VERSION ""

NS_ :

BS_:

BU_: L_3HKBD L_FHPTC L_2HKBD L_ATCU L_PCM L_EVNT L_HKBD L_RHPTC

BO_ 1032 L_EVNT_08: 8 L_EVNT
 SG_ L_EVNT_ATCUComFlt : 0|2@1+ (1,0) [0|0] ""  L_ATCU
 SG_ L_EVNT_DrvCntrHorComFlt : 10|2@1+ (1,0) [0|0] ""  L_ATCU
 SG_ L_EVNT_AstSdVertComFlt : 12|2@1+ (1,0) [0|0] ""  L_ATCU
 SG_ L_EVNT_AstSdHorComFlt : 14|2@1+ (1,0) [0|0] ""  L_ATCU
 SG_ L_EVNT_AstCntrVertComFlt : 16|2@1+ (1,0) [0|0] ""  L_ATCU
 SG_ L_EVNT_AstCntrHorComFlt : 18|2@1+ (1,0) [0|0] ""  L_ATCU
 SG_ L_EVNT_EVNTFlt : 2|2@1+ (1,0) [0|0] ""  L_ATCU
 SG_ L_EVNT_RrDrvCnslVertComFlt : 20|2@1+ (1,0) [0|0] ""  L_ATCU
 SG_ L_EVNT_RrDrvCnslHorComFlt : 22|2@1+ (1,0) [0|0] ""  L_ATCU
 SG_ L_EVNT_RrAstCnslVertComFlt : 24|2@1+ (1,0) [0|0] ""  L_ATCU
 SG_ L_EVNT_RrAstCnslHorComFlt : 26|2@1+ (1,0) [0|0] ""  L_ATCU
 SG_ L_EVNT_DrvSdVertIntFlt : 28|2@1+ (1,0) [0|0] ""  L_ATCU
 SG_ L_EVNT_DrvSdHorIntFlt : 30|2@1+ (1,0) [0|0] ""  L_ATCU
 SG_ L_EVNT_DrvCntrVertIntFlt : 32|2@1+ (1,0) [0|0] ""  L_ATCU
 SG_ L_EVNT_DrvCntrHorIntFlt : 34|2@1+ (1,0) [0|0] ""  L_ATCU
 SG_ L_EVNT_AstSdVertIntFlt : 36|2@1+ (1,0) [0|0] ""  L_ATCU
 SG_ L_EVNT_AstSdHorIntFlt : 38|2@1+ (1,0) [0|0] ""  L_ATCU
 SG_ L_EVNT_DrvSdVertComFlt : 4|2@1+ (1,0) [0|0] ""  L_ATCU
 SG_ L_EVNT_AstCntrVertIntFlt : 40|2@1+ (1,0) [0|0] ""  L_ATCU
 SG_ L_EVNT_AstCntrHorIntFlt : 42|2@1+ (1,0) [0|0] ""  L_ATCU
 SG_ L_EVNT_RrDrvCnslVertIntFlt : 44|2@1+ (1,0) [0|0] ""  L_ATCU
 SG_ L_EVNT_RrDrvCnslHorIntFlt : 46|2@1+ (1,0) [0|0] ""  L_ATCU
 SG_ L_EVNT_RrAstCnslVertIntFlt : 48|2@1+ (1,0) [0|0] ""  L_ATCU
 SG_ L_EVNT_RrAstCnslHorIntFlt : 50|2@1+ (1,0) [0|0] ""  L_ATCU
 SG_ L_EVNT_DrvSdVertExtFlt : 52|2@1+ (1,0) [0|0] ""  L_ATCU
 SG_ L_EVNT_DrvSdHorExtFlt : 54|2@1+ (1,0) [0|0] ""  L_ATCU
 SG_ L_EVNT_DrvCntrVertExtFlt : 56|2@1+ (1,0) [0|0] ""  L_ATCU
 SG_ L_EVNT_DrvCntrHorExtFlt : 58|2@1+ (1,0) [0|0] ""  L_ATCU
 SG_ L_EVNT_DrvSdHorComFlt : 6|2@1+ (1,0) [0|0] ""  L_ATCU
 SG_ L_EVNT_AstSdVertExtFlt : 60|2@1+ (1,0) [0|0] ""  L_ATCU
 SG_ L_EVNT_AstSdHorExtFlt : 62|2@1+ (1,0) [0|0] ""  L_ATCU
 SG_ L_EVNT_DrvCntrVertComFlt : 8|2@1+ (1,0) [0|0] ""  L_ATCU

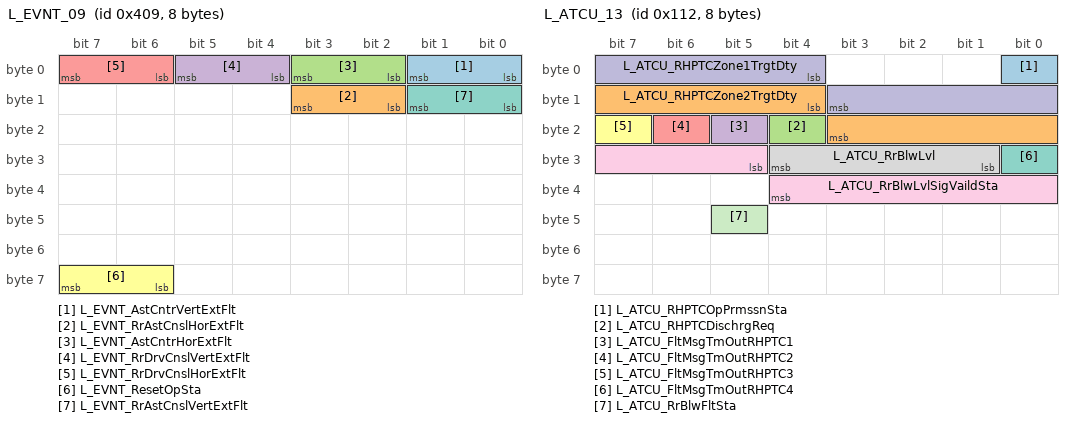
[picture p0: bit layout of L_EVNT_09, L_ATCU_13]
BO_ 1033 L_EVNT_09: 8 L_EVNT
 SG_ L_EVNT_AstCntrVertExtFlt : 0|2@1+ (1,0) [0|0] ""  L_ATCU
 SG_ L_EVNT_RrAstCnslHorExtFlt : 10|2@1+ (1,0) [0|0] ""  L_ATCU
 SG_ L_EVNT_AstCntrHorExtFlt : 2|2@1+ (1,0) [0|0] ""  L_ATCU
 SG_ L_EVNT_RrDrvCnslVertExtFlt : 4|2@1+ (1,0) [0|0] ""  L_ATCU
 SG_ L_EVNT_RrDrvCnslHorExtFlt : 6|2@1+ (1,0) [0|0] ""  L_ATCU
 SG_ L_EVNT_ResetOpSta : 62|2@1+ (1,0) [0|0] ""  L_ATCU
 SG_ L_EVNT_RrAstCnslVertExtFlt : 8|2@1+ (1,0) [0|0] ""  L_ATCU

BO_ 274 L_ATCU_13: 8 L_ATCU
 SG_ L_ATCU_RHPTCOpPrmssnSta : 0|1@1+ (1,0) [0|0] ""  L_FHPTC,L_RHPTC
 SG_ L_ATCU_RHPTCZone2TrgtDty : 12|8@1+ (0.5,0) [0|0] "%"  L_FHPTC,L_RHPTC
 SG_ L_ATCU_RHPTCDischrgReq : 20|1@1+ (1,0) [0|0] ""  L_FHPTC,L_RHPTC
 SG_ L_ATCU_FltMsgTmOutRHPTC1 : 21|1@1+ (1,0) [0|0] ""  L_FHPTC,L_RHPTC
 SG_ L_ATCU_FltMsgTmOutRHPTC2 : 22|1@1+ (1,0) [0|0] ""  L_FHPTC,L_RHPTC
 SG_ L_ATCU_FltMsgTmOutRHPTC3 : 23|1@1+ (1,0) [0|0] ""  L_FHPTC,L_RHPTC
 SG_ L_ATCU_FltMsgTmOutRHPTC4 : 24|1@1+ (1,0) [0|0] ""  L_FHPTC,L_RHPTC
 SG_ L_ATCU_RrBlwLvl : 25|4@1+ (1,0) [0|0] ""  L_EVNT,L_FHPTC,L_RHPTC
 SG_ L_ATCU_RrBlwLvlSigVaildSta : 29|8@1+ (1,0) [0|0] ""  L_FHPTC,L_RHPTC
 SG_ L_ATCU_RHPTCZone1TrgtDty : 4|8@1+ (0.5,0) [0|0] "%"  L_FHPTC,L_RHPTC
 SG_ L_ATCU_RrBlwFltSta : 45|1@1+ (1,0) [0|0] ""  L_FHPTC,L_RHPTC

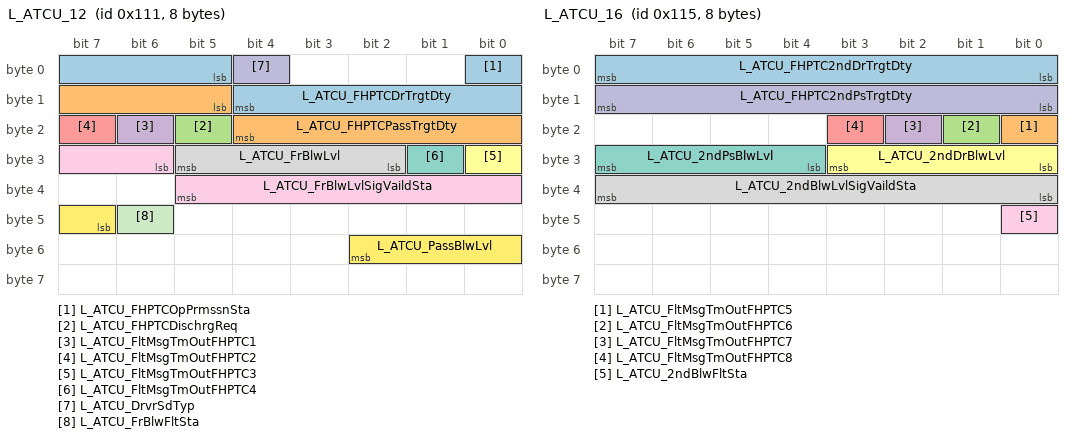
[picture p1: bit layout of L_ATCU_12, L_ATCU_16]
BO_ 273 L_ATCU_12: 8 L_ATCU
 SG_ L_ATCU_FHPTCOpPrmssnSta : 0|1@1+ (1,0) [0|0] ""  L_FHPTC,L_RHPTC
 SG_ L_ATCU_FHPTCPassTrgtDty : 13|8@1+ (0.5,0) [0|0] "%"  L_FHPTC,L_RHPTC
 SG_ L_ATCU_FHPTCDischrgReq : 21|1@1+ (1,0) [0|0] ""  L_FHPTC,L_RHPTC
 SG_ L_ATCU_FltMsgTmOutFHPTC1 : 22|1@1+ (1,0) [0|0] ""  L_FHPTC,L_RHPTC
 SG_ L_ATCU_FltMsgTmOutFHPTC2 : 23|1@1+ (1,0) [0|0] ""  L_FHPTC,L_RHPTC
 SG_ L_ATCU_FltMsgTmOutFHPTC3 : 24|1@1+ (1,0) [0|0] ""  L_FHPTC,L_RHPTC
 SG_ L_ATCU_FltMsgTmOutFHPTC4 : 25|1@1+ (1,0) [0|0] ""  L_FHPTC,L_RHPTC
 SG_ L_ATCU_FrBlwLvl : 26|4@1+ (1,0) [0|0] ""  L_EVNT,L_FHPTC,L_RHPTC
 SG_ L_ATCU_FrBlwLvlSigVaildSta : 30|8@1+ (1,0) [0|0] ""  L_FHPTC,L_RHPTC
 SG_ L_ATCU_DrvrSdTyp : 4|1@1+ (1,0) [0|0] ""  L_EVNT,L_FHPTC,L_HKBD,L_RHPTC
 SG_ L_ATCU_FrBlwFltSta : 46|1@1+ (1,0) [0|0] ""  L_FHPTC,L_RHPTC
 SG_ L_ATCU_PassBlwLvl : 47|4@1+ (1,0) [0|0] ""  L_EVNT,L_FHPTC,L_RHPTC
 SG_ L_ATCU_FHPTCDrTrgtDty : 5|8@1+ (0.5,0) [0|0] "%"  L_FHPTC,L_RHPTC

BO_ 277 L_ATCU_16: 8 L_ATCU
 SG_ L_ATCU_FHPTC2ndDrTrgtDty : 0|8@1+ (0.5,0) [0|0] "%"  L_FHPTC,L_RHPTC
 SG_ L_ATCU_FltMsgTmOutFHPTC5 : 16|1@1+ (1,0) [0|0] ""  L_FHPTC,L_RHPTC
 SG_ L_ATCU_FltMsgTmOutFHPTC6 : 17|1@1+ (1,0) [0|0] ""  L_FHPTC,L_RHPTC
 SG_ L_ATCU_FltMsgTmOutFHPTC7 : 18|1@1+ (1,0) [0|0] ""  L_FHPTC,L_RHPTC
 SG_ L_ATCU_FltMsgTmOutFHPTC8 : 19|1@1+ (1,0) [0|0] ""  L_FHPTC,L_RHPTC
 SG_ L_ATCU_2ndDrBlwLvl : 24|4@1+ (1,0) [0|0] ""  L_EVNT,L_FHPTC,L_RHPTC
 SG_ L_ATCU_2ndPsBlwLvl : 28|4@1+ (1,0) [0|0] ""  L_EVNT,L_FHPTC,L_RHPTC
 SG_ L_ATCU_2ndBlwLvlSigVaildSta : 32|8@1+ (1,0) [0|0] ""  L_FHPTC,L_RHPTC
 SG_ L_ATCU_2ndBlwFltSta : 40|1@1+ (1,0) [0|0] ""  L_FHPTC,L_RHPTC
 SG_ L_ATCU_FHPTC2ndPsTrgtDty : 8|8@1+ (0.5,0) [0|0] "%"  L_FHPTC,L_RHPTC

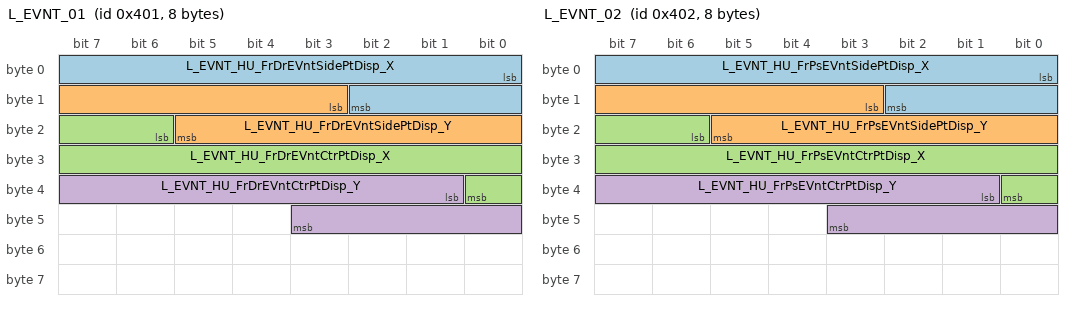
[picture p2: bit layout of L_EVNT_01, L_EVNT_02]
BO_ 1025 L_EVNT_01: 8 L_EVNT
 SG_ L_EVNT_HU_FrDrEVntSidePtDisp_X : 0|11@1+ (1,0) [0|0] ""  L_ATCU
 SG_ L_EVNT_HU_FrDrEVntSidePtDisp_Y : 11|11@1+ (1,0) [0|0] ""  L_ATCU
 SG_ L_EVNT_HU_FrDrEVntCtrPtDisp_X : 22|11@1+ (1,0) [0|0] ""  L_ATCU
 SG_ L_EVNT_HU_FrDrEVntCtrPtDisp_Y : 33|11@1+ (1,0) [0|0] ""  L_ATCU

BO_ 1026 L_EVNT_02: 8 L_EVNT
 SG_ L_EVNT_HU_FrPsEVntSidePtDisp_X : 0|11@1+ (1,0) [0|0] ""  L_ATCU
 SG_ L_EVNT_HU_FrPsEVntSidePtDisp_Y : 11|11@1+ (1,0) [0|0] ""  L_ATCU
 SG_ L_EVNT_HU_FrPsEVntCtrPtDisp_X : 22|11@1+ (1,0) [0|0] ""  L_ATCU
 SG_ L_EVNT_HU_FrPsEVntCtrPtDisp_Y : 33|11@1+ (1,0) [0|0] ""  L_ATCU

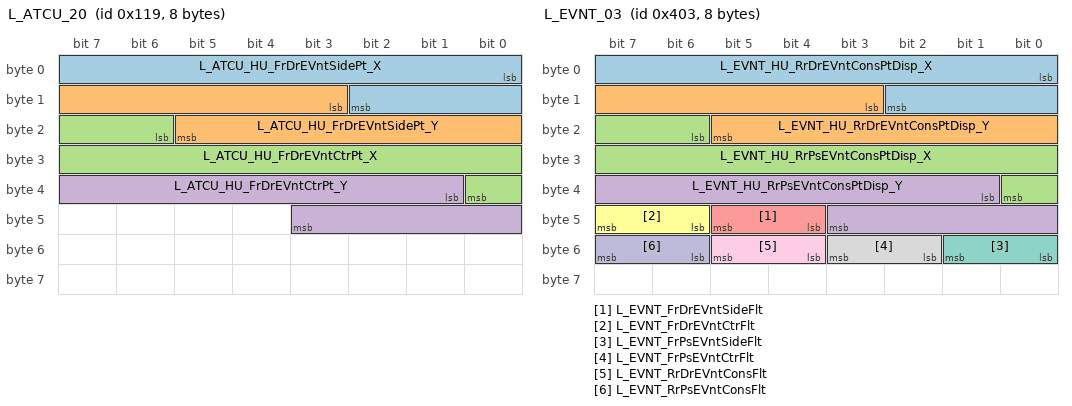
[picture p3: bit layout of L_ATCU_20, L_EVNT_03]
BO_ 281 L_ATCU_20: 8 L_ATCU
 SG_ L_ATCU_HU_FrDrEVntSidePt_X : 0|11@1+ (1,0) [0|0] ""  L_EVNT
 SG_ L_ATCU_HU_FrDrEVntSidePt_Y : 11|11@1+ (1,0) [0|0] ""  L_EVNT
 SG_ L_ATCU_HU_FrDrEVntCtrPt_X : 22|11@1+ (1,0) [0|0] ""  L_EVNT
 SG_ L_ATCU_HU_FrDrEVntCtrPt_Y : 33|11@1+ (1,0) [0|0] ""  L_EVNT

BO_ 1027 L_EVNT_03: 8 L_EVNT
 SG_ L_EVNT_HU_RrDrEVntConsPtDisp_X : 0|11@1+ (1,0) [0|0] ""  L_ATCU
 SG_ L_EVNT_HU_RrDrEVntConsPtDisp_Y : 11|11@1+ (1,0) [0|0] ""  L_ATCU
 SG_ L_EVNT_HU_RrPsEVntConsPtDisp_X : 22|11@1+ (1,0) [0|0] ""  L_ATCU
 SG_ L_EVNT_HU_RrPsEVntConsPtDisp_Y : 33|11@1+ (1,0) [0|0] ""  L_ATCU
 SG_ L_EVNT_FrDrEVntSideFlt : 44|2@1+ (1,0) [0|0] ""  L_ATCU
 SG_ L_EVNT_FrDrEVntCtrFlt : 46|2@1+ (1,0) [0|0] ""  L_ATCU
 SG_ L_EVNT_FrPsEVntSideFlt : 48|2@1+ (1,0) [0|0] ""  L_ATCU
 SG_ L_EVNT_FrPsEVntCtrFlt : 50|2@1+ (1,0) [0|0] ""  L_ATCU
 SG_ L_EVNT_RrDrEVntConsFlt : 52|2@1+ (1,0) [0|0] ""  L_ATCU
 SG_ L_EVNT_RrPsEVntConsFlt : 54|2@1+ (1,0) [0|0] ""  L_ATCU

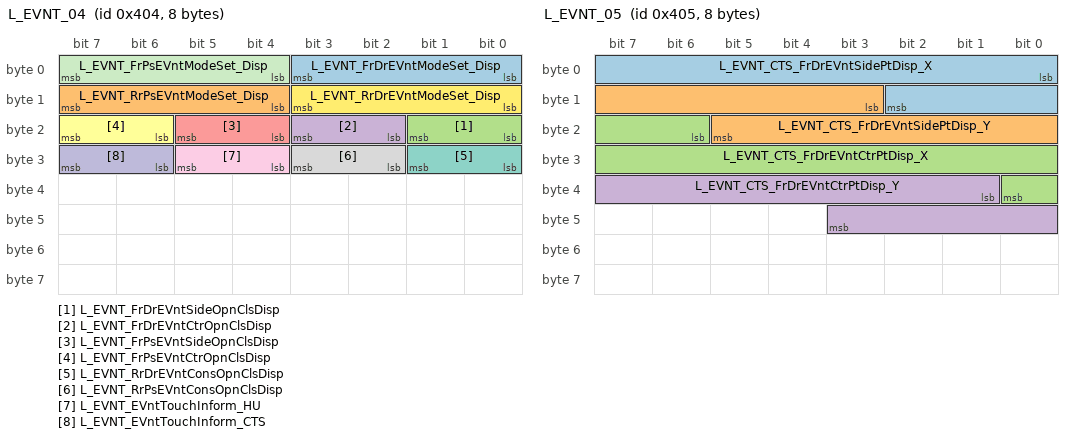
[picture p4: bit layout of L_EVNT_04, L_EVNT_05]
BO_ 1028 L_EVNT_04: 8 L_EVNT
 SG_ L_EVNT_FrDrEVntModeSet_Disp : 0|4@1+ (1,0) [0|0] ""  L_ATCU
 SG_ L_EVNT_RrPsEVntModeSet_Disp : 12|4@1+ (1,0) [0|0] ""  L_ATCU
 SG_ L_EVNT_FrDrEVntSideOpnClsDisp : 16|2@1+ (1,0) [0|0] ""  L_ATCU
 SG_ L_EVNT_FrDrEVntCtrOpnClsDisp : 18|2@1+ (1,0) [0|0] ""  L_ATCU
 SG_ L_EVNT_FrPsEVntSideOpnClsDisp : 20|2@1+ (1,0) [0|0] ""  L_ATCU
 SG_ L_EVNT_FrPsEVntCtrOpnClsDisp : 22|2@1+ (1,0) [0|0] ""  L_ATCU
 SG_ L_EVNT_RrDrEVntConsOpnClsDisp : 24|2@1+ (1,0) [0|0] ""  L_ATCU
 SG_ L_EVNT_RrPsEVntConsOpnClsDisp : 26|2@1+ (1,0) [0|0] ""  L_ATCU
 SG_ L_EVNT_EVntTouchInform_HU : 28|2@1+ (1,0) [0|0] ""  L_ATCU
 SG_ L_EVNT_EVntTouchInform_CTS : 30|2@1+ (1,0) [0|0] ""  L_ATCU
 SG_ L_EVNT_FrPsEVntModeSet_Disp : 4|4@1+ (1,0) [0|0] ""  L_ATCU
 SG_ L_EVNT_RrDrEVntModeSet_Disp : 8|4@1+ (1,0) [0|0] ""  L_ATCU

BO_ 1029 L_EVNT_05: 8 L_EVNT
 SG_ L_EVNT_CTS_FrDrEVntSidePtDisp_X : 0|11@1+ (1,0) [0|0] ""  L_ATCU
 SG_ L_EVNT_CTS_FrDrEVntSidePtDisp_Y : 11|11@1+ (1,0) [0|0] ""  L_ATCU
 SG_ L_EVNT_CTS_FrDrEVntCtrPtDisp_X : 22|11@1+ (1,0) [0|0] ""  L_ATCU
 SG_ L_EVNT_CTS_FrDrEVntCtrPtDisp_Y : 33|11@1+ (1,0) [0|0] ""  L_ATCU

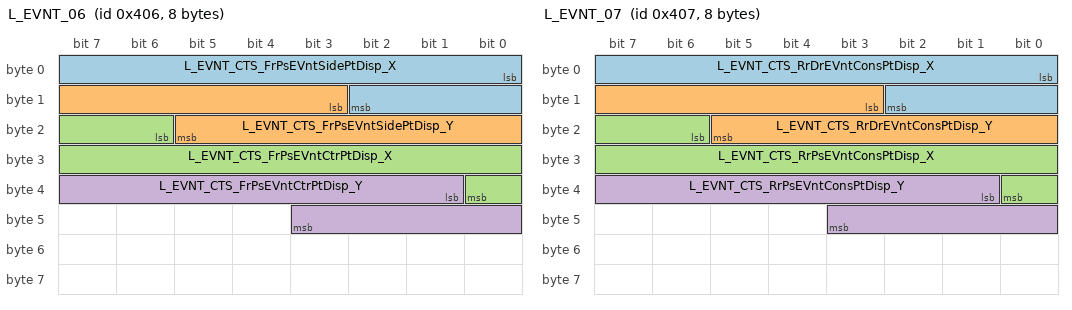
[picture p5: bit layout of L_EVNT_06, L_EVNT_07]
BO_ 1030 L_EVNT_06: 8 L_EVNT
 SG_ L_EVNT_CTS_FrPsEVntSidePtDisp_X : 0|11@1+ (1,0) [0|0] ""  L_ATCU
 SG_ L_EVNT_CTS_FrPsEVntSidePtDisp_Y : 11|11@1+ (1,0) [0|0] ""  L_ATCU
 SG_ L_EVNT_CTS_FrPsEVntCtrPtDisp_X : 22|11@1+ (1,0) [0|0] ""  L_ATCU
 SG_ L_EVNT_CTS_FrPsEVntCtrPtDisp_Y : 33|11@1+ (1,0) [0|0] ""  L_ATCU

BO_ 1031 L_EVNT_07: 8 L_EVNT
 SG_ L_EVNT_CTS_RrDrEVntConsPtDisp_X : 0|11@1+ (1,0) [0|0] ""  L_ATCU
 SG_ L_EVNT_CTS_RrDrEVntConsPtDisp_Y : 11|11@1+ (1,0) [0|0] ""  L_ATCU
 SG_ L_EVNT_CTS_RrPsEVntConsPtDisp_X : 22|11@1+ (1,0) [0|0] ""  L_ATCU
 SG_ L_EVNT_CTS_RrPsEVntConsPtDisp_Y : 33|11@1+ (1,0) [0|0] ""  L_ATCU

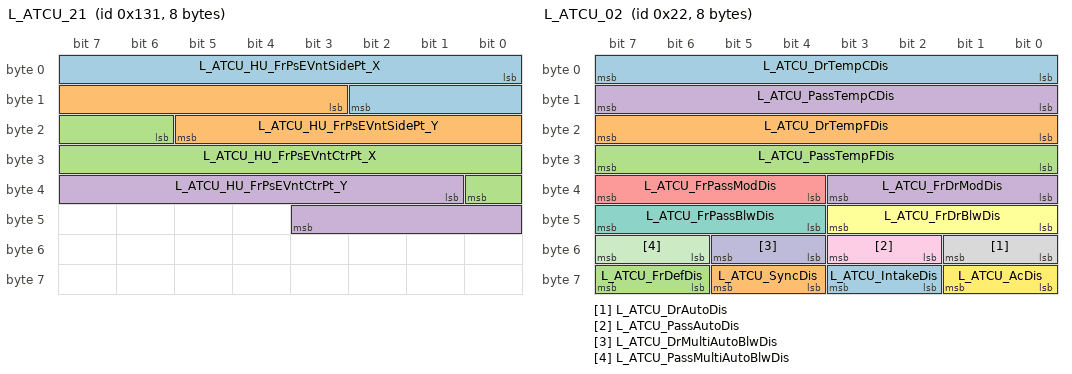
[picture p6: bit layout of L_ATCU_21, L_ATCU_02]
BO_ 305 L_ATCU_21: 8 L_ATCU
 SG_ L_ATCU_HU_FrPsEVntSidePt_X : 0|11@1+ (1,0) [0|0] ""  L_EVNT
 SG_ L_ATCU_HU_FrPsEVntSidePt_Y : 11|11@1+ (1,0) [0|0] ""  L_EVNT
 SG_ L_ATCU_HU_FrPsEVntCtrPt_X : 22|11@1+ (1,0) [0|0] ""  L_EVNT
 SG_ L_ATCU_HU_FrPsEVntCtrPt_Y : 33|11@1+ (1,0) [0|0] ""  L_EVNT

BO_ 34 L_ATCU_02: 8 L_ATCU
 SG_ L_ATCU_DrTempCDis : 0|8@1+ (0.5,14) [0|0] "¡É"  L_HKBD
 SG_ L_ATCU_DrTempFDis : 16|8@1+ (1,56) [0|0] "¢µ"  L_HKBD
 SG_ L_ATCU_PassTempFDis : 24|8@1+ (1,56) [0|0] "¢µ"  L_HKBD
 SG_ L_ATCU_FrDrModDis : 32|4@1+ (1,0) [0|0] ""  L_EVNT,L_HKBD
 SG_ L_ATCU_FrPassModDis : 36|4@1+ (1,0) [0|0] ""  L_EVNT,L_HKBD
 SG_ L_ATCU_FrDrBlwDis : 40|4@1+ (1,0) [0|0] ""  L_HKBD
 SG_ L_ATCU_FrPassBlwDis : 44|4@1+ (1,0) [0|0] ""  L_HKBD
 SG_ L_ATCU_DrAutoDis : 48|2@1+ (1,0) [0|0] ""  L_HKBD
 SG_ L_ATCU_PassAutoDis : 50|2@1+ (1,0) [0|0] ""  L_HKBD
 SG_ L_ATCU_DrMultiAutoBlwDis : 52|2@1+ (1,0) [0|0] ""  L_HKBD
 SG_ L_ATCU_PassMultiAutoBlwDis : 54|2@1+ (1,0) [0|0] ""  L_HKBD
 SG_ L_ATCU_AcDis : 56|2@1+ (1,0) [0|0] ""  L_HKBD
 SG_ L_ATCU_IntakeDis : 58|2@1+ (1,0) [0|0] ""  L_HKBD
 SG_ L_ATCU_SyncDis : 60|2@1+ (1,0) [0|0] ""  L_HKBD
 SG_ L_ATCU_FrDefDis : 62|2@1+ (1,0) [0|0] ""  L_HKBD
 SG_ L_ATCU_PassTempCDis : 8|8@1+ (0.5,14) [0|0] "¡É"  L_HKBD

BO_ 35 L_ATCU_03: 8 L_ATCU
 SG_ L_ATCU_DrOnlyDis : 0|2@1+ (1,0) [0|0] ""  L_HKBD
 SG_ L_ATCU_SmrtVntDis : 11|2@1+ (1,0) [0|0] ""  L_HKBD
 SG_ L_ATCU_FrWndShldHtInd : 13|2@1+ (1,0) [0|0] ""  L_HKBD
 SG_ L_ATCU_IncarMtrOnReq : 15|1@1+ (1,0) [0|0] ""  L_HKBD
 SG_ L_ATCU_LanguageInfo : 16|8@1+ (1,0) [0|0] ""  L_HKBD
 SG_ L_ATCU_RrDefInd : 2|1@1+ (1,0) [0|0] ""  L_HKBD
 SG_ L_ATCU_AfterBlowDisplay : 24|2@1+ (1,0) [0|0] ""  L_HKBD
 SG_ L_ATCU_SchdldVentDisplay : 26|2@1+ (1,0) [0|0] ""  L_HKBD
 SG_ L_ATCU_FLStHeatSwHInd : 28|1@1+ (1,0) [0|0] ""  L_HKBD
 SG_ L_ATCU_FLStHeatSwMInd : 29|1@1+ (1,0) [0|0] ""  L_HKBD
 SG_ L_ATCU_ADSBlinkDis : 3|2@1+ (1,0) [0|0] ""  L_HKBD
 SG_ L_ATCU_FLStHeatSwLInd : 30|1@1+ (1,0) [0|0] ""  L_HKBD
 SG_ L_ATCU_FLStVntSwHInd : 31|1@1+ (1,0) [0|0] ""  L_HKBD
 SG_ L_ATCU_FLStVntSwMInd : 32|1@1+ (1,0) [0|0] ""  L_HKBD
 SG_ L_ATCU_FLStVntSwLInd : 33|1@1+ (1,0) [0|0] ""  L_HKBD
 SG_ L_ATCU_FRStHeatSwHInd : 34|1@1+ (1,0) [0|0] ""  L_HKBD
 SG_ L_ATCU_FRStHeatSwMInd : 35|1@1+ (1,0) [0|0] ""  L_HKBD
 SG_ L_ATCU_FRStHeatSwLInd : 36|1@1+ (1,0) [0|0] ""  L_HKBD
 SG_ L_ATCU_FRStVntSwHInd : 37|1@1+ (1,0) [0|0] ""  L_HKBD
 SG_ L_ATCU_FRStVntSwMInd : 38|1@1+ (1,0) [0|0] ""  L_HKBD
 SG_ L_ATCU_FRStVntSwLInd : 39|1@1+ (1,0) [0|0] ""  L_HKBD
 SG_ L_ATCU_StrWhlHeatInd : 40|2@1+ (1,0) [0|0] ""  L_HKBD
 SG_ L_ATCU_RhstaLvlSta : 42|5@1+ (1,0) [0|0] ""  L_2HKBD,L_EVNT,L_HKBD
 SG_ L_ATCU_IntTailOnOff : 47|1@1+ (1,0) [0|0] ""  L_2HKBD,L_HKBD
 SG_ L_ATCU_AutoLightSta : 48|1@1+ (1,0) [0|0] ""  L_HKBD
 SG_ L_ATCU_FrBckLightSta : 49|1@1+ (1,0) [0|0] ""  L_HKBD
 SG_ L_ATCU_DisplayTheme : 50|2@1+ (1,0) [0|0] ""  L_HKBD
 SG_ L_ATCU_GUIBlankDis : 52|1@1+ (1,0) [0|0] ""  L_HKBD
 SG_ L_ATCU_HptIntnstySet : 53|4@1+ (1,0) [0|0] ""  L_HKBD
 SG_ L_ATCU_TlltLmpDis : 57|3@1+ (1,0) [0|0] ""  L_HKBD
 SG_ L_ATCU_AvTailOnOff : 60|1@1+ (1,0) [0|0] ""  L_HKBD
 SG_ L_ATCU_SchdldClimateDisplay : 61|2@1+ (1,0) [0|0] ""  L_HKBD
 SG_ L_ATCU_AirClnDis : 7|2@1+ (1,0) [0|0] ""  L_HKBD
 SG_ L_ATCU_CO2WrngDis : 9|2@1+ (1,0) [0|0] ""  L_HKBD

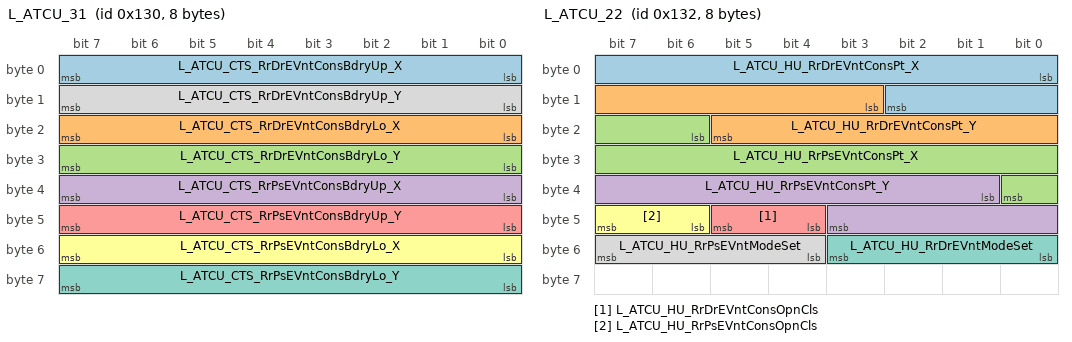
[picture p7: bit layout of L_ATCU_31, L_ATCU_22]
BO_ 304 L_ATCU_31: 8 L_ATCU
 SG_ L_ATCU_CTS_RrDrEVntConsBdryUp_X : 0|8@1+ (10,0) [0|0] ""  L_EVNT
 SG_ L_ATCU_CTS_RrDrEVntConsBdryLo_X : 16|8@1+ (10,0) [0|0] ""  L_EVNT
 SG_ L_ATCU_CTS_RrDrEVntConsBdryLo_Y : 24|8@1+ (10,0) [0|0] ""  L_EVNT
 SG_ L_ATCU_CTS_RrPsEVntConsBdryUp_X : 32|8@1+ (10,0) [0|0] ""  L_EVNT
 SG_ L_ATCU_CTS_RrPsEVntConsBdryUp_Y : 40|8@1+ (10,0) [0|0] ""  L_EVNT
 SG_ L_ATCU_CTS_RrPsEVntConsBdryLo_X : 48|8@1+ (10,0) [0|0] ""  L_EVNT
 SG_ L_ATCU_CTS_RrPsEVntConsBdryLo_Y : 56|8@1+ (10,0) [0|0] ""  L_EVNT
 SG_ L_ATCU_CTS_RrDrEVntConsBdryUp_Y : 8|8@1+ (10,0) [0|0] ""  L_EVNT

BO_ 306 L_ATCU_22: 8 L_ATCU
 SG_ L_ATCU_HU_RrDrEVntConsPt_X : 0|11@1+ (1,0) [0|0] ""  L_EVNT
 SG_ L_ATCU_HU_RrDrEVntConsPt_Y : 11|11@1+ (1,0) [0|0] ""  L_EVNT
 SG_ L_ATCU_HU_RrPsEVntConsPt_X : 22|11@1+ (1,0) [0|0] ""  L_EVNT
 SG_ L_ATCU_HU_RrPsEVntConsPt_Y : 33|11@1+ (1,0) [0|0] ""  L_EVNT
 SG_ L_ATCU_HU_RrDrEVntConsOpnCls : 44|2@1+ (1,0) [0|0] ""  L_EVNT
 SG_ L_ATCU_HU_RrPsEVntConsOpnCls : 46|2@1+ (1,0) [0|0] ""  L_EVNT
 SG_ L_ATCU_HU_RrDrEVntModeSet : 48|4@1+ (1,0) [0|0] ""  L_EVNT
 SG_ L_ATCU_HU_RrPsEVntModeSet : 52|4@1+ (1,0) [0|0] ""  L_EVNT

CM_ BO_ 34 "[PE] Periodic and On Event";
CM_ SG_ 34 L_ATCU_DrTempCDis "ATCU_DrvierTemperatureDisplay(¡É)";
CM_ SG_ 34 L_ATCU_DrTempFDis "ATCU_DriverTemperatureDisplay(¢µ)";
CM_ SG_ 34 L_ATCU_PassTempFDis "ATCU_PassengerTemperatureDisplay(¢µ)";
CM_ SG_ 34 L_ATCU_FrDrModDis "ATCU_FrontDriverModeDisplay";
CM_ SG_ 34 L_ATCU_FrPassModDis "ATCU_FrontPassengerModeDisplay";
CM_ SG_ 34 L_ATCU_FrDrBlwDis "ATCU_FrontDriverBlowerDisplay";
CM_ SG_ 34 L_ATCU_FrPassBlwDis "ATCU_FrontPassengerBlowerDisplay";
CM_ SG_ 34 L_ATCU_DrAutoDis "ATCU_DriverAutoDisplay";
CM_ SG_ 34 L_ATCU_PassAutoDis "ATCU_PassengerAutoDisplay";
CM_ SG_ 34 L_ATCU_DrMultiAutoBlwDis "ATCU_DriverMultiAutoBlowerDisplay";
CM_ SG_ 34 L_ATCU_PassMultiAutoBlwDis "ATCU_PassengerMultiAutoBlowerDisplay";
CM_ SG_ 34 L_ATCU_AcDis "ATCU_AcDisplay";
CM_ SG_ 34 L_ATCU_IntakeDis "ATCU_IntakeDisplay";
CM_ SG_ 34 L_ATCU_SyncDis "ATCU_SyncDisplay";
CM_ SG_ 34 L_ATCU_FrDefDis "ATCU_FrontDefrostDisplay";
CM_ SG_ 34 L_ATCU_PassTempCDis "ATCU_PassengerTemperatureDisplay(¡É)";
CM_ BO_ 35 "[PE] Periodic and On Event";
CM_ SG_ 35 L_ATCU_DrOnlyDis "ATCU_DriverOnlyDisplay";
CM_ SG_ 35 L_ATCU_SmrtVntDis "ATCU_SmartVentilationDisplay";
CM_ SG_ 35 L_ATCU_FrWndShldHtInd "ATCU_FrontWindShieldHeaterIndicator";
CM_ SG_ 35 L_ATCU_IncarMtrOnReq "ATCU_IncarMotorOnRequest";
CM_ SG_ 35 L_ATCU_LanguageInfo "ATCU_LanguageInformation";
CM_ SG_ 35 L_ATCU_RrDefInd "ATCU_RearDEFIndicator";
CM_ SG_ 35 L_ATCU_AfterBlowDisplay "ATCU_AfterBlow Display";
CM_ SG_ 35 L_ATCU_SchdldVentDisplay "ATCU_SchduledVentDispaly";
CM_ SG_ 35 L_ATCU_FLStHeatSwHInd "ATCU_FrontLeftSeatHeatSwitchHighIndicator";
CM_ SG_ 35 L_ATCU_FLStHeatSwMInd "ATCU_FrontLeftSeatHeatSwitchMiddleIndicator";
CM_ SG_ 35 L_ATCU_ADSBlinkDis "ATCU_ADSBlinkDisplay";
CM_ SG_ 35 L_ATCU_FLStHeatSwLInd "ATCU_FrontLeftSeatHeatSwitchLowIndicator";
CM_ SG_ 35 L_ATCU_FLStVntSwHInd "ATCU_FrontLeftSeatVentilationSwitchHighIndicator";
CM_ SG_ 35 L_ATCU_FLStVntSwMInd "ATCU_FrontLeftSeatVentilationSwitchMiddleIndicator";
CM_ SG_ 35 L_ATCU_FLStVntSwLInd "ATCU_FrontLeftSeatVentilationSwitchLowIndicator";
CM_ SG_ 35 L_ATCU_FRStHeatSwHInd "ATCU_FrontRightSeatHeatSwitchHighIndicator";
CM_ SG_ 35 L_ATCU_FRStHeatSwMInd "ATCU_FrontRightSeatHeatSwitchMiddleIndicator";
CM_ SG_ 35 L_ATCU_FRStHeatSwLInd "ATCU_FrontRightSeatHeatSwitchLowIndicator";
CM_ SG_ 35 L_ATCU_FRStVntSwHInd "ATCU_FrontRightSeatVentilationSwitchHighIndicator";
CM_ SG_ 35 L_ATCU_FRStVntSwMInd "ATCU_FrontRightSeatVentilationSwitchMiddleIndicator";
CM_ SG_ 35 L_ATCU_FRStVntSwLInd "ATCU_FrontRightSeatVentilationSwitchLowIndicator";
CM_ SG_ 35 L_ATCU_StrWhlHeatInd "ATCU_SteeringWheelHeatIndicator";
CM_ SG_ 35 L_ATCU_RhstaLvlSta "ATCU_RheostatLevelStatus";
CM_ SG_ 35 L_ATCU_IntTailOnOff "ATCU_InternalTailOnOff";
CM_ SG_ 35 L_ATCU_AutoLightSta "ATCU_AutoLightStatus";
CM_ SG_ 35 L_ATCU_FrBckLightSta "ATCU_FrontBackLightStatus";
CM_ SG_ 35 L_ATCU_DisplayTheme "ATCU_DisplayTheme";
CM_ SG_ 35 L_ATCU_GUIBlankDis "ATCU_GUIBlankDisplay";
CM_ SG_ 35 L_ATCU_HptIntnstySet "ATCU_HapticIntensityLevelSet";
CM_ SG_ 35 L_ATCU_TlltLmpDis "ATCU_TelltaleLampDisplay";
CM_ SG_ 35 L_ATCU_AvTailOnOff "ATCU_AVTailOnOff";
CM_ SG_ 35 L_ATCU_SchdldClimateDisplay "ATCU_ScheduledClimateDisplay";
CM_ SG_ 35 L_ATCU_AirClnDis "ATCU_AirCleaningDisplay";
CM_ SG_ 35 L_ATCU_CO2WrngDis "ATCU_CO2WarningDisplay";
CM_ BO_ 273 "[P] Periodic";
CM_ SG_ 273 L_ATCU_FHPTCOpPrmssnSta "ATCU_FHPTCOperationPermissionStatus";
CM_ SG_ 273 L_ATCU_FHPTCPassTrgtDty "ATCU_FHPTCPassengerTargetDuty";
CM_ SG_ 273 L_ATCU_FHPTCDischrgReq "ATCU_FHPTCDischrgeRequest";
CM_ SG_ 273 L_ATCU_FltMsgTmOutFHPTC1 "ATCU_FltMsgTmOutFHPTC1";
CM_ SG_ 273 L_ATCU_FltMsgTmOutFHPTC2 "ATCU_FltMsgTmOutFHPTC2";
CM_ SG_ 273 L_ATCU_FltMsgTmOutFHPTC3 "ATCU_FltMsgTmOutFHPTC3";
CM_ SG_ 273 L_ATCU_FltMsgTmOutFHPTC4 "ATCU_FltMsgTmOutFHPTC4";
CM_ SG_ 273 L_ATCU_FrBlwLvl "ATCU_FrBlowerLevel";
CM_ SG_ 273 L_ATCU_FrBlwLvlSigVaildSta "ATCU_FrBlowrLevelSignalVaildStatus";
CM_ SG_ 273 L_ATCU_DrvrSdTyp "ATCU_DriverSideType";
CM_ SG_ 273 L_ATCU_FrBlwFltSta "ATCU_FrontBlowerFaultStatus";
CM_ SG_ 273 L_ATCU_PassBlwLvl "ATCU_PasssengerBlowerLevel";
CM_ SG_ 273 L_ATCU_FHPTCDrTrgtDty "ATCU_FHPTCDriverTargetDuty";
CM_ BO_ 274 "[P] Periodic";
CM_ SG_ 274 L_ATCU_RHPTCOpPrmssnSta "ATCU_RHPTCOperationPermissionStatus";
CM_ SG_ 274 L_ATCU_RHPTCZone2TrgtDty "ATCU_RHPTCZone2TargetDuty";
CM_ SG_ 274 L_ATCU_RHPTCDischrgReq "ATCU_RHPTCDischrgeRequest";
CM_ SG_ 274 L_ATCU_FltMsgTmOutRHPTC1 "ATCU_FltMsgTmOutRHPTC1";
CM_ SG_ 274 L_ATCU_FltMsgTmOutRHPTC2 "ATCU_FltMsgTmOutRHPTC2";
CM_ SG_ 274 L_ATCU_FltMsgTmOutRHPTC3 "ATCU_FltMsgTmOutRHPTC3";
CM_ SG_ 274 L_ATCU_FltMsgTmOutRHPTC4 "ATCU_FltMsgTmOutRHPTC4";
CM_ SG_ 274 L_ATCU_RrBlwLvl "ATCU_RrBlowerLevel";
CM_ SG_ 274 L_ATCU_RrBlwLvlSigVaildSta "ATCU_RrBlowrLevelSignalVaildStatus";
CM_ SG_ 274 L_ATCU_RHPTCZone1TrgtDty "ATCU_RHPTCZone1TargetDuty";
CM_ SG_ 274 L_ATCU_RrBlwFltSta "ATCU_BlowerFaultStatus";
CM_ BO_ 277 "[P] Periodic";
CM_ SG_ 277 L_ATCU_FHPTC2ndDrTrgtDty "ATCU_FHPTC 2nd Driver Target Duty";
CM_ SG_ 277 L_ATCU_FltMsgTmOutFHPTC5 "ATCU_FltMsgTmOutFHPTC5";
CM_ SG_ 277 L_ATCU_FltMsgTmOutFHPTC6 "ATCU_FltMsgTmOutFHPTC6";
CM_ SG_ 277 L_ATCU_FltMsgTmOutFHPTC7 "ATCU_FltMsgTmOutFHPTC7";
CM_ SG_ 277 L_ATCU_FltMsgTmOutFHPTC8 "ATCU_FltMsgTmOutFHPTC8";
CM_ SG_ 277 L_ATCU_2ndDrBlwLvl "ATCU_2ndDriverBlowerLevel";
CM_ SG_ 277 L_ATCU_2ndPsBlwLvl "ATCU_2ndPassengerBlowerLevel";
CM_ SG_ 277 L_ATCU_2ndBlwLvlSigVaildSta "ATCU_2ndBlowerLevelSignalVaildStatus";
CM_ SG_ 277 L_ATCU_2ndBlwFltSta "ATCU_2ndBlowerFaultStatus";
CM_ SG_ 277 L_ATCU_FHPTC2ndPsTrgtDty "ATCU_FHPTC 2nd Passenger Target Duty";
CM_ BO_ 281 "[EC] On Event and On Change";
CM_ SG_ 281 L_ATCU_HU_FrDrEVntSidePt_X "Front Driver Electric Vent Side Touch Point  X Value";
CM_ SG_ 281 L_ATCU_HU_FrDrEVntSidePt_Y "Front Driver Electric Vent Side Touch Point  Y Value";
CM_ SG_ 281 L_ATCU_HU_FrDrEVntCtrPt_X "Front Driver Electric Vent Center Touch Point  X Value";
CM_ SG_ 281 L_ATCU_HU_FrDrEVntCtrPt_Y "Front Driver Electric Vent Center Touch Point  Y Value";
CM_ BO_ 305 "[EC] On Event and On Change";
CM_ SG_ 305 L_ATCU_HU_FrPsEVntSidePt_X "Front Passenger Electric Vent Side Touch Point  X Value";
CM_ SG_ 305 L_ATCU_HU_FrPsEVntSidePt_Y "Front Passenger Electric Vent Side Touch Point  Y Value";
CM_ SG_ 305 L_ATCU_HU_FrPsEVntCtrPt_X "Front Passenger Electric Center Vent Touch Point  X Value";
CM_ SG_ 305 L_ATCU_HU_FrPsEVntCtrPt_Y "Front Passenger Electric Center Vent Touch Point  Y Value";
CM_ BO_ 306 "[EC] On Event and On Change";
CM_ SG_ 306 L_ATCU_HU_RrDrEVntConsPt_X "Rear Driver Electric Vent Console Touch Point  X Value";
CM_ SG_ 306 L_ATCU_HU_RrDrEVntConsPt_Y "Rear Driver Electric Vent Console Touch Point  Y Value";
CM_ SG_ 306 L_ATCU_HU_RrPsEVntConsPt_X "Rear Passenger Electric Vent Console Touch Point  X Value";
CM_ SG_ 306 L_ATCU_HU_RrPsEVntConsPt_Y "Rear Passenger Electric Vent Console Touch Point  Y Value";
CM_ SG_ 306 L_ATCU_HU_RrDrEVntConsOpnCls "Rear Driver Electric Vent Console Open Close Signal";
CM_ SG_ 306 L_ATCU_HU_RrPsEVntConsOpnCls "Rear Passenger Electric Vent Console Open Close Signal";
CM_ SG_ 306 L_ATCU_HU_RrDrEVntModeSet "Rear Driver Electric Vent Mode Set";
CM_ SG_ 306 L_ATCU_HU_RrPsEVntModeSet "Rear Passenger Electric Vent Mode Set";
CM_ BO_ 304 "[P] Periodic";
CM_ SG_ 304 L_ATCU_CTS_RrDrEVntConsBdryUp_X "Rear Driver Electric Vent Console Boundary Upper X Point";
CM_ SG_ 304 L_ATCU_CTS_RrDrEVntConsBdryLo_X "Rear Driver Electric Vent Console Boundary Lower X Point";
CM_ SG_ 304 L_ATCU_CTS_RrDrEVntConsBdryLo_Y "Rear Driver Electric Vent Console Boundary Lower Y Point";
CM_ SG_ 304 L_ATCU_CTS_RrPsEVntConsBdryUp_X "Rear Passenger Electric Vent Console Boundary Upper X Point";
CM_ SG_ 304 L_ATCU_CTS_RrPsEVntConsBdryUp_Y "Rear Passenger Electric Vent Console Boundary Upper Y Point";
CM_ SG_ 304 L_ATCU_CTS_RrPsEVntConsBdryLo_X "Rear Passenger Electric Vent Console Boundary Lower X Point";
CM_ SG_ 304 L_ATCU_CTS_RrPsEVntConsBdryLo_Y "Rear Passenger Electric Vent Console Boundary Lower Y Point";
CM_ SG_ 304 L_ATCU_CTS_RrDrEVntConsBdryUp_Y "Rear Driver Electric Vent Console Boundary Upper Y Point";
CM_ BO_ 1025 "[PE] Periodic and On Event";
CM_ SG_ 1025 L_EVNT_HU_FrDrEVntSidePtDisp_X "Front Driver Electric Vent Side Touch Point  X Value Display Feedback";
CM_ SG_ 1025 L_EVNT_HU_FrDrEVntSidePtDisp_Y "Front Driver Electric Vent Side Touch Point  Y Value Display Feedback";
CM_ SG_ 1025 L_EVNT_HU_FrDrEVntCtrPtDisp_X "Front Driver Electric Vent Center Touch Point  X Value Display Feedback";
CM_ SG_ 1025 L_EVNT_HU_FrDrEVntCtrPtDisp_Y "Front Driver Electric Vent Center Touch Point  Y Value Display Feedback";
CM_ BO_ 1026 "[PE] Periodic and On Event";
CM_ SG_ 1026 L_EVNT_HU_FrPsEVntSidePtDisp_X "Front Passenger Electric Vent Side Touch Point  X Value Display Feedback";
CM_ SG_ 1026 L_EVNT_HU_FrPsEVntSidePtDisp_Y "Front Passenger Electric Vent Side Touch Point  Y Value Display Feedback";
CM_ SG_ 1026 L_EVNT_HU_FrPsEVntCtrPtDisp_X "Front Passenger Electric Center Vent Touch Point  X Value Display Feedback";
CM_ SG_ 1026 L_EVNT_HU_FrPsEVntCtrPtDisp_Y "Front Passenger Electric Center Vent Touch Point  Y Value Display Feedback";
CM_ BO_ 1027 "[PE] Periodic and On Event";
CM_ SG_ 1027 L_EVNT_HU_RrDrEVntConsPtDisp_X "Rear Driver Electric Vent Console Touch Point  X Value Display Feedback";
CM_ SG_ 1027 L_EVNT_HU_RrDrEVntConsPtDisp_Y "Rear Driver Electric Vent Console Touch Point  Y Value Display Feedback";
CM_ SG_ 1027 L_EVNT_HU_RrPsEVntConsPtDisp_X "Rear Passenger Electric Vent Console Touch Point  X Value Display Feedback";
CM_ SG_ 1027 L_EVNT_HU_RrPsEVntConsPtDisp_Y "Rear Passenger Electric Vent Console Touch Point  Y Value Display Feedback";
CM_ SG_ 1027 L_EVNT_FrDrEVntSideFlt "Front Driver Electric Vent Side Fault Status";
CM_ SG_ 1027 L_EVNT_FrDrEVntCtrFlt "Front Driver Electric Vent Center Fault Status";
CM_ SG_ 1027 L_EVNT_FrPsEVntSideFlt "Front Passenger Electric Vent Side Fault Status";
CM_ SG_ 1027 L_EVNT_FrPsEVntCtrFlt "Front Passenger Electric Vent Center Fault Status";
CM_ SG_ 1027 L_EVNT_RrDrEVntConsFlt "Front Rear (2nd) Driver Electric Vent Console Fault Status";
CM_ SG_ 1027 L_EVNT_RrPsEVntConsFlt "Front Rear (2nd) Passenger Electric Vent Console Fault Status";
CM_ BO_ 1028 "[PE] Periodic and On Event";
CM_ SG_ 1028 L_EVNT_FrDrEVntModeSet_Disp "Front Driver Electric Vent Mode Display";
CM_ SG_ 1028 L_EVNT_RrPsEVntModeSet_Disp "Rear Passenger Electric Vent Mode Display";
CM_ SG_ 1028 L_EVNT_FrDrEVntSideOpnClsDisp "Front Driver Electric Vent Side Open Close Display";
CM_ SG_ 1028 L_EVNT_FrDrEVntCtrOpnClsDisp "Front Driver Electric Vent Center Open Close Display";
CM_ SG_ 1028 L_EVNT_FrPsEVntSideOpnClsDisp "Front Passenger Electric Vent Side Open Close Display";
CM_ SG_ 1028 L_EVNT_FrPsEVntCtrOpnClsDisp "Front Passenger Electric Vent Center Open Close Display";
CM_ SG_ 1028 L_EVNT_RrDrEVntConsOpnClsDisp "Rear Driver Electric Vent Console Open Close Display";
CM_ SG_ 1028 L_EVNT_RrPsEVntConsOpnClsDisp "Rear Passenger Electric Vent Open Console Close Display";
CM_ SG_ 1028 L_EVNT_EVntTouchInform_HU "Reply signal indicating whether to allow duplicate input signals for preventing overlapping of electric vent input signals";
CM_ SG_ 1028 L_EVNT_EVntTouchInform_CTS "Reply signal indicating whether to allow duplicate input signals for preventing overlapping of electric vent input signals";
CM_ SG_ 1028 L_EVNT_FrPsEVntModeSet_Disp "Front Passenger Electric Vent Mode Display";
CM_ SG_ 1028 L_EVNT_RrDrEVntModeSet_Disp "Rear Driver Electric Vent Mode Display";
CM_ BO_ 1029 "[PE] Periodic and On Event";
CM_ SG_ 1029 L_EVNT_CTS_FrDrEVntSidePtDisp_X "Front Driver Electric Vent Side Touch Point  X Value Display Feedback";
CM_ SG_ 1029 L_EVNT_CTS_FrDrEVntSidePtDisp_Y "Front Driver Electric Vent Side Touch Point  Y Value Display Feedback";
CM_ SG_ 1029 L_EVNT_CTS_FrDrEVntCtrPtDisp_X "Front Driver Electric Vent Center Touch Point  X Value Display Feedback";
CM_ SG_ 1029 L_EVNT_CTS_FrDrEVntCtrPtDisp_Y "Front Driver Electric Vent Center Touch Point  Y Value Display Feedback";
CM_ BO_ 1030 "[PE] Periodic and On Event";
CM_ SG_ 1030 L_EVNT_CTS_FrPsEVntSidePtDisp_X "Front Passenger Electric Vent Side Touch Point  X Value Display Feedback";
CM_ SG_ 1030 L_EVNT_CTS_FrPsEVntSidePtDisp_Y "Front Passenger Electric Vent Side Touch Point  Y Value Display Feedback";
CM_ SG_ 1030 L_EVNT_CTS_FrPsEVntCtrPtDisp_X "Front Passenger Electric Center Vent Touch Point  X Value Display Feedback";
CM_ SG_ 1030 L_EVNT_CTS_FrPsEVntCtrPtDisp_Y "Front Passenger Electric Center Vent Touch Point  Y Value Display Feedback";
CM_ BO_ 1031 "[PE] Periodic and On Event";
CM_ SG_ 1031 L_EVNT_CTS_RrDrEVntConsPtDisp_X "Rear Driver Electric Vent Console Touch Point  X Value Display Feedback";
CM_ SG_ 1031 L_EVNT_CTS_RrDrEVntConsPtDisp_Y "Rear Driver Electric Vent Console Touch Point  Y Value Display Feedback";
CM_ SG_ 1031 L_EVNT_CTS_RrPsEVntConsPtDisp_X "Rear Passenger Electric Vent Console Touch Point  X Value Display Feedback";
CM_ SG_ 1031 L_EVNT_CTS_RrPsEVntConsPtDisp_Y "Rear Passenger Electric Vent Console Touch Point  Y Value Display Feedback";
CM_ BO_ 1032 "[PE] Periodic and On Event";
CM_ SG_ 1032 L_EVNT_ATCUComFlt "ATCU fault decision of EVNT";
CM_ SG_ 1032 L_EVNT_DrvCntrHorComFlt "LIN-Bus Off DrvierCenter Left/Right - Actuator";
CM_ SG_ 1032 L_EVNT_AstSdVertComFlt "LIN-Bus Off PassengerSide Up/Down -Actuator";
CM_ SG_ 1032 L_EVNT_AstSdHorComFlt "LIN-Bus Off PassengerSide Left/Right - Actuator";
CM_ SG_ 1032 L_EVNT_AstCntrVertComFlt "LIN-Bus Off PassengerCenter Up/Down - Actuator";
CM_ SG_ 1032 L_EVNT_AstCntrHorComFlt "LIN-Bus Off PassengerCenter Left/Right - Actuator";
CM_ SG_ 1032 L_EVNT_EVNTFlt "EVNT fault decision of ATCU";
CM_ SG_ 1032 L_EVNT_RrDrvCnslVertComFlt "LIN-Bus Off RearDrvierCenter Up/Down -Actuator";
CM_ SG_ 1032 L_EVNT_RrDrvCnslHorComFlt "LIN-Bus Off RearDrvierCenter Left/Right -Actuator";
CM_ SG_ 1032 L_EVNT_RrAstCnslVertComFlt "LIN-Bus Off RearPassengerCenter Up/Down -Actuator";
CM_ SG_ 1032 L_EVNT_RrAstCnslHorComFlt "LIN-Bus Off RearPassengerCenter Left/Right -Actuator";
CM_ SG_ 1032 L_EVNT_DrvSdVertIntFlt "DrvierSide Up/Down - Actuator(Internal Error Flag)";
CM_ SG_ 1032 L_EVNT_DrvSdHorIntFlt "DrvierSide Left/Right -Actuator(Internal Error Flag)";
CM_ SG_ 1032 L_EVNT_DrvCntrVertIntFlt "DrvierCenter Up/Down -Actuator(Internal Error Flag)";
CM_ SG_ 1032 L_EVNT_DrvCntrHorIntFlt "DrvierCenter Left/Right - Actuator(Internal Error Flag)";
CM_ SG_ 1032 L_EVNT_AstSdVertIntFlt "PassengerSide Up/Down -Actuator(Internal Error Flag)";
CM_ SG_ 1032 L_EVNT_AstSdHorIntFlt "PassengerSide Left/Right - Actuator(Internal Error Flag)";
CM_ SG_ 1032 L_EVNT_DrvSdVertComFlt "LIN-Bus Off DrvierSide Up/Down - Actuator";
CM_ SG_ 1032 L_EVNT_AstCntrVertIntFlt "PassengerCenter Up/Down - Actuator(Internal Error Flag)";
CM_ SG_ 1032 L_EVNT_AstCntrHorIntFlt "PassengerCenter Left/Right - Actuator(Internal Error Flag)";
CM_ SG_ 1032 L_EVNT_RrDrvCnslVertIntFlt "RearDrvierCenter Up/Down -Actuator(Internal Error Flag)";
CM_ SG_ 1032 L_EVNT_RrDrvCnslHorIntFlt "RearDrvierCenter Left/Right -Actuator(Internal Error Flag)";
CM_ SG_ 1032 L_EVNT_RrAstCnslVertIntFlt "RearPassengerCenter Up/Down -Actuator(Internal Error Flag)";
CM_ SG_ 1032 L_EVNT_RrAstCnslHorIntFlt "RearPassengerCenter Left/Right -Actuator(Internal Error Flag)";
CM_ SG_ 1032 L_EVNT_DrvSdVertExtFlt "DrvierSide Up/Down - Actuator(External Error Flag)";
CM_ SG_ 1032 L_EVNT_DrvSdHorExtFlt "DrvierSide Left/Right -Actuator(External Error Flag)";
CM_ SG_ 1032 L_EVNT_DrvCntrVertExtFlt "DrvierCenter Up/Down -Actuator(External Error Flag)";
CM_ SG_ 1032 L_EVNT_DrvCntrHorExtFlt "DrvierCenter Left/Right - Actuator(External Error Flag)";
CM_ SG_ 1032 L_EVNT_DrvSdHorComFlt "LIN-Bus Off DrvierSide Left/Right -Actuator";
CM_ SG_ 1032 L_EVNT_AstSdVertExtFlt "PassengerSide Up/Down -Actuator(External Error Flag)";
CM_ SG_ 1032 L_EVNT_AstSdHorExtFlt "PassengerSide Left/Right - Actuator(External Error Flag)";
CM_ SG_ 1032 L_EVNT_DrvCntrVertComFlt "LIN-Bus Off DrvierCenter Up/Down -Actuator";
CM_ BO_ 1033 "[PE] Periodic and On Event";
CM_ SG_ 1033 L_EVNT_AstCntrVertExtFlt "PassengerCenter Up/Down - Actuator(External Error Flag)";
CM_ SG_ 1033 L_EVNT_RrAstCnslHorExtFlt "RearPassengerCenter Left/Right -Actuator(External Error Flag)";
CM_ SG_ 1033 L_EVNT_AstCntrHorExtFlt "PassengerCenter Left/Right - Actuator(External Error Flag)";
CM_ SG_ 1033 L_EVNT_RrDrvCnslVertExtFlt "RearDrvierCenter Up/Down -Actuator(External Error Flag)";
CM_ SG_ 1033 L_EVNT_RrDrvCnslHorExtFlt "RearDrvierCenter Left/Right -Actuator(External Error Flag)";
CM_ SG_ 1033 L_EVNT_ResetOpSta "This signal indicates whether the reset operation has been completed or not";
CM_ SG_ 1033 L_EVNT_RrAstCnslVertExtFlt "RearPassengerCenter Up/Down -Actuator(External Error Flag)";
BA_DEF_ BO_ "UsrMsgIDSforwardDeviation" INT 0 100 ;
BA_DEF_ BO_ "UsrMsgIDSbackwardDeviation" INT 50 1000 ;
BA_DEF_ "BusType" STRING ;
BA_DEF_ "DBName" STRING ;
BA_DEF_ "Baudrate" INT 50000 1000000 ;
BA_DEF_ "GenEnvVarEndingDsp" STRING ;
BA_DEF_ "GenEnvVarEndingSnd" STRING ;
BA_DEF_ "GenEnvVarPrefix" STRING ;
BA_DEF_ "GenNWMApBusSleep" STRING ;
BA_DEF_ "GenNWMApCanNormal" STRING ;
BA_DEF_ "GenNWMApCanOff" STRING ;
BA_DEF_ "GenNWMApCanOn" STRING ;
BA_DEF_ "GenNWMApCanSleep" STRING ;
BA_DEF_ "GenNWMApCanWakeUp" STRING ;
BA_DEF_ "GenNWMGotoMode_Awake" STRING ;
BA_DEF_ "GenNWMGotoMode_BusSleep" STRING ;
BA_DEF_ "GenNWMSleepTime" INT 1375 1650 ;
BA_DEF_ "GenNWMTalkNM" STRING ;
BA_DEF_ "Manufacturer" STRING ;
BA_DEF_ "NmBaseAddress" HEX 0 2047 ;
BA_DEF_ "NmMessageCount" INT 0 128 ;
BA_DEF_ "NmType" STRING ;
BA_DEF_ "SamplePointMax" INT 50 85 ;
BA_DEF_ "SamplePointMin" INT 55 85 ;
BA_DEF_ "SyncJumpWidthMax" INT 1 8 ;
BA_DEF_ "SyncJumpWidthMin" INT 1 4 ;
BA_DEF_ "VersionDay" INT 1 31 ;
BA_DEF_ "VersionMonth" INT 1 12 ;
BA_DEF_ "VersionNumber" INT 0 999999 ;
BA_DEF_ "VersionNumberInternal" INT 0 9999 ;
BA_DEF_ "VersionWeek" INT 1 53 ;
BA_DEF_ "VersionYear" INT 0 9999 ;
BA_DEF_ BU_ "NmStationAddress" HEX 0 255 ;
BA_DEF_ BU_ "NmNode" ENUM "No","Yes" ;
BA_DEF_ BU_ "GenNodSleepTime" INT 1375 1650 ;
BA_DEF_ BU_ "ILUsed" ENUM "No","Yes" ;
BA_DEF_ BU_ "NmCAN" INT 1 2 ;
BA_DEF_ BU_ "NodeLayerModules" STRING ;
BA_DEF_ BU_ "NWM_Knoten" ENUM "No","Yes" ;
BA_DEF_ BO_ "GenMsgCycleTime" INT 0 2000 ;
BA_DEF_ BO_ "GenMsgStartDelayTime" INT 0 2000 ;
BA_DEF_ BO_ "GenMsgSendType" ENUM "Cyclic","NoMsgSendType" ;
BA_DEF_ BO_ "GenMsgCycleTimeFast" INT 0 500 ;
BA_DEF_ BO_ "GenMsgDelayTime" INT 0 20 ;
BA_DEF_ BO_ "GenMsgILSupport" ENUM "No","Yes" ;
BA_DEF_ BO_ "GenMsgNrOfRepetition" INT 0 3 ;
BA_DEF_ BO_ "VFrameFormat" ENUM "StandardCAN","ExtendedCAN","reserved","reserved","reserved","reserved","reserved","reserved","reserved","reserved","reserved","reserved","reserved","reserved","StandardCAN_FD","ExtendedCAN_FD" ;
BA_DEF_ SG_ "UserSigValidity" ENUM "B+","ACC","IG","IG1","IG2","IG3","IG1 or IG2","IG1 or IG3","Undef" ;
BA_DEF_ SG_ "UsrSigPurpose" ENUM "Undef","FN","DIAG","DIAG(Req)","DIAG(Res)","DIAG(Phy)","DEV","CCP(Req)","CCP(Res)","NM","TP" ;
BA_DEF_ SG_ "GenSigStartValue" INT 0 1215752192 ;
BA_DEF_ SG_ "NetworkRequestHoldingTime" INT 0 65535 ;
BA_DEF_ SG_ "Description" STRING ;
BA_DEF_ SG_ "Version" STRING ;
BA_DEF_ SG_ "GenSigEnvVarType" ENUM "Int","Float","Undef" ;
BA_DEF_ SG_ "GenSigSendType" ENUM "Cyclic","OnWrite","OnWriteWithRepetition","OnChange","OnChangeWithRepetition","IfActive","IfActiveWithRepetition","NoSigSendType","OnChangeAndIfActive","OnChangeAndIfActiveWithRepetition" ;
BA_DEF_ SG_ "GwSigLatencyTime" INT 0 65536 ;
BA_DEF_ SG_ "GwSigMissingSourceType" ENUM "Undef","OldValue","DefaultValue","InitialValue" ;
BA_DEF_ SG_ "NWM-WakeupAllowed" ENUM "<n.a.>" ;
BA_DEF_ SG_ "RoutingFactor" INT 1 1215752192 ;
BA_DEF_REL_ BU_SG_REL_ "GenSigTimeoutTime" INT 0 7000 ;
BA_DEF_DEF_ "UsrMsgIDSforwardDeviation" 10 ;
BA_DEF_DEF_ "UsrMsgIDSbackwardDeviation" 100 ;
BA_DEF_DEF_ "BusType" "CAN" ;
BA_DEF_DEF_ "DBName" "" ;
BA_DEF_DEF_ "Baudrate" 500000 ;
BA_DEF_DEF_ "GenEnvVarEndingDsp" "Dsp_" ;
BA_DEF_DEF_ "GenEnvVarEndingSnd" "_" ;
BA_DEF_DEF_ "GenEnvVarPrefix" "Env" ;
BA_DEF_DEF_ "GenNWMApBusSleep" "AppNmCanBusSleep()" ;
BA_DEF_DEF_ "GenNWMApCanNormal" "AppNmCanNormal()" ;
BA_DEF_DEF_ "GenNWMApCanOff" "ApplCanOffline()" ;
BA_DEF_DEF_ "GenNWMApCanOn" "ApplCanOnline()" ;
BA_DEF_DEF_ "GenNWMApCanSleep" "ApplNmCanSleep()" ;
BA_DEF_DEF_ "GenNWMApCanWakeUp" "ApplCanWakeUp()" ;
BA_DEF_DEF_ "GenNWMGotoMode_Awake" "GotoMode_Awake()" ;
BA_DEF_DEF_ "GenNWMGotoMode_BusSleep" "GotoMode_BusSleep()" ;
BA_DEF_DEF_ "GenNWMSleepTime" 1500 ;
BA_DEF_DEF_ "GenNWMTalkNM" "TalkNM()" ;
BA_DEF_DEF_ "Manufacturer" "HMC" ;
BA_DEF_DEF_ "NmBaseAddress" 1280 ;
BA_DEF_DEF_ "NmMessageCount" 128 ;
BA_DEF_DEF_ "NmType" "Vector" ;
BA_DEF_DEF_ "SamplePointMax" 80 ;
BA_DEF_DEF_ "SamplePointMin" 80 ;
BA_DEF_DEF_ "SyncJumpWidthMax" 3 ;
BA_DEF_DEF_ "SyncJumpWidthMin" 2 ;
BA_DEF_DEF_ "VersionDay" 1 ;
BA_DEF_DEF_ "VersionMonth" 1 ;
BA_DEF_DEF_ "VersionNumber" 0 ;
BA_DEF_DEF_ "VersionNumberInternal" 0 ;
BA_DEF_DEF_ "VersionWeek" 1 ;
BA_DEF_DEF_ "VersionYear" 0 ;
BA_DEF_DEF_ "NmStationAddress" 0 ;
BA_DEF_DEF_ "NmNode" "Yes" ;
BA_DEF_DEF_ "GenNodSleepTime" 1500 ;
BA_DEF_DEF_ "ILUsed" "Yes" ;
BA_DEF_DEF_ "NmCAN" 1 ;
BA_DEF_DEF_ "NodeLayerModules" "oseknm01.dll,CANoeILNLVector.dll" ;
BA_DEF_DEF_ "NWM_Knoten" "Yes" ;
BA_DEF_DEF_ "GenMsgCycleTime" 200 ;
BA_DEF_DEF_ "GenMsgStartDelayTime" 0 ;
BA_DEF_DEF_ "GenMsgSendType" "NoMsgSendType" ;
BA_DEF_DEF_ "GenMsgCycleTimeFast" 40 ;
BA_DEF_DEF_ "GenMsgDelayTime" 20 ;
BA_DEF_DEF_ "GenMsgILSupport" "Yes" ;
BA_DEF_DEF_ "GenMsgNrOfRepetition" 3 ;
BA_DEF_DEF_ "VFrameFormat" "StandardCAN" ;
BA_DEF_DEF_ "UserSigValidity" "IG" ;
BA_DEF_DEF_ "UsrSigPurpose" "FN" ;
BA_DEF_DEF_ "GenSigStartValue" 0 ;
BA_DEF_DEF_ "NetworkRequestHoldingTime" 0 ;
BA_DEF_DEF_ "Description" "" ;
BA_DEF_DEF_ "Version" "" ;
BA_DEF_DEF_ "GenSigEnvVarType" "Undef" ;
BA_DEF_DEF_ "GenSigSendType" "NoSigSendType" ;
BA_DEF_DEF_ "GwSigLatencyTime" 40 ;
BA_DEF_DEF_ "GwSigMissingSourceType" "Undef" ;
BA_DEF_DEF_ "NWM-WakeupAllowed" "<n.a.>" ;
BA_DEF_DEF_ "RoutingFactor" 1 ;
BA_DEF_DEF_REL_ "GenSigTimeoutTime" 500 ;
BA_ "DBName" "Local_HS";
BA_ "VersionYear" 1;
BA_ "VersionNumber" 241101;
BA_ "NmNode" BU_ L_ATCU 0;
BA_ "GenMsgSendType" BO_ 34 0;
BA_ "NmNode" BU_ L_HKBD 0;
BA_ "Description" SG_ 34 L_ATCU_DrTempCDis "This signal indicates Outside temperature (¡É).

(Use for display only)";
BA_ "GenSigSendType" SG_ 34 L_ATCU_DrTempCDis 4;
BA_ "UserSigValidity" SG_ 34 L_ATCU_DrTempCDis 7;
BA_REL_ "GenSigTimeoutTime" BU_SG_REL_ L_HKBD SG_ 34 L_ATCU_DrTempCDis 1500;
BA_ "Version" SG_ 34 L_ATCU_DrTempCDis "23.08.13";
BA_ "GenSigSendType" SG_ 34 L_ATCU_DrTempFDis 4;
BA_ "UserSigValidity" SG_ 34 L_ATCU_DrTempFDis 7;
BA_REL_ "GenSigTimeoutTime" BU_SG_REL_ L_HKBD SG_ 34 L_ATCU_DrTempFDis 1500;
BA_ "Version" SG_ 34 L_ATCU_DrTempFDis "23.08.13";
BA_ "GenSigSendType" SG_ 34 L_ATCU_PassTempFDis 4;
BA_ "UserSigValidity" SG_ 34 L_ATCU_PassTempFDis 7;
BA_REL_ "GenSigTimeoutTime" BU_SG_REL_ L_HKBD SG_ 34 L_ATCU_PassTempFDis 1500;
BA_ "Version" SG_ 34 L_ATCU_PassTempFDis "23.08.13";
BA_ "NmNode" BU_ L_EVNT 0;
BA_ "Description" SG_ 34 L_ATCU_FrDrModDis "ATCU_FrontDriverModeDisplay";
BA_ "GenSigSendType" SG_ 34 L_ATCU_FrDrModDis 4;
BA_ "UserSigValidity" SG_ 34 L_ATCU_FrDrModDis 7;
BA_REL_ "GenSigTimeoutTime" BU_SG_REL_ L_EVNT SG_ 34 L_ATCU_FrDrModDis 1500;
BA_REL_ "GenSigTimeoutTime" BU_SG_REL_ L_HKBD SG_ 34 L_ATCU_FrDrModDis 1500;
BA_ "Version" SG_ 34 L_ATCU_FrDrModDis "24.05.08";
BA_ "Description" SG_ 34 L_ATCU_FrPassModDis "ATCU_FrontPassengerModeDisplay";
BA_ "GenSigSendType" SG_ 34 L_ATCU_FrPassModDis 4;
BA_ "UserSigValidity" SG_ 34 L_ATCU_FrPassModDis 7;
BA_REL_ "GenSigTimeoutTime" BU_SG_REL_ L_EVNT SG_ 34 L_ATCU_FrPassModDis 1500;
BA_REL_ "GenSigTimeoutTime" BU_SG_REL_ L_HKBD SG_ 34 L_ATCU_FrPassModDis 1500;
BA_ "Version" SG_ 34 L_ATCU_FrPassModDis "24.05.08";
BA_ "Description" SG_ 34 L_ATCU_FrDrBlwDis "This signal indicates step of Front Blower graphic.

This signal occurs when Front Blower siwtch(button) is selected either manually or automatically.";
BA_ "GenSigSendType" SG_ 34 L_ATCU_FrDrBlwDis 4;
BA_ "UserSigValidity" SG_ 34 L_ATCU_FrDrBlwDis 7;
BA_REL_ "GenSigTimeoutTime" BU_SG_REL_ L_HKBD SG_ 34 L_ATCU_FrDrBlwDis 1500;
BA_ "Version" SG_ 34 L_ATCU_FrDrBlwDis "23.08.13";
BA_ "GenSigSendType" SG_ 34 L_ATCU_FrPassBlwDis 4;
BA_ "UserSigValidity" SG_ 34 L_ATCU_FrPassBlwDis 7;
BA_REL_ "GenSigTimeoutTime" BU_SG_REL_ L_HKBD SG_ 34 L_ATCU_FrPassBlwDis 1500;
BA_ "Version" SG_ 34 L_ATCU_FrPassBlwDis "23.08.13";
BA_ "GenSigSendType" SG_ 34 L_ATCU_DrAutoDis 4;
BA_ "UserSigValidity" SG_ 34 L_ATCU_DrAutoDis 7;
BA_REL_ "GenSigTimeoutTime" BU_SG_REL_ L_HKBD SG_ 34 L_ATCU_DrAutoDis 1500;
BA_ "Version" SG_ 34 L_ATCU_DrAutoDis "23.08.13";
BA_ "GenSigSendType" SG_ 34 L_ATCU_PassAutoDis 4;
BA_ "UserSigValidity" SG_ 34 L_ATCU_PassAutoDis 7;
BA_REL_ "GenSigTimeoutTime" BU_SG_REL_ L_HKBD SG_ 34 L_ATCU_PassAutoDis 1500;
BA_ "Version" SG_ 34 L_ATCU_PassAutoDis "23.08.13";
BA_ "GenSigSendType" SG_ 34 L_ATCU_DrMultiAutoBlwDis 4;
BA_ "UserSigValidity" SG_ 34 L_ATCU_DrMultiAutoBlwDis 7;
BA_REL_ "GenSigTimeoutTime" BU_SG_REL_ L_HKBD SG_ 34 L_ATCU_DrMultiAutoBlwDis 1500;
BA_ "Version" SG_ 34 L_ATCU_DrMultiAutoBlwDis "23.08.13";
BA_ "GenSigSendType" SG_ 34 L_ATCU_PassMultiAutoBlwDis 4;
BA_ "UserSigValidity" SG_ 34 L_ATCU_PassMultiAutoBlwDis 7;
BA_REL_ "GenSigTimeoutTime" BU_SG_REL_ L_HKBD SG_ 34 L_ATCU_PassMultiAutoBlwDis 1500;
BA_ "Version" SG_ 34 L_ATCU_PassMultiAutoBlwDis "23.08.13";
BA_ "GenSigSendType" SG_ 34 L_ATCU_AcDis 4;
BA_ "UserSigValidity" SG_ 34 L_ATCU_AcDis 7;
BA_REL_ "GenSigTimeoutTime" BU_SG_REL_ L_HKBD SG_ 34 L_ATCU_AcDis 1500;
BA_ "Version" SG_ 34 L_ATCU_AcDis "23.08.13";
BA_ "GenSigSendType" SG_ 34 L_ATCU_IntakeDis 4;
BA_ "UserSigValidity" SG_ 34 L_ATCU_IntakeDis 7;
BA_REL_ "GenSigTimeoutTime" BU_SG_REL_ L_HKBD SG_ 34 L_ATCU_IntakeDis 1500;
BA_ "Version" SG_ 34 L_ATCU_IntakeDis "23.11.06";
BA_ "GenSigSendType" SG_ 34 L_ATCU_SyncDis 4;
BA_ "UserSigValidity" SG_ 34 L_ATCU_SyncDis 7;
BA_REL_ "GenSigTimeoutTime" BU_SG_REL_ L_HKBD SG_ 34 L_ATCU_SyncDis 1500;
BA_ "Version" SG_ 34 L_ATCU_SyncDis "23.08.13";
BA_ "GenSigSendType" SG_ 34 L_ATCU_FrDefDis 4;
BA_ "UserSigValidity" SG_ 34 L_ATCU_FrDefDis 7;
BA_REL_ "GenSigTimeoutTime" BU_SG_REL_ L_HKBD SG_ 34 L_ATCU_FrDefDis 1500;
BA_ "Version" SG_ 34 L_ATCU_FrDefDis "23.08.13";
BA_ "Description" SG_ 34 L_ATCU_PassTempCDis "This signal indicates Outside Temperature (¢µ)

(Use for display only)";
BA_ "GenSigSendType" SG_ 34 L_ATCU_PassTempCDis 4;
BA_ "UserSigValidity" SG_ 34 L_ATCU_PassTempCDis 7;
BA_REL_ "GenSigTimeoutTime" BU_SG_REL_ L_HKBD SG_ 34 L_ATCU_PassTempCDis 1500;
BA_ "Version" SG_ 34 L_ATCU_PassTempCDis "23.08.13";
BA_ "GenMsgSendType" BO_ 35 0;
BA_ "GenSigSendType" SG_ 35 L_ATCU_DrOnlyDis 4;
BA_ "UserSigValidity" SG_ 35 L_ATCU_DrOnlyDis 7;
BA_REL_ "GenSigTimeoutTime" BU_SG_REL_ L_HKBD SG_ 35 L_ATCU_DrOnlyDis 1500;
BA_ "Version" SG_ 35 L_ATCU_DrOnlyDis "23.08.13";
BA_ "GenSigSendType" SG_ 35 L_ATCU_SmrtVntDis 4;
BA_ "UserSigValidity" SG_ 35 L_ATCU_SmrtVntDis 7;
BA_REL_ "GenSigTimeoutTime" BU_SG_REL_ L_HKBD SG_ 35 L_ATCU_SmrtVntDis 1500;
BA_ "Version" SG_ 35 L_ATCU_SmrtVntDis "23.08.13";
BA_ "GenSigSendType" SG_ 35 L_ATCU_FrWndShldHtInd 4;
BA_ "UserSigValidity" SG_ 35 L_ATCU_FrWndShldHtInd 7;
BA_REL_ "GenSigTimeoutTime" BU_SG_REL_ L_HKBD SG_ 35 L_ATCU_FrWndShldHtInd 1500;
BA_ "Version" SG_ 35 L_ATCU_FrWndShldHtInd "23.08.13";
BA_ "GenSigSendType" SG_ 35 L_ATCU_IncarMtrOnReq 4;
BA_ "UserSigValidity" SG_ 35 L_ATCU_IncarMtrOnReq 7;
BA_REL_ "GenSigTimeoutTime" BU_SG_REL_ L_HKBD SG_ 35 L_ATCU_IncarMtrOnReq 1500;
BA_ "Version" SG_ 35 L_ATCU_IncarMtrOnReq "23.11.06";
BA_ "Description" SG_ 35 L_ATCU_LanguageInfo "This signal indicates System Language information for Font display";
BA_ "GenSigSendType" SG_ 35 L_ATCU_LanguageInfo 4;
BA_ "GenSigStartValue" SG_ 35 L_ATCU_LanguageInfo 255;
BA_ "UserSigValidity" SG_ 35 L_ATCU_LanguageInfo 7;
BA_REL_ "GenSigTimeoutTime" BU_SG_REL_ L_HKBD SG_ 35 L_ATCU_LanguageInfo 1500;
BA_ "Version" SG_ 35 L_ATCU_LanguageInfo "24.01.00";
BA_ "GenSigSendType" SG_ 35 L_ATCU_RrDefInd 4;
BA_ "UserSigValidity" SG_ 35 L_ATCU_RrDefInd 7;
BA_REL_ "GenSigTimeoutTime" BU_SG_REL_ L_HKBD SG_ 35 L_ATCU_RrDefInd 1500;
BA_ "Version" SG_ 35 L_ATCU_RrDefInd "23.08.13";
BA_ "GenSigSendType" SG_ 35 L_ATCU_AfterBlowDisplay 4;
BA_ "UserSigValidity" SG_ 35 L_ATCU_AfterBlowDisplay 7;
BA_REL_ "GenSigTimeoutTime" BU_SG_REL_ L_HKBD SG_ 35 L_ATCU_AfterBlowDisplay 1500;
BA_ "Version" SG_ 35 L_ATCU_AfterBlowDisplay "23.11.09";
BA_ "Description" SG_ 35 L_ATCU_SchdldVentDisplay "Operate Blower based on set time and date by user for better cabin room ventilation.";
BA_ "GenSigSendType" SG_ 35 L_ATCU_SchdldVentDisplay 4;
BA_ "UserSigValidity" SG_ 35 L_ATCU_SchdldVentDisplay 7;
BA_REL_ "GenSigTimeoutTime" BU_SG_REL_ L_HKBD SG_ 35 L_ATCU_SchdldVentDisplay 1500;
BA_ "Version" SG_ 35 L_ATCU_SchdldVentDisplay "24.01.00";
BA_ "GenSigSendType" SG_ 35 L_ATCU_FLStHeatSwHInd 4;
BA_ "UserSigValidity" SG_ 35 L_ATCU_FLStHeatSwHInd 7;
BA_REL_ "GenSigTimeoutTime" BU_SG_REL_ L_HKBD SG_ 35 L_ATCU_FLStHeatSwHInd 1500;
BA_ "Version" SG_ 35 L_ATCU_FLStHeatSwHInd "23.08.13";
BA_ "GenSigSendType" SG_ 35 L_ATCU_FLStHeatSwMInd 4;
BA_ "UserSigValidity" SG_ 35 L_ATCU_FLStHeatSwMInd 7;
BA_REL_ "GenSigTimeoutTime" BU_SG_REL_ L_HKBD SG_ 35 L_ATCU_FLStHeatSwMInd 1500;
BA_ "Version" SG_ 35 L_ATCU_FLStHeatSwMInd "23.08.13";
BA_ "GenSigSendType" SG_ 35 L_ATCU_ADSBlinkDis 4;
BA_ "UserSigValidity" SG_ 35 L_ATCU_ADSBlinkDis 7;
BA_REL_ "GenSigTimeoutTime" BU_SG_REL_ L_HKBD SG_ 35 L_ATCU_ADSBlinkDis 1500;
BA_ "Version" SG_ 35 L_ATCU_ADSBlinkDis "23.08.13";
BA_ "GenSigSendType" SG_ 35 L_ATCU_FLStHeatSwLInd 4;
BA_ "UserSigValidity" SG_ 35 L_ATCU_FLStHeatSwLInd 7;
BA_REL_ "GenSigTimeoutTime" BU_SG_REL_ L_HKBD SG_ 35 L_ATCU_FLStHeatSwLInd 1500;
BA_ "Version" SG_ 35 L_ATCU_FLStHeatSwLInd "23.08.13";
BA_ "GenSigSendType" SG_ 35 L_ATCU_FLStVntSwHInd 4;
BA_ "UserSigValidity" SG_ 35 L_ATCU_FLStVntSwHInd 7;
BA_REL_ "GenSigTimeoutTime" BU_SG_REL_ L_HKBD SG_ 35 L_ATCU_FLStVntSwHInd 1500;
BA_ "Version" SG_ 35 L_ATCU_FLStVntSwHInd "23.08.13";
BA_ "GenSigSendType" SG_ 35 L_ATCU_FLStVntSwMInd 4;
BA_ "UserSigValidity" SG_ 35 L_ATCU_FLStVntSwMInd 7;
BA_REL_ "GenSigTimeoutTime" BU_SG_REL_ L_HKBD SG_ 35 L_ATCU_FLStVntSwMInd 1500;
BA_ "Version" SG_ 35 L_ATCU_FLStVntSwMInd "23.08.13";
BA_ "GenSigSendType" SG_ 35 L_ATCU_FLStVntSwLInd 4;
BA_ "UserSigValidity" SG_ 35 L_ATCU_FLStVntSwLInd 7;
BA_REL_ "GenSigTimeoutTime" BU_SG_REL_ L_HKBD SG_ 35 L_ATCU_FLStVntSwLInd 1500;
BA_ "Version" SG_ 35 L_ATCU_FLStVntSwLInd "23.08.13";
BA_ "GenSigSendType" SG_ 35 L_ATCU_FRStHeatSwHInd 4;
BA_ "UserSigValidity" SG_ 35 L_ATCU_FRStHeatSwHInd 7;
BA_REL_ "GenSigTimeoutTime" BU_SG_REL_ L_HKBD SG_ 35 L_ATCU_FRStHeatSwHInd 1500;
BA_ "Version" SG_ 35 L_ATCU_FRStHeatSwHInd "23.08.13";
BA_ "GenSigSendType" SG_ 35 L_ATCU_FRStHeatSwMInd 4;
BA_ "UserSigValidity" SG_ 35 L_ATCU_FRStHeatSwMInd 7;
BA_REL_ "GenSigTimeoutTime" BU_SG_REL_ L_HKBD SG_ 35 L_ATCU_FRStHeatSwMInd 1500;
BA_ "Version" SG_ 35 L_ATCU_FRStHeatSwMInd "23.08.13";
BA_ "GenSigSendType" SG_ 35 L_ATCU_FRStHeatSwLInd 4;
BA_ "UserSigValidity" SG_ 35 L_ATCU_FRStHeatSwLInd 7;
BA_REL_ "GenSigTimeoutTime" BU_SG_REL_ L_HKBD SG_ 35 L_ATCU_FRStHeatSwLInd 1500;
BA_ "Version" SG_ 35 L_ATCU_FRStHeatSwLInd "23.08.13";
BA_ "GenSigSendType" SG_ 35 L_ATCU_FRStVntSwHInd 4;
BA_ "UserSigValidity" SG_ 35 L_ATCU_FRStVntSwHInd 7;
BA_REL_ "GenSigTimeoutTime" BU_SG_REL_ L_HKBD SG_ 35 L_ATCU_FRStVntSwHInd 1500;
BA_ "Version" SG_ 35 L_ATCU_FRStVntSwHInd "23.08.13";
BA_ "GenSigSendType" SG_ 35 L_ATCU_FRStVntSwMInd 4;
BA_ "UserSigValidity" SG_ 35 L_ATCU_FRStVntSwMInd 7;
BA_REL_ "GenSigTimeoutTime" BU_SG_REL_ L_HKBD SG_ 35 L_ATCU_FRStVntSwMInd 1500;
BA_ "Version" SG_ 35 L_ATCU_FRStVntSwMInd "23.08.13";
BA_ "GenSigSendType" SG_ 35 L_ATCU_FRStVntSwLInd 4;
BA_ "UserSigValidity" SG_ 35 L_ATCU_FRStVntSwLInd 7;
BA_REL_ "GenSigTimeoutTime" BU_SG_REL_ L_HKBD SG_ 35 L_ATCU_FRStVntSwLInd 1500;
BA_ "Version" SG_ 35 L_ATCU_FRStVntSwLInd "23.08.13";
BA_ "Description" SG_ 35 L_ATCU_StrWhlHeatInd "This signal indicates the status of Steering Wheel Heater";
BA_ "GenSigSendType" SG_ 35 L_ATCU_StrWhlHeatInd 4;
BA_ "UserSigValidity" SG_ 35 L_ATCU_StrWhlHeatInd 7;
BA_REL_ "GenSigTimeoutTime" BU_SG_REL_ L_HKBD SG_ 35 L_ATCU_StrWhlHeatInd 1500;
BA_ "Version" SG_ 35 L_ATCU_StrWhlHeatInd "23.08.13";
BA_ "NmNode" BU_ L_2HKBD 0;
BA_ "Description" SG_ 35 L_ATCU_RhstaLvlSta "This signal is used for a rheostat level of CLUSTER from 1 to 21 level (21 level:Detent) for a Unified Illumination System



¡Ø Start Value:Current Value";
BA_ "GenSigSendType" SG_ 35 L_ATCU_RhstaLvlSta 4;
BA_ "UserSigValidity" SG_ 35 L_ATCU_RhstaLvlSta 7;
BA_REL_ "GenSigTimeoutTime" BU_SG_REL_ L_2HKBD SG_ 35 L_ATCU_RhstaLvlSta 1500;
BA_REL_ "GenSigTimeoutTime" BU_SG_REL_ L_EVNT SG_ 35 L_ATCU_RhstaLvlSta 1500;
BA_REL_ "GenSigTimeoutTime" BU_SG_REL_ L_HKBD SG_ 35 L_ATCU_RhstaLvlSta 1500;
BA_ "Version" SG_ 35 L_ATCU_RhstaLvlSta "24.08.00";
BA_ "GenSigSendType" SG_ 35 L_ATCU_IntTailOnOff 4;
BA_ "UserSigValidity" SG_ 35 L_ATCU_IntTailOnOff 7;
BA_REL_ "GenSigTimeoutTime" BU_SG_REL_ L_2HKBD SG_ 35 L_ATCU_IntTailOnOff 1500;
BA_REL_ "GenSigTimeoutTime" BU_SG_REL_ L_HKBD SG_ 35 L_ATCU_IntTailOnOff 1500;
BA_ "Version" SG_ 35 L_ATCU_IntTailOnOff "23.08.13";
BA_ "Description" SG_ 35 L_ATCU_AutoLightSta "This signal indicates autolight sensor output";
BA_ "GenSigSendType" SG_ 35 L_ATCU_AutoLightSta 4;
BA_ "UserSigValidity" SG_ 35 L_ATCU_AutoLightSta 7;
BA_REL_ "GenSigTimeoutTime" BU_SG_REL_ L_HKBD SG_ 35 L_ATCU_AutoLightSta 1500;
BA_ "Version" SG_ 35 L_ATCU_AutoLightSta "23.08.13";
BA_ "GenSigSendType" SG_ 35 L_ATCU_FrBckLightSta 4;
BA_ "UserSigValidity" SG_ 35 L_ATCU_FrBckLightSta 7;
BA_REL_ "GenSigTimeoutTime" BU_SG_REL_ L_HKBD SG_ 35 L_ATCU_FrBckLightSta 1500;
BA_ "Version" SG_ 35 L_ATCU_FrBckLightSta "23.08.13";
BA_ "GenSigSendType" SG_ 35 L_ATCU_DisplayTheme 4;
BA_ "UserSigValidity" SG_ 35 L_ATCU_DisplayTheme 7;
BA_REL_ "GenSigTimeoutTime" BU_SG_REL_ L_HKBD SG_ 35 L_ATCU_DisplayTheme 1500;
BA_ "Version" SG_ 35 L_ATCU_DisplayTheme "23.08.13";
BA_ "GenSigSendType" SG_ 35 L_ATCU_GUIBlankDis 4;
BA_ "UserSigValidity" SG_ 35 L_ATCU_GUIBlankDis 7;
BA_REL_ "GenSigTimeoutTime" BU_SG_REL_ L_HKBD SG_ 35 L_ATCU_GUIBlankDis 1500;
BA_ "Version" SG_ 35 L_ATCU_GUIBlankDis "23.08.13";
BA_ "GenSigSendType" SG_ 35 L_ATCU_HptIntnstySet 4;
BA_ "UserSigValidity" SG_ 35 L_ATCU_HptIntnstySet 7;
BA_REL_ "GenSigTimeoutTime" BU_SG_REL_ L_HKBD SG_ 35 L_ATCU_HptIntnstySet 1500;
BA_ "Version" SG_ 35 L_ATCU_HptIntnstySet "23.11.06";
BA_ "Description" SG_ 35 L_ATCU_TlltLmpDis "This signal means information regarding Occupant status.

0) 00Xb:X position means PAB OFF Lamp indication. When this bit set as 1 PAB OFF lamp turns ON. 

    0Y0b:Y position means PAB ON Lamp indication. When this bit set as 1 PAB ON lamp turns ON.



1) Default value:0x2 (PAB ON Lamp on, PAB OFF Lamp off,)

2) Default value Transmit condition

    - When the input condition is not determined.

    - When the input condition is not supported.";
BA_ "GenSigSendType" SG_ 35 L_ATCU_TlltLmpDis 4;
BA_ "UserSigValidity" SG_ 35 L_ATCU_TlltLmpDis 7;
BA_REL_ "GenSigTimeoutTime" BU_SG_REL_ L_HKBD SG_ 35 L_ATCU_TlltLmpDis 1500;
BA_ "Version" SG_ 35 L_ATCU_TlltLmpDis "23.08.13";
BA_ "GenSigSendType" SG_ 35 L_ATCU_AvTailOnOff 4;
BA_ "UserSigValidity" SG_ 35 L_ATCU_AvTailOnOff 7;
BA_REL_ "GenSigTimeoutTime" BU_SG_REL_ L_HKBD SG_ 35 L_ATCU_AvTailOnOff 1500;
BA_ "Version" SG_ 35 L_ATCU_AvTailOnOff "23.08.13";
BA_ "Description" SG_ 35 L_ATCU_SchdldClimateDisplay "Operate Climate system based on set time and date by user in EV vehicle.";
BA_ "GenSigSendType" SG_ 35 L_ATCU_SchdldClimateDisplay 4;
BA_ "UserSigValidity" SG_ 35 L_ATCU_SchdldClimateDisplay 7;
BA_REL_ "GenSigTimeoutTime" BU_SG_REL_ L_HKBD SG_ 35 L_ATCU_SchdldClimateDisplay 1500;
BA_ "Version" SG_ 35 L_ATCU_SchdldClimateDisplay "24.01.00";
BA_ "GenSigSendType" SG_ 35 L_ATCU_AirClnDis 4;
BA_ "UserSigValidity" SG_ 35 L_ATCU_AirClnDis 7;
BA_REL_ "GenSigTimeoutTime" BU_SG_REL_ L_HKBD SG_ 35 L_ATCU_AirClnDis 1500;
BA_ "Version" SG_ 35 L_ATCU_AirClnDis "23.08.13";
BA_ "GenSigSendType" SG_ 35 L_ATCU_CO2WrngDis 4;
BA_ "UserSigValidity" SG_ 35 L_ATCU_CO2WrngDis 7;
BA_REL_ "GenSigTimeoutTime" BU_SG_REL_ L_HKBD SG_ 35 L_ATCU_CO2WrngDis 1500;
BA_ "Version" SG_ 35 L_ATCU_CO2WrngDis "23.08.13";
BA_ "NmNode" BU_ L_PCM 0;
BA_ "NmNode" BU_ L_3HKBD 0;
BA_ "NmNode" BU_ L_FHPTC 0;
BA_ "NmNode" BU_ L_RHPTC 0;
BA_ "GenMsgSendType" BO_ 273 0;
BA_ "GenMsgCycleTime" BO_ 273 20;
BA_ "GenMsgCycleTimeFast" BO_ 273 0;
BA_ "GenMsgNrOfRepetition" BO_ 273 0;
BA_ "GenMsgDelayTime" BO_ 273 0;
BA_ "UserSigValidity" SG_ 273 L_ATCU_FHPTCOpPrmssnSta 7;
BA_ "Version" SG_ 273 L_ATCU_FHPTCOpPrmssnSta "23.08.13";
BA_ "UserSigValidity" SG_ 273 L_ATCU_FHPTCPassTrgtDty 7;
BA_ "Version" SG_ 273 L_ATCU_FHPTCPassTrgtDty "23.08.13";
BA_ "UserSigValidity" SG_ 273 L_ATCU_FHPTCDischrgReq 7;
BA_ "Version" SG_ 273 L_ATCU_FHPTCDischrgReq "23.08.13";
BA_ "Description" SG_ 273 L_ATCU_FltMsgTmOutFHPTC1 "Message Timeout of FHPTC_01";
BA_ "UserSigValidity" SG_ 273 L_ATCU_FltMsgTmOutFHPTC1 7;
BA_ "Version" SG_ 273 L_ATCU_FltMsgTmOutFHPTC1 "23.08.13";
BA_ "Description" SG_ 273 L_ATCU_FltMsgTmOutFHPTC2 "Message Timeout of FHPTC_02";
BA_ "UserSigValidity" SG_ 273 L_ATCU_FltMsgTmOutFHPTC2 7;
BA_ "Version" SG_ 273 L_ATCU_FltMsgTmOutFHPTC2 "23.08.13";
BA_ "Description" SG_ 273 L_ATCU_FltMsgTmOutFHPTC3 "Message Timeout of FHPTC_03";
BA_ "UserSigValidity" SG_ 273 L_ATCU_FltMsgTmOutFHPTC3 7;
BA_ "Version" SG_ 273 L_ATCU_FltMsgTmOutFHPTC3 "23.08.13";
BA_ "Description" SG_ 273 L_ATCU_FltMsgTmOutFHPTC4 "Message Timeout of FHPTC_04";
BA_ "UserSigValidity" SG_ 273 L_ATCU_FltMsgTmOutFHPTC4 7;
BA_ "Version" SG_ 273 L_ATCU_FltMsgTmOutFHPTC4 "23.08.13";
BA_ "Description" SG_ 273 L_ATCU_FrBlwLvl "This signal indicates step of Front blower operation";
BA_ "UserSigValidity" SG_ 273 L_ATCU_FrBlwLvl 7;
BA_ "Version" SG_ 273 L_ATCU_FrBlwLvl "23.08.13";
BA_ "Description" SG_ 273 L_ATCU_FrBlwLvlSigVaildSta "This signal sindicates the validation of 'blower level signal'

Initial value is 0x0(Invalid, do not send information of blower level)";
BA_ "UserSigValidity" SG_ 273 L_ATCU_FrBlwLvlSigVaildSta 7;
BA_ "Version" SG_ 273 L_ATCU_FrBlwLvlSigVaildSta "23.08.13";
BA_ "Description" SG_ 273 L_ATCU_DrvrSdTyp "This signal indicates information of driver type (LHD/RHD)";
BA_ "UserSigValidity" SG_ 273 L_ATCU_DrvrSdTyp 7;
BA_ "Version" SG_ 273 L_ATCU_DrvrSdTyp "23.08.13";
BA_ "UserSigValidity" SG_ 273 L_ATCU_FrBlwFltSta 7;
BA_ "Version" SG_ 273 L_ATCU_FrBlwFltSta "23.08.13";
BA_ "UserSigValidity" SG_ 273 L_ATCU_PassBlwLvl 7;
BA_ "Version" SG_ 273 L_ATCU_PassBlwLvl "23.08.13";
BA_ "UserSigValidity" SG_ 273 L_ATCU_FHPTCDrTrgtDty 7;
BA_ "Version" SG_ 273 L_ATCU_FHPTCDrTrgtDty "23.08.13";
BA_ "GenMsgSendType" BO_ 274 0;
BA_ "GenMsgCycleTime" BO_ 274 20;
BA_ "GenMsgCycleTimeFast" BO_ 274 0;
BA_ "GenMsgNrOfRepetition" BO_ 274 0;
BA_ "GenMsgDelayTime" BO_ 274 0;
BA_ "UserSigValidity" SG_ 274 L_ATCU_RHPTCOpPrmssnSta 7;
BA_ "Version" SG_ 274 L_ATCU_RHPTCOpPrmssnSta "23.08.13";
BA_ "Description" SG_ 274 L_ATCU_RHPTCZone2TrgtDty "Zone2 : Ps or Floor";
BA_ "UserSigValidity" SG_ 274 L_ATCU_RHPTCZone2TrgtDty 7;
BA_ "Version" SG_ 274 L_ATCU_RHPTCZone2TrgtDty "24.02.01";
BA_ "UserSigValidity" SG_ 274 L_ATCU_RHPTCDischrgReq 7;
BA_ "Version" SG_ 274 L_ATCU_RHPTCDischrgReq "23.08.13";
BA_ "Description" SG_ 274 L_ATCU_FltMsgTmOutRHPTC1 "Message Timeout of RHPTC_01";
BA_ "UserSigValidity" SG_ 274 L_ATCU_FltMsgTmOutRHPTC1 7;
BA_ "Version" SG_ 274 L_ATCU_FltMsgTmOutRHPTC1 "23.08.13";
BA_ "Description" SG_ 274 L_ATCU_FltMsgTmOutRHPTC2 "Message Timeout of RHPTC_02";
BA_ "UserSigValidity" SG_ 274 L_ATCU_FltMsgTmOutRHPTC2 7;
BA_ "Version" SG_ 274 L_ATCU_FltMsgTmOutRHPTC2 "23.08.13";
BA_ "Description" SG_ 274 L_ATCU_FltMsgTmOutRHPTC3 "Message Timeout of RHPTC_03";
BA_ "UserSigValidity" SG_ 274 L_ATCU_FltMsgTmOutRHPTC3 7;
BA_ "Version" SG_ 274 L_ATCU_FltMsgTmOutRHPTC3 "23.08.13";
BA_ "Description" SG_ 274 L_ATCU_FltMsgTmOutRHPTC4 "Message Timeout of RHPTC_04";
BA_ "UserSigValidity" SG_ 274 L_ATCU_FltMsgTmOutRHPTC4 7;
BA_ "Version" SG_ 274 L_ATCU_FltMsgTmOutRHPTC4 "23.08.13";
BA_ "Description" SG_ 274 L_ATCU_RrBlwLvl "This signal indicates step of Rear blower operation";
BA_ "UserSigValidity" SG_ 274 L_ATCU_RrBlwLvl 7;
BA_ "Version" SG_ 274 L_ATCU_RrBlwLvl "23.08.13";
BA_ "Description" SG_ 274 L_ATCU_RrBlwLvlSigVaildSta "This signal sindicates the validation of 'blower level signal'

Initial value is 0x0(Invalid, do not send information of blower level)";
BA_ "UserSigValidity" SG_ 274 L_ATCU_RrBlwLvlSigVaildSta 7;
BA_ "Version" SG_ 274 L_ATCU_RrBlwLvlSigVaildSta "23.08.13";
BA_ "Description" SG_ 274 L_ATCU_RHPTCZone1TrgtDty "Zone1 : Dr or Roof";
BA_ "UserSigValidity" SG_ 274 L_ATCU_RHPTCZone1TrgtDty 7;
BA_ "Version" SG_ 274 L_ATCU_RHPTCZone1TrgtDty "24.02.01";
BA_ "UserSigValidity" SG_ 274 L_ATCU_RrBlwFltSta 7;
BA_ "Version" SG_ 274 L_ATCU_RrBlwFltSta "23.08.13";
BA_ "GenMsgSendType" BO_ 277 0;
BA_ "GenMsgCycleTime" BO_ 277 20;
BA_ "GenMsgCycleTimeFast" BO_ 277 0;
BA_ "GenMsgNrOfRepetition" BO_ 277 0;
BA_ "GenMsgDelayTime" BO_ 277 0;
BA_ "UserSigValidity" SG_ 277 L_ATCU_FHPTC2ndDrTrgtDty 7;
BA_ "Version" SG_ 277 L_ATCU_FHPTC2ndDrTrgtDty "24.02.06";
BA_ "Description" SG_ 277 L_ATCU_FltMsgTmOutFHPTC5 "Message Timeout of FHPTC_05";
BA_ "UserSigValidity" SG_ 277 L_ATCU_FltMsgTmOutFHPTC5 7;
BA_ "Version" SG_ 277 L_ATCU_FltMsgTmOutFHPTC5 "24.02.06";
BA_ "Description" SG_ 277 L_ATCU_FltMsgTmOutFHPTC6 "Message Timeout of FHPTC_06";
BA_ "UserSigValidity" SG_ 277 L_ATCU_FltMsgTmOutFHPTC6 7;
BA_ "Version" SG_ 277 L_ATCU_FltMsgTmOutFHPTC6 "24.02.06";
BA_ "Description" SG_ 277 L_ATCU_FltMsgTmOutFHPTC7 "Message Timeout of FHPTC_07";
BA_ "UserSigValidity" SG_ 277 L_ATCU_FltMsgTmOutFHPTC7 7;
BA_ "Version" SG_ 277 L_ATCU_FltMsgTmOutFHPTC7 "24.02.06";
BA_ "Description" SG_ 277 L_ATCU_FltMsgTmOutFHPTC8 "Message Timeout of FHPTC_08";
BA_ "UserSigValidity" SG_ 277 L_ATCU_FltMsgTmOutFHPTC8 7;
BA_ "Version" SG_ 277 L_ATCU_FltMsgTmOutFHPTC8 "24.02.06";
BA_ "Description" SG_ 277 L_ATCU_2ndDrBlwLvl "This signal indicates step of driver side Console blower operation";
BA_ "UserSigValidity" SG_ 277 L_ATCU_2ndDrBlwLvl 7;
BA_ "Version" SG_ 277 L_ATCU_2ndDrBlwLvl "24.05.08";
BA_ "Description" SG_ 277 L_ATCU_2ndPsBlwLvl "This signal indicates step of passenger side Console blower operation";
BA_ "UserSigValidity" SG_ 277 L_ATCU_2ndPsBlwLvl 7;
BA_ "Version" SG_ 277 L_ATCU_2ndPsBlwLvl "24.05.08";
BA_ "Description" SG_ 277 L_ATCU_2ndBlwLvlSigVaildSta "This signal sindicates the validation of 'blower level signal'

Initial value is 0x0(Invalid, do not send information of blower level)";
BA_ "UserSigValidity" SG_ 277 L_ATCU_2ndBlwLvlSigVaildSta 7;
BA_ "Version" SG_ 277 L_ATCU_2ndBlwLvlSigVaildSta "24.02.06";
BA_ "UserSigValidity" SG_ 277 L_ATCU_2ndBlwFltSta 7;
BA_ "Version" SG_ 277 L_ATCU_2ndBlwFltSta "24.02.06";
BA_ "UserSigValidity" SG_ 277 L_ATCU_FHPTC2ndPsTrgtDty 7;
BA_ "Version" SG_ 277 L_ATCU_FHPTC2ndPsTrgtDty "24.02.06";
BA_ "GenMsgCycleTime" BO_ 281 0;
BA_ "Description" SG_ 281 L_ATCU_HU_FrDrEVntSidePt_X "Electric Vent Frt Driver Side Electric Vent Touch Range X Coordinate";
BA_ "GenSigSendType" SG_ 281 L_ATCU_HU_FrDrEVntSidePt_X 4;
BA_ "UserSigValidity" SG_ 281 L_ATCU_HU_FrDrEVntSidePt_X 7;
BA_REL_ "GenSigTimeoutTime" BU_SG_REL_ L_EVNT SG_ 281 L_ATCU_HU_FrDrEVntSidePt_X 0;
BA_ "Version" SG_ 281 L_ATCU_HU_FrDrEVntSidePt_X "24.05.11";
BA_ "Description" SG_ 281 L_ATCU_HU_FrDrEVntSidePt_Y "Electric Vent Frt Driver Side Electric Vent Touch Range Y Coordinate";
BA_ "GenSigSendType" SG_ 281 L_ATCU_HU_FrDrEVntSidePt_Y 4;
BA_ "UserSigValidity" SG_ 281 L_ATCU_HU_FrDrEVntSidePt_Y 7;
BA_REL_ "GenSigTimeoutTime" BU_SG_REL_ L_EVNT SG_ 281 L_ATCU_HU_FrDrEVntSidePt_Y 0;
BA_ "Version" SG_ 281 L_ATCU_HU_FrDrEVntSidePt_Y "24.05.11";
BA_ "Description" SG_ 281 L_ATCU_HU_FrDrEVntCtrPt_X "Electric Vent Frt Driver Center Electric Vent Touch Range X Coordinate";
BA_ "GenSigSendType" SG_ 281 L_ATCU_HU_FrDrEVntCtrPt_X 4;
BA_ "UserSigValidity" SG_ 281 L_ATCU_HU_FrDrEVntCtrPt_X 7;
BA_REL_ "GenSigTimeoutTime" BU_SG_REL_ L_EVNT SG_ 281 L_ATCU_HU_FrDrEVntCtrPt_X 0;
BA_ "Version" SG_ 281 L_ATCU_HU_FrDrEVntCtrPt_X "24.05.11";
BA_ "Description" SG_ 281 L_ATCU_HU_FrDrEVntCtrPt_Y "Electric Vent Frt Driver Center Electric Vent Touch Range Y Coordinate";
BA_ "GenSigSendType" SG_ 281 L_ATCU_HU_FrDrEVntCtrPt_Y 4;
BA_ "UserSigValidity" SG_ 281 L_ATCU_HU_FrDrEVntCtrPt_Y 7;
BA_REL_ "GenSigTimeoutTime" BU_SG_REL_ L_EVNT SG_ 281 L_ATCU_HU_FrDrEVntCtrPt_Y 0;
BA_ "Version" SG_ 281 L_ATCU_HU_FrDrEVntCtrPt_Y "24.05.11";
BA_ "GenMsgCycleTime" BO_ 305 0;
BA_ "Description" SG_ 305 L_ATCU_HU_FrPsEVntSidePt_X "Electric Vent Frt Passenger Side Electric Vent Touch Range X Coordinate";
BA_ "GenSigSendType" SG_ 305 L_ATCU_HU_FrPsEVntSidePt_X 4;
BA_ "UserSigValidity" SG_ 305 L_ATCU_HU_FrPsEVntSidePt_X 7;
BA_REL_ "GenSigTimeoutTime" BU_SG_REL_ L_EVNT SG_ 305 L_ATCU_HU_FrPsEVntSidePt_X 0;
BA_ "Version" SG_ 305 L_ATCU_HU_FrPsEVntSidePt_X "24.05.11";
BA_ "Description" SG_ 305 L_ATCU_HU_FrPsEVntSidePt_Y "Electric Vent Frt Passenger Side Electric Vent Touch Range Y Coordinate";
BA_ "GenSigSendType" SG_ 305 L_ATCU_HU_FrPsEVntSidePt_Y 4;
BA_ "UserSigValidity" SG_ 305 L_ATCU_HU_FrPsEVntSidePt_Y 7;
BA_REL_ "GenSigTimeoutTime" BU_SG_REL_ L_EVNT SG_ 305 L_ATCU_HU_FrPsEVntSidePt_Y 0;
BA_ "Version" SG_ 305 L_ATCU_HU_FrPsEVntSidePt_Y "24.05.11";
BA_ "Description" SG_ 305 L_ATCU_HU_FrPsEVntCtrPt_X "Electric Vent Frt Passenger Center Electric Vent Touch Range X Coordinate";
BA_ "GenSigSendType" SG_ 305 L_ATCU_HU_FrPsEVntCtrPt_X 4;
BA_ "UserSigValidity" SG_ 305 L_ATCU_HU_FrPsEVntCtrPt_X 7;
BA_REL_ "GenSigTimeoutTime" BU_SG_REL_ L_EVNT SG_ 305 L_ATCU_HU_FrPsEVntCtrPt_X 0;
BA_ "Version" SG_ 305 L_ATCU_HU_FrPsEVntCtrPt_X "24.05.11";
BA_ "Description" SG_ 305 L_ATCU_HU_FrPsEVntCtrPt_Y "Electric Vent Frt Passenger Center Electric Vent Touch Range Y Coordinate";
BA_ "GenSigSendType" SG_ 305 L_ATCU_HU_FrPsEVntCtrPt_Y 4;
BA_ "UserSigValidity" SG_ 305 L_ATCU_HU_FrPsEVntCtrPt_Y 7;
BA_REL_ "GenSigTimeoutTime" BU_SG_REL_ L_EVNT SG_ 305 L_ATCU_HU_FrPsEVntCtrPt_Y 0;
BA_ "Version" SG_ 305 L_ATCU_HU_FrPsEVntCtrPt_Y "24.05.11";
BA_ "GenMsgCycleTime" BO_ 306 0;
BA_ "Description" SG_ 306 L_ATCU_HU_RrDrEVntConsPt_X "Electric Vent Rear Driver Console Touch Range X Coordinate";
BA_ "GenSigSendType" SG_ 306 L_ATCU_HU_RrDrEVntConsPt_X 4;
BA_ "UserSigValidity" SG_ 306 L_ATCU_HU_RrDrEVntConsPt_X 7;
BA_REL_ "GenSigTimeoutTime" BU_SG_REL_ L_EVNT SG_ 306 L_ATCU_HU_RrDrEVntConsPt_X 0;
BA_ "Version" SG_ 306 L_ATCU_HU_RrDrEVntConsPt_X "24.05.11";
BA_ "Description" SG_ 306 L_ATCU_HU_RrDrEVntConsPt_Y "Electric Vent Rear Driver Console Touch Range Y Coordinate";
BA_ "GenSigSendType" SG_ 306 L_ATCU_HU_RrDrEVntConsPt_Y 4;
BA_ "UserSigValidity" SG_ 306 L_ATCU_HU_RrDrEVntConsPt_Y 7;
BA_REL_ "GenSigTimeoutTime" BU_SG_REL_ L_EVNT SG_ 306 L_ATCU_HU_RrDrEVntConsPt_Y 0;
BA_ "Version" SG_ 306 L_ATCU_HU_RrDrEVntConsPt_Y "24.05.11";
BA_ "Description" SG_ 306 L_ATCU_HU_RrPsEVntConsPt_X "Electric Vent Rear Passenger Console Touch Range X Coordinate";
BA_ "GenSigSendType" SG_ 306 L_ATCU_HU_RrPsEVntConsPt_X 4;
BA_ "UserSigValidity" SG_ 306 L_ATCU_HU_RrPsEVntConsPt_X 7;
BA_REL_ "GenSigTimeoutTime" BU_SG_REL_ L_EVNT SG_ 306 L_ATCU_HU_RrPsEVntConsPt_X 0;
BA_ "Version" SG_ 306 L_ATCU_HU_RrPsEVntConsPt_X "24.05.11";
BA_ "Description" SG_ 306 L_ATCU_HU_RrPsEVntConsPt_Y "Electric Vent Rear Passenger Console Touch Range Y Coordinate";
BA_ "GenSigSendType" SG_ 306 L_ATCU_HU_RrPsEVntConsPt_Y 4;
BA_ "UserSigValidity" SG_ 306 L_ATCU_HU_RrPsEVntConsPt_Y 7;
BA_REL_ "GenSigTimeoutTime" BU_SG_REL_ L_EVNT SG_ 306 L_ATCU_HU_RrPsEVntConsPt_Y 0;
BA_ "Version" SG_ 306 L_ATCU_HU_RrPsEVntConsPt_Y "24.05.11";
BA_ "Description" SG_ 306 L_ATCU_HU_RrDrEVntConsOpnCls "Electric Vent Rear Driver Console Vent Open/Close Signal";
BA_ "GenSigSendType" SG_ 306 L_ATCU_HU_RrDrEVntConsOpnCls 4;
BA_ "UserSigValidity" SG_ 306 L_ATCU_HU_RrDrEVntConsOpnCls 7;
BA_REL_ "GenSigTimeoutTime" BU_SG_REL_ L_EVNT SG_ 306 L_ATCU_HU_RrDrEVntConsOpnCls 0;
BA_ "Version" SG_ 306 L_ATCU_HU_RrDrEVntConsOpnCls "24.05.11";
BA_ "Description" SG_ 306 L_ATCU_HU_RrPsEVntConsOpnCls "Electric Vent Rear Passenger Console Vent Open/Close Signal";
BA_ "GenSigSendType" SG_ 306 L_ATCU_HU_RrPsEVntConsOpnCls 4;
BA_ "UserSigValidity" SG_ 306 L_ATCU_HU_RrPsEVntConsOpnCls 7;
BA_REL_ "GenSigTimeoutTime" BU_SG_REL_ L_EVNT SG_ 306 L_ATCU_HU_RrPsEVntConsOpnCls 0;
BA_ "Version" SG_ 306 L_ATCU_HU_RrPsEVntConsOpnCls "24.05.11";
BA_ "Description" SG_ 306 L_ATCU_HU_RrDrEVntModeSet "Electric Vent Rear Driver Console Vent Mode Signal";
BA_ "GenSigSendType" SG_ 306 L_ATCU_HU_RrDrEVntModeSet 4;
BA_ "UserSigValidity" SG_ 306 L_ATCU_HU_RrDrEVntModeSet 7;
BA_REL_ "GenSigTimeoutTime" BU_SG_REL_ L_EVNT SG_ 306 L_ATCU_HU_RrDrEVntModeSet 0;
BA_ "Version" SG_ 306 L_ATCU_HU_RrDrEVntModeSet "24.08.00";
BA_ "Description" SG_ 306 L_ATCU_HU_RrPsEVntModeSet "Electric Vent Rear Passenger Console Vent Mode Signal";
BA_ "GenSigSendType" SG_ 306 L_ATCU_HU_RrPsEVntModeSet 4;
BA_ "UserSigValidity" SG_ 306 L_ATCU_HU_RrPsEVntModeSet 7;
BA_REL_ "GenSigTimeoutTime" BU_SG_REL_ L_EVNT SG_ 306 L_ATCU_HU_RrPsEVntModeSet 0;
BA_ "Version" SG_ 306 L_ATCU_HU_RrPsEVntModeSet "24.08.00";
BA_ "GenMsgSendType" BO_ 304 0;
BA_ "GenMsgCycleTime" BO_ 304 1000;
BA_ "GenMsgCycleTimeFast" BO_ 304 0;
BA_ "GenMsgNrOfRepetition" BO_ 304 0;
BA_ "Description" SG_ 304 L_ATCU_CTS_RrDrEVntConsBdryUp_X "Electric Vent RR Dr Console Electric Vent Upper Range X Coordinate";
BA_ "UserSigValidity" SG_ 304 L_ATCU_CTS_RrDrEVntConsBdryUp_X 7;
BA_REL_ "GenSigTimeoutTime" BU_SG_REL_ L_EVNT SG_ 304 L_ATCU_CTS_RrDrEVntConsBdryUp_X 5000;
BA_ "Version" SG_ 304 L_ATCU_CTS_RrDrEVntConsBdryUp_X "24.05.11";
BA_ "Description" SG_ 304 L_ATCU_CTS_RrDrEVntConsBdryLo_X "Electric Vent RR Dr Console Electric Vent Lower Range X Coordinate";
BA_ "UserSigValidity" SG_ 304 L_ATCU_CTS_RrDrEVntConsBdryLo_X 7;
BA_REL_ "GenSigTimeoutTime" BU_SG_REL_ L_EVNT SG_ 304 L_ATCU_CTS_RrDrEVntConsBdryLo_X 5000;
BA_ "Version" SG_ 304 L_ATCU_CTS_RrDrEVntConsBdryLo_X "24.05.11";
BA_ "Description" SG_ 304 L_ATCU_CTS_RrDrEVntConsBdryLo_Y "Electric Vent RR Dr Console Electric Vent Lower Range Y Coordinate";
BA_ "UserSigValidity" SG_ 304 L_ATCU_CTS_RrDrEVntConsBdryLo_Y 7;
BA_REL_ "GenSigTimeoutTime" BU_SG_REL_ L_EVNT SG_ 304 L_ATCU_CTS_RrDrEVntConsBdryLo_Y 5000;
BA_ "Version" SG_ 304 L_ATCU_CTS_RrDrEVntConsBdryLo_Y "24.05.11";
BA_ "Description" SG_ 304 L_ATCU_CTS_RrPsEVntConsBdryUp_X "Electric Vent RR Ps Console Electric Vent Upper Range X Coordinate";
BA_ "UserSigValidity" SG_ 304 L_ATCU_CTS_RrPsEVntConsBdryUp_X 7;
BA_REL_ "GenSigTimeoutTime" BU_SG_REL_ L_EVNT SG_ 304 L_ATCU_CTS_RrPsEVntConsBdryUp_X 5000;
BA_ "Version" SG_ 304 L_ATCU_CTS_RrPsEVntConsBdryUp_X "24.05.11";
BA_ "Description" SG_ 304 L_ATCU_CTS_RrPsEVntConsBdryUp_Y "Electric Vent RR Ps Console Electric Vent Upper Range Y Coordinate";
BA_ "UserSigValidity" SG_ 304 L_ATCU_CTS_RrPsEVntConsBdryUp_Y 7;
BA_REL_ "GenSigTimeoutTime" BU_SG_REL_ L_EVNT SG_ 304 L_ATCU_CTS_RrPsEVntConsBdryUp_Y 5000;
BA_ "Version" SG_ 304 L_ATCU_CTS_RrPsEVntConsBdryUp_Y "24.05.11";
BA_ "Description" SG_ 304 L_ATCU_CTS_RrPsEVntConsBdryLo_X "Electric Vent RR Ps Console Electric Vent Lower Range X Coordinate";
BA_ "UserSigValidity" SG_ 304 L_ATCU_CTS_RrPsEVntConsBdryLo_X 7;
BA_REL_ "GenSigTimeoutTime" BU_SG_REL_ L_EVNT SG_ 304 L_ATCU_CTS_RrPsEVntConsBdryLo_X 5000;
BA_ "Version" SG_ 304 L_ATCU_CTS_RrPsEVntConsBdryLo_X "24.05.11";
BA_ "Description" SG_ 304 L_ATCU_CTS_RrPsEVntConsBdryLo_Y "Electric Vent RR Ps Console Electric Vent Lower Range Y Coordinate";
BA_ "UserSigValidity" SG_ 304 L_ATCU_CTS_RrPsEVntConsBdryLo_Y 7;
BA_REL_ "GenSigTimeoutTime" BU_SG_REL_ L_EVNT SG_ 304 L_ATCU_CTS_RrPsEVntConsBdryLo_Y 5000;
BA_ "Version" SG_ 304 L_ATCU_CTS_RrPsEVntConsBdryLo_Y "24.05.11";
BA_ "Description" SG_ 304 L_ATCU_CTS_RrDrEVntConsBdryUp_Y "Electric Vent RR Dr Console Electric Vent Upper Range Y Coordinate";
BA_ "UserSigValidity" SG_ 304 L_ATCU_CTS_RrDrEVntConsBdryUp_Y 7;
BA_REL_ "GenSigTimeoutTime" BU_SG_REL_ L_EVNT SG_ 304 L_ATCU_CTS_RrDrEVntConsBdryUp_Y 5000;
BA_ "Version" SG_ 304 L_ATCU_CTS_RrDrEVntConsBdryUp_Y "24.05.11";
BA_ "GenMsgSendType" BO_ 1025 0;
BA_ "GenMsgCycleTime" BO_ 1025 1000;
BA_ "Description" SG_ 1025 L_EVNT_HU_FrDrEVntSidePtDisp_X "Electric Vent Frt Driver Side Electric Vent Touch Range X Coordinate Display Feedback (To CTS)";
BA_ "GenSigSendType" SG_ 1025 L_EVNT_HU_FrDrEVntSidePtDisp_X 4;
BA_ "UserSigValidity" SG_ 1025 L_EVNT_HU_FrDrEVntSidePtDisp_X 7;
BA_REL_ "GenSigTimeoutTime" BU_SG_REL_ L_ATCU SG_ 1025 L_EVNT_HU_FrDrEVntSidePtDisp_X 5000;
BA_ "Version" SG_ 1025 L_EVNT_HU_FrDrEVntSidePtDisp_X "24.05.11";
BA_ "Description" SG_ 1025 L_EVNT_HU_FrDrEVntSidePtDisp_Y "Electric Vent Frt Driver Side Electric Vent Touch Range Y Coordinate Display Feedback (To CTS)";
BA_ "GenSigSendType" SG_ 1025 L_EVNT_HU_FrDrEVntSidePtDisp_Y 4;
BA_ "UserSigValidity" SG_ 1025 L_EVNT_HU_FrDrEVntSidePtDisp_Y 7;
BA_REL_ "GenSigTimeoutTime" BU_SG_REL_ L_ATCU SG_ 1025 L_EVNT_HU_FrDrEVntSidePtDisp_Y 5000;
BA_ "Version" SG_ 1025 L_EVNT_HU_FrDrEVntSidePtDisp_Y "24.05.11";
BA_ "Description" SG_ 1025 L_EVNT_HU_FrDrEVntCtrPtDisp_X "Electric Vent Frt Driver Center Electric Vent Touch Range X Coordinate Display Feedback (To CTS)";
BA_ "GenSigSendType" SG_ 1025 L_EVNT_HU_FrDrEVntCtrPtDisp_X 4;
BA_ "UserSigValidity" SG_ 1025 L_EVNT_HU_FrDrEVntCtrPtDisp_X 7;
BA_REL_ "GenSigTimeoutTime" BU_SG_REL_ L_ATCU SG_ 1025 L_EVNT_HU_FrDrEVntCtrPtDisp_X 5000;
BA_ "Version" SG_ 1025 L_EVNT_HU_FrDrEVntCtrPtDisp_X "24.05.11";
BA_ "Description" SG_ 1025 L_EVNT_HU_FrDrEVntCtrPtDisp_Y "Electric Vent Frt Driver Center Electric Vent Touch Range Y Coordinate Display Feedback (To CTS)";
BA_ "GenSigSendType" SG_ 1025 L_EVNT_HU_FrDrEVntCtrPtDisp_Y 4;
BA_ "UserSigValidity" SG_ 1025 L_EVNT_HU_FrDrEVntCtrPtDisp_Y 7;
BA_REL_ "GenSigTimeoutTime" BU_SG_REL_ L_ATCU SG_ 1025 L_EVNT_HU_FrDrEVntCtrPtDisp_Y 5000;
BA_ "Version" SG_ 1025 L_EVNT_HU_FrDrEVntCtrPtDisp_Y "24.05.11";
BA_ "GenMsgSendType" BO_ 1026 0;
BA_ "GenMsgCycleTime" BO_ 1026 1000;
BA_ "Description" SG_ 1026 L_EVNT_HU_FrPsEVntSidePtDisp_X "Electric Vent Frt Passenger Side Electric Vent Touch Range X Coordinate Display Feedback (To CTS)";
BA_ "GenSigSendType" SG_ 1026 L_EVNT_HU_FrPsEVntSidePtDisp_X 4;
BA_ "UserSigValidity" SG_ 1026 L_EVNT_HU_FrPsEVntSidePtDisp_X 7;
BA_REL_ "GenSigTimeoutTime" BU_SG_REL_ L_ATCU SG_ 1026 L_EVNT_HU_FrPsEVntSidePtDisp_X 5000;
BA_ "Version" SG_ 1026 L_EVNT_HU_FrPsEVntSidePtDisp_X "24.05.11";
BA_ "Description" SG_ 1026 L_EVNT_HU_FrPsEVntSidePtDisp_Y "Electric Vent Frt Passenger Side Electric Vent Touch Range Y Coordinate Display Feedback (To CTS)";
BA_ "GenSigSendType" SG_ 1026 L_EVNT_HU_FrPsEVntSidePtDisp_Y 4;
BA_ "UserSigValidity" SG_ 1026 L_EVNT_HU_FrPsEVntSidePtDisp_Y 7;
BA_REL_ "GenSigTimeoutTime" BU_SG_REL_ L_ATCU SG_ 1026 L_EVNT_HU_FrPsEVntSidePtDisp_Y 5000;
BA_ "Version" SG_ 1026 L_EVNT_HU_FrPsEVntSidePtDisp_Y "24.05.11";
BA_ "Description" SG_ 1026 L_EVNT_HU_FrPsEVntCtrPtDisp_X "Electric Vent Frt Passenger Center Electric Vent Touch Range X Coordinate Display Feedback (To CTS)";
BA_ "GenSigSendType" SG_ 1026 L_EVNT_HU_FrPsEVntCtrPtDisp_X 4;
BA_ "UserSigValidity" SG_ 1026 L_EVNT_HU_FrPsEVntCtrPtDisp_X 7;
BA_REL_ "GenSigTimeoutTime" BU_SG_REL_ L_ATCU SG_ 1026 L_EVNT_HU_FrPsEVntCtrPtDisp_X 5000;
BA_ "Version" SG_ 1026 L_EVNT_HU_FrPsEVntCtrPtDisp_X "24.05.11";
BA_ "Description" SG_ 1026 L_EVNT_HU_FrPsEVntCtrPtDisp_Y "Electric Vent Frt Passenger Center Electric Vent Touch Range Y Coordinate Display Feedback (To CTS)";
BA_ "GenSigSendType" SG_ 1026 L_EVNT_HU_FrPsEVntCtrPtDisp_Y 4;
BA_ "UserSigValidity" SG_ 1026 L_EVNT_HU_FrPsEVntCtrPtDisp_Y 7;
BA_REL_ "GenSigTimeoutTime" BU_SG_REL_ L_ATCU SG_ 1026 L_EVNT_HU_FrPsEVntCtrPtDisp_Y 5000;
BA_ "Version" SG_ 1026 L_EVNT_HU_FrPsEVntCtrPtDisp_Y "24.05.11";
BA_ "GenMsgSendType" BO_ 1027 0;
BA_ "GenMsgCycleTime" BO_ 1027 1000;
BA_ "Description" SG_ 1027 L_EVNT_HU_RrDrEVntConsPtDisp_X "Electric Vent Rear Driver Console Touch Range X Coordinate Display Feedback (To CTS)";
BA_ "GenSigSendType" SG_ 1027 L_EVNT_HU_RrDrEVntConsPtDisp_X 4;
BA_ "UserSigValidity" SG_ 1027 L_EVNT_HU_RrDrEVntConsPtDisp_X 7;
BA_REL_ "GenSigTimeoutTime" BU_SG_REL_ L_ATCU SG_ 1027 L_EVNT_HU_RrDrEVntConsPtDisp_X 5000;
BA_ "Version" SG_ 1027 L_EVNT_HU_RrDrEVntConsPtDisp_X "24.05.11";
BA_ "Description" SG_ 1027 L_EVNT_HU_RrDrEVntConsPtDisp_Y "Electric Vent Rear Driver Console Touch Range Y Coordinate Display Feedback (To CTS)";
BA_ "GenSigSendType" SG_ 1027 L_EVNT_HU_RrDrEVntConsPtDisp_Y 4;
BA_ "UserSigValidity" SG_ 1027 L_EVNT_HU_RrDrEVntConsPtDisp_Y 7;
BA_REL_ "GenSigTimeoutTime" BU_SG_REL_ L_ATCU SG_ 1027 L_EVNT_HU_RrDrEVntConsPtDisp_Y 5000;
BA_ "Version" SG_ 1027 L_EVNT_HU_RrDrEVntConsPtDisp_Y "24.05.11";
BA_ "Description" SG_ 1027 L_EVNT_HU_RrPsEVntConsPtDisp_X "Electric Vent Rear Passenger Console Touch Range X Coordinate Display Feedback (To CTS)";
BA_ "GenSigSendType" SG_ 1027 L_EVNT_HU_RrPsEVntConsPtDisp_X 4;
BA_ "UserSigValidity" SG_ 1027 L_EVNT_HU_RrPsEVntConsPtDisp_X 7;
BA_REL_ "GenSigTimeoutTime" BU_SG_REL_ L_ATCU SG_ 1027 L_EVNT_HU_RrPsEVntConsPtDisp_X 5000;
BA_ "Version" SG_ 1027 L_EVNT_HU_RrPsEVntConsPtDisp_X "24.05.11";
BA_ "Description" SG_ 1027 L_EVNT_HU_RrPsEVntConsPtDisp_Y "Electric Vent Rear Passenger Console Touch Range Y Coordinate Display Feedback (To CTS)";
BA_ "GenSigSendType" SG_ 1027 L_EVNT_HU_RrPsEVntConsPtDisp_Y 4;
BA_ "UserSigValidity" SG_ 1027 L_EVNT_HU_RrPsEVntConsPtDisp_Y 7;
BA_REL_ "GenSigTimeoutTime" BU_SG_REL_ L_ATCU SG_ 1027 L_EVNT_HU_RrPsEVntConsPtDisp_Y 5000;
BA_ "Version" SG_ 1027 L_EVNT_HU_RrPsEVntConsPtDisp_Y "24.05.11";
BA_ "Description" SG_ 1027 L_EVNT_FrDrEVntSideFlt "Front Driver Electric Vent Side Fault Status";
BA_ "GenSigSendType" SG_ 1027 L_EVNT_FrDrEVntSideFlt 4;
BA_ "UserSigValidity" SG_ 1027 L_EVNT_FrDrEVntSideFlt 7;
BA_REL_ "GenSigTimeoutTime" BU_SG_REL_ L_ATCU SG_ 1027 L_EVNT_FrDrEVntSideFlt 5000;
BA_ "Version" SG_ 1027 L_EVNT_FrDrEVntSideFlt "24.05.11";
BA_ "Description" SG_ 1027 L_EVNT_FrDrEVntCtrFlt "Front Driver Electric Vent Center Fault Status";
BA_ "GenSigSendType" SG_ 1027 L_EVNT_FrDrEVntCtrFlt 4;
BA_ "UserSigValidity" SG_ 1027 L_EVNT_FrDrEVntCtrFlt 7;
BA_REL_ "GenSigTimeoutTime" BU_SG_REL_ L_ATCU SG_ 1027 L_EVNT_FrDrEVntCtrFlt 5000;
BA_ "Version" SG_ 1027 L_EVNT_FrDrEVntCtrFlt "24.05.11";
BA_ "Description" SG_ 1027 L_EVNT_FrPsEVntSideFlt "Front Passenger Electric Vent Side Fault Status";
BA_ "GenSigSendType" SG_ 1027 L_EVNT_FrPsEVntSideFlt 4;
BA_ "UserSigValidity" SG_ 1027 L_EVNT_FrPsEVntSideFlt 7;
BA_REL_ "GenSigTimeoutTime" BU_SG_REL_ L_ATCU SG_ 1027 L_EVNT_FrPsEVntSideFlt 5000;
BA_ "Version" SG_ 1027 L_EVNT_FrPsEVntSideFlt "24.05.11";
BA_ "Description" SG_ 1027 L_EVNT_FrPsEVntCtrFlt "Front Passenger Electric Vent Center Fault Status";
BA_ "GenSigSendType" SG_ 1027 L_EVNT_FrPsEVntCtrFlt 4;
BA_ "UserSigValidity" SG_ 1027 L_EVNT_FrPsEVntCtrFlt 7;
BA_REL_ "GenSigTimeoutTime" BU_SG_REL_ L_ATCU SG_ 1027 L_EVNT_FrPsEVntCtrFlt 5000;
BA_ "Version" SG_ 1027 L_EVNT_FrPsEVntCtrFlt "24.05.11";
BA_ "Description" SG_ 1027 L_EVNT_RrDrEVntConsFlt "Front Rear (2nd) Driver Electric Vent Console Fault Status";
BA_ "GenSigSendType" SG_ 1027 L_EVNT_RrDrEVntConsFlt 4;
BA_ "UserSigValidity" SG_ 1027 L_EVNT_RrDrEVntConsFlt 7;
BA_REL_ "GenSigTimeoutTime" BU_SG_REL_ L_ATCU SG_ 1027 L_EVNT_RrDrEVntConsFlt 5000;
BA_ "Version" SG_ 1027 L_EVNT_RrDrEVntConsFlt "24.05.11";
BA_ "Description" SG_ 1027 L_EVNT_RrPsEVntConsFlt "Front Rear (2nd) Passenger Electric Vent Console Fault Status";
BA_ "GenSigSendType" SG_ 1027 L_EVNT_RrPsEVntConsFlt 4;
BA_ "UserSigValidity" SG_ 1027 L_EVNT_RrPsEVntConsFlt 7;
BA_REL_ "GenSigTimeoutTime" BU_SG_REL_ L_ATCU SG_ 1027 L_EVNT_RrPsEVntConsFlt 5000;
BA_ "Version" SG_ 1027 L_EVNT_RrPsEVntConsFlt "24.05.11";
BA_ "GenMsgSendType" BO_ 1028 0;
BA_ "GenMsgCycleTime" BO_ 1028 1000;
BA_ "Description" SG_ 1028 L_EVNT_FrDrEVntModeSet_Disp "Electric Vent Frt Driver Mode Signal Display Feedback";
BA_ "GenSigSendType" SG_ 1028 L_EVNT_FrDrEVntModeSet_Disp 4;
BA_ "UserSigValidity" SG_ 1028 L_EVNT_FrDrEVntModeSet_Disp 7;
BA_REL_ "GenSigTimeoutTime" BU_SG_REL_ L_ATCU SG_ 1028 L_EVNT_FrDrEVntModeSet_Disp 5000;
BA_ "Version" SG_ 1028 L_EVNT_FrDrEVntModeSet_Disp "24.08.00";
BA_ "Description" SG_ 1028 L_EVNT_RrPsEVntModeSet_Disp "Electric Vent Rear Passenger Mode Signal Display Feedback";
BA_ "GenSigSendType" SG_ 1028 L_EVNT_RrPsEVntModeSet_Disp 4;
BA_ "UserSigValidity" SG_ 1028 L_EVNT_RrPsEVntModeSet_Disp 7;
BA_REL_ "GenSigTimeoutTime" BU_SG_REL_ L_ATCU SG_ 1028 L_EVNT_RrPsEVntModeSet_Disp 5000;
BA_ "Version" SG_ 1028 L_EVNT_RrPsEVntModeSet_Disp "24.08.00";
BA_ "Description" SG_ 1028 L_EVNT_FrDrEVntSideOpnClsDisp "Electric Vent Frt Driver Side Vent Open/Close Signal Display Feedback";
BA_ "GenSigSendType" SG_ 1028 L_EVNT_FrDrEVntSideOpnClsDisp 4;
BA_ "UserSigValidity" SG_ 1028 L_EVNT_FrDrEVntSideOpnClsDisp 7;
BA_REL_ "GenSigTimeoutTime" BU_SG_REL_ L_ATCU SG_ 1028 L_EVNT_FrDrEVntSideOpnClsDisp 5000;
BA_ "Version" SG_ 1028 L_EVNT_FrDrEVntSideOpnClsDisp "24.05.11";
BA_ "Description" SG_ 1028 L_EVNT_FrDrEVntCtrOpnClsDisp "Electric Vent Frt Driver Center Vent Open/Close Signal Display Feedback";
BA_ "GenSigSendType" SG_ 1028 L_EVNT_FrDrEVntCtrOpnClsDisp 4;
BA_ "UserSigValidity" SG_ 1028 L_EVNT_FrDrEVntCtrOpnClsDisp 7;
BA_REL_ "GenSigTimeoutTime" BU_SG_REL_ L_ATCU SG_ 1028 L_EVNT_FrDrEVntCtrOpnClsDisp 5000;
BA_ "Version" SG_ 1028 L_EVNT_FrDrEVntCtrOpnClsDisp "24.05.11";
BA_ "Description" SG_ 1028 L_EVNT_FrPsEVntSideOpnClsDisp "Electric Vent Frt Passenger Side Vent Open/Close Signal Display Feedback";
BA_ "GenSigSendType" SG_ 1028 L_EVNT_FrPsEVntSideOpnClsDisp 4;
BA_ "UserSigValidity" SG_ 1028 L_EVNT_FrPsEVntSideOpnClsDisp 7;
BA_REL_ "GenSigTimeoutTime" BU_SG_REL_ L_ATCU SG_ 1028 L_EVNT_FrPsEVntSideOpnClsDisp 5000;
BA_ "Version" SG_ 1028 L_EVNT_FrPsEVntSideOpnClsDisp "24.05.11";
BA_ "Description" SG_ 1028 L_EVNT_FrPsEVntCtrOpnClsDisp "Electric Vent Frt Passenger Center Vent Open/Close Signal Display Feedback";
BA_ "GenSigSendType" SG_ 1028 L_EVNT_FrPsEVntCtrOpnClsDisp 4;
BA_ "UserSigValidity" SG_ 1028 L_EVNT_FrPsEVntCtrOpnClsDisp 7;
BA_REL_ "GenSigTimeoutTime" BU_SG_REL_ L_ATCU SG_ 1028 L_EVNT_FrPsEVntCtrOpnClsDisp 5000;
BA_ "Version" SG_ 1028 L_EVNT_FrPsEVntCtrOpnClsDisp "24.05.11";
BA_ "Description" SG_ 1028 L_EVNT_RrDrEVntConsOpnClsDisp "Electric Vent Rear Driver Console Vent Open/Close Signal Display Feedback";
BA_ "GenSigSendType" SG_ 1028 L_EVNT_RrDrEVntConsOpnClsDisp 4;
BA_ "UserSigValidity" SG_ 1028 L_EVNT_RrDrEVntConsOpnClsDisp 7;
BA_REL_ "GenSigTimeoutTime" BU_SG_REL_ L_ATCU SG_ 1028 L_EVNT_RrDrEVntConsOpnClsDisp 5000;
BA_ "Version" SG_ 1028 L_EVNT_RrDrEVntConsOpnClsDisp "24.05.11";
BA_ "Description" SG_ 1028 L_EVNT_RrPsEVntConsOpnClsDisp "Electric Vent Rear Passenger Console Vent Open/Close Signal Display Feedback";
BA_ "GenSigSendType" SG_ 1028 L_EVNT_RrPsEVntConsOpnClsDisp 4;
BA_ "UserSigValidity" SG_ 1028 L_EVNT_RrPsEVntConsOpnClsDisp 7;
BA_REL_ "GenSigTimeoutTime" BU_SG_REL_ L_ATCU SG_ 1028 L_EVNT_RrPsEVntConsOpnClsDisp 5000;
BA_ "Version" SG_ 1028 L_EVNT_RrPsEVntConsOpnClsDisp "24.05.11";
BA_ "Description" SG_ 1028 L_EVNT_EVntTouchInform_HU "Electric Vent touch available information to HU_MM (prevent input from CTS)";
BA_ "GenSigSendType" SG_ 1028 L_EVNT_EVntTouchInform_HU 4;
BA_ "UserSigValidity" SG_ 1028 L_EVNT_EVntTouchInform_HU 7;
BA_REL_ "GenSigTimeoutTime" BU_SG_REL_ L_ATCU SG_ 1028 L_EVNT_EVntTouchInform_HU 5000;
BA_ "Version" SG_ 1028 L_EVNT_EVntTouchInform_HU "24.05.11";
BA_ "Description" SG_ 1028 L_EVNT_EVntTouchInform_CTS "Electric Vent touch available information to CTS (prevent input from HU_MM)";
BA_ "GenSigSendType" SG_ 1028 L_EVNT_EVntTouchInform_CTS 4;
BA_ "UserSigValidity" SG_ 1028 L_EVNT_EVntTouchInform_CTS 7;
BA_REL_ "GenSigTimeoutTime" BU_SG_REL_ L_ATCU SG_ 1028 L_EVNT_EVntTouchInform_CTS 5000;
BA_ "Version" SG_ 1028 L_EVNT_EVntTouchInform_CTS "24.05.11";
BA_ "Description" SG_ 1028 L_EVNT_FrPsEVntModeSet_Disp "Electric Vent Frt Passenger Mode Signal Display Feedback";
BA_ "GenSigSendType" SG_ 1028 L_EVNT_FrPsEVntModeSet_Disp 4;
BA_ "UserSigValidity" SG_ 1028 L_EVNT_FrPsEVntModeSet_Disp 7;
BA_REL_ "GenSigTimeoutTime" BU_SG_REL_ L_ATCU SG_ 1028 L_EVNT_FrPsEVntModeSet_Disp 5000;
BA_ "Version" SG_ 1028 L_EVNT_FrPsEVntModeSet_Disp "24.08.00";
BA_ "Description" SG_ 1028 L_EVNT_RrDrEVntModeSet_Disp "Electric Vent Rear Driver Mode Signal Display Feedback";
BA_ "GenSigSendType" SG_ 1028 L_EVNT_RrDrEVntModeSet_Disp 4;
BA_ "UserSigValidity" SG_ 1028 L_EVNT_RrDrEVntModeSet_Disp 7;
BA_REL_ "GenSigTimeoutTime" BU_SG_REL_ L_ATCU SG_ 1028 L_EVNT_RrDrEVntModeSet_Disp 5000;
BA_ "Version" SG_ 1028 L_EVNT_RrDrEVntModeSet_Disp "24.08.00";
BA_ "GenMsgSendType" BO_ 1029 0;
BA_ "GenMsgCycleTime" BO_ 1029 1000;
BA_ "Description" SG_ 1029 L_EVNT_CTS_FrDrEVntSidePtDisp_X "Electric Vent Frt Driver Side Electric Vent Touch Range X Coordinate Display Feedback (To CTS)";
BA_ "GenSigSendType" SG_ 1029 L_EVNT_CTS_FrDrEVntSidePtDisp_X 4;
BA_ "UserSigValidity" SG_ 1029 L_EVNT_CTS_FrDrEVntSidePtDisp_X 7;
BA_REL_ "GenSigTimeoutTime" BU_SG_REL_ L_ATCU SG_ 1029 L_EVNT_CTS_FrDrEVntSidePtDisp_X 5000;
BA_ "Version" SG_ 1029 L_EVNT_CTS_FrDrEVntSidePtDisp_X "24.05.11";
BA_ "Description" SG_ 1029 L_EVNT_CTS_FrDrEVntSidePtDisp_Y "Electric Vent Frt Driver Side Electric Vent Touch Range Y Coordinate Display Feedback (To CTS)";
BA_ "GenSigSendType" SG_ 1029 L_EVNT_CTS_FrDrEVntSidePtDisp_Y 4;
BA_ "UserSigValidity" SG_ 1029 L_EVNT_CTS_FrDrEVntSidePtDisp_Y 7;
BA_REL_ "GenSigTimeoutTime" BU_SG_REL_ L_ATCU SG_ 1029 L_EVNT_CTS_FrDrEVntSidePtDisp_Y 5000;
BA_ "Version" SG_ 1029 L_EVNT_CTS_FrDrEVntSidePtDisp_Y "24.05.11";
BA_ "Description" SG_ 1029 L_EVNT_CTS_FrDrEVntCtrPtDisp_X "Electric Vent Frt Driver Center Electric Vent Touch Range X Coordinate Display Feedback (To CTS)";
BA_ "GenSigSendType" SG_ 1029 L_EVNT_CTS_FrDrEVntCtrPtDisp_X 4;
BA_ "UserSigValidity" SG_ 1029 L_EVNT_CTS_FrDrEVntCtrPtDisp_X 7;
BA_REL_ "GenSigTimeoutTime" BU_SG_REL_ L_ATCU SG_ 1029 L_EVNT_CTS_FrDrEVntCtrPtDisp_X 5000;
BA_ "Version" SG_ 1029 L_EVNT_CTS_FrDrEVntCtrPtDisp_X "24.05.11";
BA_ "Description" SG_ 1029 L_EVNT_CTS_FrDrEVntCtrPtDisp_Y "Electric Vent Frt Driver Center Electric Vent Touch Range Y Coordinate Display Feedback (To CTS)";
BA_ "GenSigSendType" SG_ 1029 L_EVNT_CTS_FrDrEVntCtrPtDisp_Y 4;
BA_ "UserSigValidity" SG_ 1029 L_EVNT_CTS_FrDrEVntCtrPtDisp_Y 7;
BA_REL_ "GenSigTimeoutTime" BU_SG_REL_ L_ATCU SG_ 1029 L_EVNT_CTS_FrDrEVntCtrPtDisp_Y 5000;
BA_ "Version" SG_ 1029 L_EVNT_CTS_FrDrEVntCtrPtDisp_Y "24.05.11";
BA_ "GenMsgSendType" BO_ 1030 0;
BA_ "GenMsgCycleTime" BO_ 1030 1000;
BA_ "Description" SG_ 1030 L_EVNT_CTS_FrPsEVntSidePtDisp_X "Electric Vent Frt Passenger Side Electric Vent Touch Range X Coordinate Display Feedback (To CTS)";
BA_ "GenSigSendType" SG_ 1030 L_EVNT_CTS_FrPsEVntSidePtDisp_X 4;
BA_ "UserSigValidity" SG_ 1030 L_EVNT_CTS_FrPsEVntSidePtDisp_X 7;
BA_REL_ "GenSigTimeoutTime" BU_SG_REL_ L_ATCU SG_ 1030 L_EVNT_CTS_FrPsEVntSidePtDisp_X 5000;
BA_ "Version" SG_ 1030 L_EVNT_CTS_FrPsEVntSidePtDisp_X "24.05.11";
BA_ "Description" SG_ 1030 L_EVNT_CTS_FrPsEVntSidePtDisp_Y "Electric Vent Frt Passenger Side Electric Vent Touch Range Y Coordinate Display Feedback (To CTS)";
BA_ "GenSigSendType" SG_ 1030 L_EVNT_CTS_FrPsEVntSidePtDisp_Y 4;
BA_ "UserSigValidity" SG_ 1030 L_EVNT_CTS_FrPsEVntSidePtDisp_Y 7;
BA_REL_ "GenSigTimeoutTime" BU_SG_REL_ L_ATCU SG_ 1030 L_EVNT_CTS_FrPsEVntSidePtDisp_Y 5000;
BA_ "Version" SG_ 1030 L_EVNT_CTS_FrPsEVntSidePtDisp_Y "24.05.11";
BA_ "Description" SG_ 1030 L_EVNT_CTS_FrPsEVntCtrPtDisp_X "Electric Vent Frt Passenger Center Electric Vent Touch Range X Coordinate Display Feedback (To CTS)";
BA_ "GenSigSendType" SG_ 1030 L_EVNT_CTS_FrPsEVntCtrPtDisp_X 4;
BA_ "UserSigValidity" SG_ 1030 L_EVNT_CTS_FrPsEVntCtrPtDisp_X 7;
BA_REL_ "GenSigTimeoutTime" BU_SG_REL_ L_ATCU SG_ 1030 L_EVNT_CTS_FrPsEVntCtrPtDisp_X 5000;
BA_ "Version" SG_ 1030 L_EVNT_CTS_FrPsEVntCtrPtDisp_X "24.05.11";
BA_ "Description" SG_ 1030 L_EVNT_CTS_FrPsEVntCtrPtDisp_Y "Electric Vent Frt Passenger Center Electric Vent Touch Range Y Coordinate Display Feedback (To CTS)";
BA_ "GenSigSendType" SG_ 1030 L_EVNT_CTS_FrPsEVntCtrPtDisp_Y 4;
BA_ "UserSigValidity" SG_ 1030 L_EVNT_CTS_FrPsEVntCtrPtDisp_Y 7;
BA_REL_ "GenSigTimeoutTime" BU_SG_REL_ L_ATCU SG_ 1030 L_EVNT_CTS_FrPsEVntCtrPtDisp_Y 5000;
BA_ "Version" SG_ 1030 L_EVNT_CTS_FrPsEVntCtrPtDisp_Y "24.05.11";
BA_ "GenMsgSendType" BO_ 1031 0;
BA_ "GenMsgCycleTime" BO_ 1031 1000;
BA_ "Description" SG_ 1031 L_EVNT_CTS_RrDrEVntConsPtDisp_X "Electric Vent Rear Driver Console Touch Range X Coordinate Display Feedback (To CTS)";
BA_ "GenSigSendType" SG_ 1031 L_EVNT_CTS_RrDrEVntConsPtDisp_X 4;
BA_ "UserSigValidity" SG_ 1031 L_EVNT_CTS_RrDrEVntConsPtDisp_X 7;
BA_REL_ "GenSigTimeoutTime" BU_SG_REL_ L_ATCU SG_ 1031 L_EVNT_CTS_RrDrEVntConsPtDisp_X 5000;
BA_ "Version" SG_ 1031 L_EVNT_CTS_RrDrEVntConsPtDisp_X "24.05.11";
BA_ "Description" SG_ 1031 L_EVNT_CTS_RrDrEVntConsPtDisp_Y "Electric Vent Rear Driver Console Touch Range Y Coordinate Display Feedback (To CTS)";
BA_ "GenSigSendType" SG_ 1031 L_EVNT_CTS_RrDrEVntConsPtDisp_Y 4;
BA_ "UserSigValidity" SG_ 1031 L_EVNT_CTS_RrDrEVntConsPtDisp_Y 7;
BA_REL_ "GenSigTimeoutTime" BU_SG_REL_ L_ATCU SG_ 1031 L_EVNT_CTS_RrDrEVntConsPtDisp_Y 5000;
BA_ "Version" SG_ 1031 L_EVNT_CTS_RrDrEVntConsPtDisp_Y "24.05.11";
BA_ "Description" SG_ 1031 L_EVNT_CTS_RrPsEVntConsPtDisp_X "Electric Vent Rear Passenger Console Touch Range X Coordinate Display Feedback (To CTS)";
BA_ "GenSigSendType" SG_ 1031 L_EVNT_CTS_RrPsEVntConsPtDisp_X 4;
BA_ "UserSigValidity" SG_ 1031 L_EVNT_CTS_RrPsEVntConsPtDisp_X 7;
BA_REL_ "GenSigTimeoutTime" BU_SG_REL_ L_ATCU SG_ 1031 L_EVNT_CTS_RrPsEVntConsPtDisp_X 5000;
BA_ "Version" SG_ 1031 L_EVNT_CTS_RrPsEVntConsPtDisp_X "24.05.11";
BA_ "Description" SG_ 1031 L_EVNT_CTS_RrPsEVntConsPtDisp_Y "Electric Vent Rear Passenger Console Touch Range Y Coordinate Display Feedback (To CTS)";
BA_ "GenSigSendType" SG_ 1031 L_EVNT_CTS_RrPsEVntConsPtDisp_Y 4;
BA_ "UserSigValidity" SG_ 1031 L_EVNT_CTS_RrPsEVntConsPtDisp_Y 7;
BA_REL_ "GenSigTimeoutTime" BU_SG_REL_ L_ATCU SG_ 1031 L_EVNT_CTS_RrPsEVntConsPtDisp_Y 5000;
BA_ "Version" SG_ 1031 L_EVNT_CTS_RrPsEVntConsPtDisp_Y "24.05.11";
BA_ "GenMsgSendType" BO_ 1032 0;
BA_ "GenMsgCycleTime" BO_ 1032 1000;
BA_ "GenSigSendType" SG_ 1032 L_EVNT_ATCUComFlt 4;
BA_ "UserSigValidity" SG_ 1032 L_EVNT_ATCUComFlt 7;
BA_REL_ "GenSigTimeoutTime" BU_SG_REL_ L_ATCU SG_ 1032 L_EVNT_ATCUComFlt 5000;
BA_ "Version" SG_ 1032 L_EVNT_ATCUComFlt "24.05.11";
BA_ "GenSigSendType" SG_ 1032 L_EVNT_DrvCntrHorComFlt 4;
BA_ "UserSigValidity" SG_ 1032 L_EVNT_DrvCntrHorComFlt 7;
BA_REL_ "GenSigTimeoutTime" BU_SG_REL_ L_ATCU SG_ 1032 L_EVNT_DrvCntrHorComFlt 5000;
BA_ "Version" SG_ 1032 L_EVNT_DrvCntrHorComFlt "24.05.11";
BA_ "GenSigSendType" SG_ 1032 L_EVNT_AstSdVertComFlt 4;
BA_ "UserSigValidity" SG_ 1032 L_EVNT_AstSdVertComFlt 7;
BA_REL_ "GenSigTimeoutTime" BU_SG_REL_ L_ATCU SG_ 1032 L_EVNT_AstSdVertComFlt 5000;
BA_ "Version" SG_ 1032 L_EVNT_AstSdVertComFlt "24.05.11";
BA_ "GenSigSendType" SG_ 1032 L_EVNT_AstSdHorComFlt 4;
BA_ "UserSigValidity" SG_ 1032 L_EVNT_AstSdHorComFlt 7;
BA_REL_ "GenSigTimeoutTime" BU_SG_REL_ L_ATCU SG_ 1032 L_EVNT_AstSdHorComFlt 5000;
BA_ "Version" SG_ 1032 L_EVNT_AstSdHorComFlt "24.05.11";
BA_ "GenSigSendType" SG_ 1032 L_EVNT_AstCntrVertComFlt 4;
BA_ "UserSigValidity" SG_ 1032 L_EVNT_AstCntrVertComFlt 7;
BA_REL_ "GenSigTimeoutTime" BU_SG_REL_ L_ATCU SG_ 1032 L_EVNT_AstCntrVertComFlt 5000;
BA_ "Version" SG_ 1032 L_EVNT_AstCntrVertComFlt "24.05.11";
BA_ "GenSigSendType" SG_ 1032 L_EVNT_AstCntrHorComFlt 4;
BA_ "UserSigValidity" SG_ 1032 L_EVNT_AstCntrHorComFlt 7;
BA_REL_ "GenSigTimeoutTime" BU_SG_REL_ L_ATCU SG_ 1032 L_EVNT_AstCntrHorComFlt 5000;
BA_ "Version" SG_ 1032 L_EVNT_AstCntrHorComFlt "24.05.11";
BA_ "GenSigSendType" SG_ 1032 L_EVNT_EVNTFlt 4;
BA_ "UserSigValidity" SG_ 1032 L_EVNT_EVNTFlt 7;
BA_REL_ "GenSigTimeoutTime" BU_SG_REL_ L_ATCU SG_ 1032 L_EVNT_EVNTFlt 5000;
BA_ "Version" SG_ 1032 L_EVNT_EVNTFlt "24.05.11";
BA_ "GenSigSendType" SG_ 1032 L_EVNT_RrDrvCnslVertComFlt 4;
BA_ "UserSigValidity" SG_ 1032 L_EVNT_RrDrvCnslVertComFlt 7;
BA_REL_ "GenSigTimeoutTime" BU_SG_REL_ L_ATCU SG_ 1032 L_EVNT_RrDrvCnslVertComFlt 5000;
BA_ "Version" SG_ 1032 L_EVNT_RrDrvCnslVertComFlt "24.05.11";
BA_ "GenSigSendType" SG_ 1032 L_EVNT_RrDrvCnslHorComFlt 4;
BA_ "UserSigValidity" SG_ 1032 L_EVNT_RrDrvCnslHorComFlt 7;
BA_REL_ "GenSigTimeoutTime" BU_SG_REL_ L_ATCU SG_ 1032 L_EVNT_RrDrvCnslHorComFlt 5000;
BA_ "Version" SG_ 1032 L_EVNT_RrDrvCnslHorComFlt "24.05.11";
BA_ "GenSigSendType" SG_ 1032 L_EVNT_RrAstCnslVertComFlt 4;
BA_ "UserSigValidity" SG_ 1032 L_EVNT_RrAstCnslVertComFlt 7;
BA_REL_ "GenSigTimeoutTime" BU_SG_REL_ L_ATCU SG_ 1032 L_EVNT_RrAstCnslVertComFlt 5000;
BA_ "Version" SG_ 1032 L_EVNT_RrAstCnslVertComFlt "24.05.11";
BA_ "GenSigSendType" SG_ 1032 L_EVNT_RrAstCnslHorComFlt 4;
BA_ "UserSigValidity" SG_ 1032 L_EVNT_RrAstCnslHorComFlt 7;
BA_REL_ "GenSigTimeoutTime" BU_SG_REL_ L_ATCU SG_ 1032 L_EVNT_RrAstCnslHorComFlt 5000;
BA_ "Version" SG_ 1032 L_EVNT_RrAstCnslHorComFlt "24.05.11";
BA_ "GenSigSendType" SG_ 1032 L_EVNT_DrvSdVertIntFlt 4;
BA_ "UserSigValidity" SG_ 1032 L_EVNT_DrvSdVertIntFlt 7;
BA_REL_ "GenSigTimeoutTime" BU_SG_REL_ L_ATCU SG_ 1032 L_EVNT_DrvSdVertIntFlt 5000;
BA_ "Version" SG_ 1032 L_EVNT_DrvSdVertIntFlt "24.05.11";
BA_ "GenSigSendType" SG_ 1032 L_EVNT_DrvSdHorIntFlt 4;
BA_ "UserSigValidity" SG_ 1032 L_EVNT_DrvSdHorIntFlt 7;
BA_REL_ "GenSigTimeoutTime" BU_SG_REL_ L_ATCU SG_ 1032 L_EVNT_DrvSdHorIntFlt 5000;
BA_ "Version" SG_ 1032 L_EVNT_DrvSdHorIntFlt "24.05.11";
BA_ "GenSigSendType" SG_ 1032 L_EVNT_DrvCntrVertIntFlt 4;
BA_ "UserSigValidity" SG_ 1032 L_EVNT_DrvCntrVertIntFlt 7;
BA_REL_ "GenSigTimeoutTime" BU_SG_REL_ L_ATCU SG_ 1032 L_EVNT_DrvCntrVertIntFlt 5000;
BA_ "Version" SG_ 1032 L_EVNT_DrvCntrVertIntFlt "24.05.11";
BA_ "GenSigSendType" SG_ 1032 L_EVNT_DrvCntrHorIntFlt 4;
BA_ "UserSigValidity" SG_ 1032 L_EVNT_DrvCntrHorIntFlt 7;
BA_REL_ "GenSigTimeoutTime" BU_SG_REL_ L_ATCU SG_ 1032 L_EVNT_DrvCntrHorIntFlt 5000;
BA_ "Version" SG_ 1032 L_EVNT_DrvCntrHorIntFlt "24.05.11";
BA_ "GenSigSendType" SG_ 1032 L_EVNT_AstSdVertIntFlt 4;
BA_ "UserSigValidity" SG_ 1032 L_EVNT_AstSdVertIntFlt 7;
BA_REL_ "GenSigTimeoutTime" BU_SG_REL_ L_ATCU SG_ 1032 L_EVNT_AstSdVertIntFlt 5000;
BA_ "Version" SG_ 1032 L_EVNT_AstSdVertIntFlt "24.05.11";
BA_ "GenSigSendType" SG_ 1032 L_EVNT_AstSdHorIntFlt 4;
BA_ "UserSigValidity" SG_ 1032 L_EVNT_AstSdHorIntFlt 7;
BA_REL_ "GenSigTimeoutTime" BU_SG_REL_ L_ATCU SG_ 1032 L_EVNT_AstSdHorIntFlt 5000;
BA_ "Version" SG_ 1032 L_EVNT_AstSdHorIntFlt "24.05.11";
BA_ "GenSigSendType" SG_ 1032 L_EVNT_DrvSdVertComFlt 4;
BA_ "UserSigValidity" SG_ 1032 L_EVNT_DrvSdVertComFlt 7;
BA_REL_ "GenSigTimeoutTime" BU_SG_REL_ L_ATCU SG_ 1032 L_EVNT_DrvSdVertComFlt 5000;
BA_ "Version" SG_ 1032 L_EVNT_DrvSdVertComFlt "24.05.11";
BA_ "GenSigSendType" SG_ 1032 L_EVNT_AstCntrVertIntFlt 4;
BA_ "UserSigValidity" SG_ 1032 L_EVNT_AstCntrVertIntFlt 7;
BA_REL_ "GenSigTimeoutTime" BU_SG_REL_ L_ATCU SG_ 1032 L_EVNT_AstCntrVertIntFlt 5000;
BA_ "Version" SG_ 1032 L_EVNT_AstCntrVertIntFlt "24.05.11";
BA_ "GenSigSendType" SG_ 1032 L_EVNT_AstCntrHorIntFlt 4;
BA_ "UserSigValidity" SG_ 1032 L_EVNT_AstCntrHorIntFlt 7;
BA_REL_ "GenSigTimeoutTime" BU_SG_REL_ L_ATCU SG_ 1032 L_EVNT_AstCntrHorIntFlt 5000;
BA_ "Version" SG_ 1032 L_EVNT_AstCntrHorIntFlt "24.05.11";
BA_ "GenSigSendType" SG_ 1032 L_EVNT_RrDrvCnslVertIntFlt 4;
BA_ "UserSigValidity" SG_ 1032 L_EVNT_RrDrvCnslVertIntFlt 7;
BA_REL_ "GenSigTimeoutTime" BU_SG_REL_ L_ATCU SG_ 1032 L_EVNT_RrDrvCnslVertIntFlt 5000;
BA_ "Version" SG_ 1032 L_EVNT_RrDrvCnslVertIntFlt "24.05.11";
BA_ "GenSigSendType" SG_ 1032 L_EVNT_RrDrvCnslHorIntFlt 4;
BA_ "UserSigValidity" SG_ 1032 L_EVNT_RrDrvCnslHorIntFlt 7;
BA_REL_ "GenSigTimeoutTime" BU_SG_REL_ L_ATCU SG_ 1032 L_EVNT_RrDrvCnslHorIntFlt 5000;
BA_ "Version" SG_ 1032 L_EVNT_RrDrvCnslHorIntFlt "24.05.11";
BA_ "GenSigSendType" SG_ 1032 L_EVNT_RrAstCnslVertIntFlt 4;
BA_ "UserSigValidity" SG_ 1032 L_EVNT_RrAstCnslVertIntFlt 7;
BA_REL_ "GenSigTimeoutTime" BU_SG_REL_ L_ATCU SG_ 1032 L_EVNT_RrAstCnslVertIntFlt 5000;
BA_ "Version" SG_ 1032 L_EVNT_RrAstCnslVertIntFlt "24.05.11";
BA_ "GenSigSendType" SG_ 1032 L_EVNT_RrAstCnslHorIntFlt 4;
BA_ "UserSigValidity" SG_ 1032 L_EVNT_RrAstCnslHorIntFlt 7;
BA_REL_ "GenSigTimeoutTime" BU_SG_REL_ L_ATCU SG_ 1032 L_EVNT_RrAstCnslHorIntFlt 5000;
BA_ "Version" SG_ 1032 L_EVNT_RrAstCnslHorIntFlt "24.05.11";
BA_ "GenSigSendType" SG_ 1032 L_EVNT_DrvSdVertExtFlt 4;
BA_ "UserSigValidity" SG_ 1032 L_EVNT_DrvSdVertExtFlt 7;
BA_REL_ "GenSigTimeoutTime" BU_SG_REL_ L_ATCU SG_ 1032 L_EVNT_DrvSdVertExtFlt 5000;
BA_ "Version" SG_ 1032 L_EVNT_DrvSdVertExtFlt "24.05.11";
BA_ "GenSigSendType" SG_ 1032 L_EVNT_DrvSdHorExtFlt 4;
BA_ "UserSigValidity" SG_ 1032 L_EVNT_DrvSdHorExtFlt 7;
BA_REL_ "GenSigTimeoutTime" BU_SG_REL_ L_ATCU SG_ 1032 L_EVNT_DrvSdHorExtFlt 5000;
BA_ "Version" SG_ 1032 L_EVNT_DrvSdHorExtFlt "24.05.11";
BA_ "GenSigSendType" SG_ 1032 L_EVNT_DrvCntrVertExtFlt 4;
BA_ "UserSigValidity" SG_ 1032 L_EVNT_DrvCntrVertExtFlt 7;
BA_REL_ "GenSigTimeoutTime" BU_SG_REL_ L_ATCU SG_ 1032 L_EVNT_DrvCntrVertExtFlt 5000;
BA_ "Version" SG_ 1032 L_EVNT_DrvCntrVertExtFlt "24.05.11";
BA_ "GenSigSendType" SG_ 1032 L_EVNT_DrvCntrHorExtFlt 4;
BA_ "UserSigValidity" SG_ 1032 L_EVNT_DrvCntrHorExtFlt 7;
BA_REL_ "GenSigTimeoutTime" BU_SG_REL_ L_ATCU SG_ 1032 L_EVNT_DrvCntrHorExtFlt 5000;
BA_ "Version" SG_ 1032 L_EVNT_DrvCntrHorExtFlt "24.05.11";
BA_ "GenSigSendType" SG_ 1032 L_EVNT_DrvSdHorComFlt 4;
BA_ "UserSigValidity" SG_ 1032 L_EVNT_DrvSdHorComFlt 7;
BA_REL_ "GenSigTimeoutTime" BU_SG_REL_ L_ATCU SG_ 1032 L_EVNT_DrvSdHorComFlt 5000;
BA_ "Version" SG_ 1032 L_EVNT_DrvSdHorComFlt "24.05.11";
BA_ "GenSigSendType" SG_ 1032 L_EVNT_AstSdVertExtFlt 4;
BA_ "UserSigValidity" SG_ 1032 L_EVNT_AstSdVertExtFlt 7;
BA_REL_ "GenSigTimeoutTime" BU_SG_REL_ L_ATCU SG_ 1032 L_EVNT_AstSdVertExtFlt 5000;
BA_ "Version" SG_ 1032 L_EVNT_AstSdVertExtFlt "24.05.11";
BA_ "GenSigSendType" SG_ 1032 L_EVNT_AstSdHorExtFlt 4;
BA_ "UserSigValidity" SG_ 1032 L_EVNT_AstSdHorExtFlt 7;
BA_REL_ "GenSigTimeoutTime" BU_SG_REL_ L_ATCU SG_ 1032 L_EVNT_AstSdHorExtFlt 5000;
BA_ "Version" SG_ 1032 L_EVNT_AstSdHorExtFlt "24.05.11";
BA_ "GenSigSendType" SG_ 1032 L_EVNT_DrvCntrVertComFlt 4;
BA_ "UserSigValidity" SG_ 1032 L_EVNT_DrvCntrVertComFlt 7;
BA_REL_ "GenSigTimeoutTime" BU_SG_REL_ L_ATCU SG_ 1032 L_EVNT_DrvCntrVertComFlt 5000;
BA_ "Version" SG_ 1032 L_EVNT_DrvCntrVertComFlt "24.05.11";
BA_ "GenMsgSendType" BO_ 1033 0;
BA_ "GenMsgCycleTime" BO_ 1033 1000;
BA_ "GenSigSendType" SG_ 1033 L_EVNT_AstCntrVertExtFlt 4;
BA_ "UserSigValidity" SG_ 1033 L_EVNT_AstCntrVertExtFlt 7;
BA_REL_ "GenSigTimeoutTime" BU_SG_REL_ L_ATCU SG_ 1033 L_EVNT_AstCntrVertExtFlt 5000;
BA_ "Version" SG_ 1033 L_EVNT_AstCntrVertExtFlt "24.05.11";
BA_ "GenSigSendType" SG_ 1033 L_EVNT_RrAstCnslHorExtFlt 4;
BA_ "UserSigValidity" SG_ 1033 L_EVNT_RrAstCnslHorExtFlt 7;
BA_REL_ "GenSigTimeoutTime" BU_SG_REL_ L_ATCU SG_ 1033 L_EVNT_RrAstCnslHorExtFlt 5000;
BA_ "Version" SG_ 1033 L_EVNT_RrAstCnslHorExtFlt "24.05.11";
BA_ "GenSigSendType" SG_ 1033 L_EVNT_AstCntrHorExtFlt 4;
BA_ "UserSigValidity" SG_ 1033 L_EVNT_AstCntrHorExtFlt 7;
BA_REL_ "GenSigTimeoutTime" BU_SG_REL_ L_ATCU SG_ 1033 L_EVNT_AstCntrHorExtFlt 5000;
BA_ "Version" SG_ 1033 L_EVNT_AstCntrHorExtFlt "24.05.11";
BA_ "GenSigSendType" SG_ 1033 L_EVNT_RrDrvCnslVertExtFlt 4;
BA_ "UserSigValidity" SG_ 1033 L_EVNT_RrDrvCnslVertExtFlt 7;
BA_REL_ "GenSigTimeoutTime" BU_SG_REL_ L_ATCU SG_ 1033 L_EVNT_RrDrvCnslVertExtFlt 5000;
BA_ "Version" SG_ 1033 L_EVNT_RrDrvCnslVertExtFlt "24.05.11";
BA_ "GenSigSendType" SG_ 1033 L_EVNT_RrDrvCnslHorExtFlt 4;
BA_ "UserSigValidity" SG_ 1033 L_EVNT_RrDrvCnslHorExtFlt 7;
BA_REL_ "GenSigTimeoutTime" BU_SG_REL_ L_ATCU SG_ 1033 L_EVNT_RrDrvCnslHorExtFlt 5000;
BA_ "Version" SG_ 1033 L_EVNT_RrDrvCnslHorExtFlt "24.05.11";
BA_ "Description" SG_ 1033 L_EVNT_ResetOpSta "This signal indicates whether the reset operation has been completed or not";
BA_ "GenSigSendType" SG_ 1033 L_EVNT_ResetOpSta 4;
BA_ "UserSigValidity" SG_ 1033 L_EVNT_ResetOpSta 0;
BA_REL_ "GenSigTimeoutTime" BU_SG_REL_ L_ATCU SG_ 1033 L_EVNT_ResetOpSta 1000;
BA_ "Version" SG_ 1033 L_EVNT_ResetOpSta "24.10.05";
BA_ "GenSigSendType" SG_ 1033 L_EVNT_RrAstCnslVertExtFlt 4;
BA_ "UserSigValidity" SG_ 1033 L_EVNT_RrAstCnslVertExtFlt 7;
BA_REL_ "GenSigTimeoutTime" BU_SG_REL_ L_ATCU SG_ 1033 L_EVNT_RrAstCnslVertExtFlt 5000;
BA_ "Version" SG_ 1033 L_EVNT_RrAstCnslVertExtFlt "24.05.11";
VAL_ 34 L_ATCU_DrTempCDis 0 "Blank Display (Default)" 1 "'LO' Display" 2 "15.0¡É~32.0¡É" 3 "15.0¡É~32.0¡É" 4 "15.0¡É~32.0¡É" 5 "15.0¡É~32.0¡É" 6 "15.0¡É~32.0¡É" 7 "15.0¡É~32.0¡É" 8 "15.0¡É~32.0¡É" 9 "15.0¡É~32.0¡É" 10 "15.0¡É~32.0¡É" 11 "15.0¡É~32.0¡É" 12 "15.0¡É~32.0¡É" 13 "15.0¡É~32.0¡É" 14 "15.0¡É~32.0¡É" 15 "15.0¡É~32.0¡É" 16 "15.0¡É~32.0¡É" 17 "15.0¡É~32.0¡É" 18 "15.0¡É~32.0¡É" 19 "15.0¡É~32.0¡É" 20 "15.0¡É~32.0¡É" 21 "15.0¡É~32.0¡É" 22 "15.0¡É~32.0¡É" 23 "15.0¡É~32.0¡É" 24 "15.0¡É~32.0¡É" 25 "15.0¡É~32.0¡É" 26 "15.0¡É~32.0¡É" 27 "15.0¡É~32.0¡É" 28 "15.0¡É~32.0¡É" 29 "15.0¡É~32.0¡É" 30 "15.0¡É~32.0¡É" 31 "15.0¡É~32.0¡É" 32 "15.0¡É~32.0¡É" 33 "15.0¡É~32.0¡É" 34 "15.0¡É~32.0¡É" 35 "15.0¡É~32.0¡É" 36 "15.0¡É~32.0¡É" 37 "0x25~0xFD:RESERVED" 253 "0x25~0xFD:RESERVED" 254 "'HI' Display" 255 "Error Indicator" ;
VAL_ 34 L_ATCU_DrTempFDis 0 "Blank Display(Default)" 1 "'LO' Display" 2 "58¢µ~92¢µ" 3 "58¢µ~92¢µ" 4 "58¢µ~92¢µ" 5 "58¢µ~92¢µ" 6 "58¢µ~92¢µ" 7 "58¢µ~92¢µ" 8 "58¢µ~92¢µ" 9 "58¢µ~92¢µ" 10 "58¢µ~92¢µ" 11 "58¢µ~92¢µ" 12 "58¢µ~92¢µ" 13 "58¢µ~92¢µ" 14 "58¢µ~92¢µ" 15 "58¢µ~92¢µ" 16 "58¢µ~92¢µ" 17 "58¢µ~92¢µ" 18 "58¢µ~92¢µ" 19 "58¢µ~92¢µ" 20 "58¢µ~92¢µ" 21 "58¢µ~92¢µ" 22 "58¢µ~92¢µ" 23 "58¢µ~92¢µ" 24 "58¢µ~92¢µ" 25 "58¢µ~92¢µ" 26 "58¢µ~92¢µ" 27 "58¢µ~92¢µ" 28 "58¢µ~92¢µ" 29 "58¢µ~92¢µ" 30 "58¢µ~92¢µ" 31 "58¢µ~92¢µ" 32 "58¢µ~92¢µ" 33 "58¢µ~92¢µ" 34 "58¢µ~92¢µ" 35 "58¢µ~92¢µ" 36 "58¢µ~92¢µ" 37 "0x25~0xFD:RESERVED" 253 "0x25~0xFD:RESERVED" 254 "'HI' Display" 255 "Error Indicator" ;
VAL_ 34 L_ATCU_PassTempFDis 0 "Blank Display(Default)" 1 "'LO' Display" 2 "58¢µ~92¢µ" 3 "58¢µ~92¢µ" 4 "58¢µ~92¢µ" 5 "58¢µ~92¢µ" 6 "58¢µ~92¢µ" 7 "58¢µ~92¢µ" 8 "58¢µ~92¢µ" 9 "58¢µ~92¢µ" 10 "58¢µ~92¢µ" 11 "58¢µ~92¢µ" 12 "58¢µ~92¢µ" 13 "58¢µ~92¢µ" 14 "58¢µ~92¢µ" 15 "58¢µ~92¢µ" 16 "58¢µ~92¢µ" 17 "58¢µ~92¢µ" 18 "58¢µ~92¢µ" 19 "58¢µ~92¢µ" 20 "58¢µ~92¢µ" 21 "58¢µ~92¢µ" 22 "58¢µ~92¢µ" 23 "58¢µ~92¢µ" 24 "58¢µ~92¢µ" 25 "58¢µ~92¢µ" 26 "58¢µ~92¢µ" 27 "58¢µ~92¢µ" 28 "58¢µ~92¢µ" 29 "58¢µ~92¢µ" 30 "58¢µ~92¢µ" 31 "58¢µ~92¢µ" 32 "58¢µ~92¢µ" 33 "58¢µ~92¢µ" 34 "58¢µ~92¢µ" 35 "58¢µ~92¢µ" 36 "58¢µ~92¢µ" 37 "0x25~0xFD:RESERVED" 253 "0x25~0xFD:RESERVED" 254 "'HI' Display" 255 "Error Indicator" ;
VAL_ 34 L_ATCU_FrDrModDis 0 "Off(Blank Display, Vent mode not Display ex) Auto(Default)" 1 "VENT" 2 "B_L" 3 "FLOOR" 4 "MIX (7 MODE DEF FLOOR)" 5 "DEF (MAX DEF)" 6 "AUTO DEFOG" 7 "7 MODE DEF VENT" 8 "MODE AUTO" 9 "7 MODE DEF VENT FLOOR" 10 "7 MODE DEF" 11 "DEF VENT (Arrow)" 12 "DEF FLOOR (Arrow)" 13 "DEF VENT FLOOR (Arrow)" 14 "DEF (Arrow)" 15 "Error Indicator" ;
VAL_ 34 L_ATCU_FrPassModDis 0 "Off(Blank Display, Vent mode not Display ex) Auto(Default)" 1 "VENT" 2 "B_L" 3 "FLOOR" 4 "MIX (7 MODE DEF FLOOR)" 5 "DEF (MAX DEF)" 6 "AUTO DEFOG" 7 "7 MODE DEF VENT" 8 "MODE AUTO" 9 "7 MODE DEF VENT FLOOR" 10 "7 MODE DEF" 11 "DEF VENT (Arrow)" 12 "DEF FLOOR (Arrow)" 13 "DEF VENT FLOOR (Arrow)" 14 "DEF (Arrow)" 15 "Error Indicator" ;
VAL_ 34 L_ATCU_FrDrBlwDis 0 "OFF(System Off)" 1 "Blank Display(No Blower level display, ex)Auto" 2 "1 Level" 3 "2 Level" 4 "3 Level" 5 "4 Level" 6 "5 Level" 7 "6 Level" 8 "7 Level" 9 "8 Level" 10 "Not used" 11 "Not used" 12 "Not used" 13 "Not used" 14 "Not used" 15 "Error Indicator" ;
VAL_ 34 L_ATCU_FrPassBlwDis 0 "OFF(System Off)" 1 "Blank Display(No Blower level display, ex)Auto" 2 "1 Level" 3 "2 Level" 4 "3 Level" 5 "4 Level" 6 "5 Level" 7 "6 Level" 8 "7 Level" 9 "8 Level" 10 "Not used" 11 "Not used" 12 "Not used" 13 "Not used" 14 "Not used" 15 "Error Indicator" ;
VAL_ 34 L_ATCU_DrAutoDis 0 "DrAUTO Off" 1 "DrAUTO On" 2 "Not used" 3 "Error Indicator" ;
VAL_ 34 L_ATCU_PassAutoDis 0 "PsAUTO Off" 1 "PsAUTO On" 2 "Not used" 3 "Error Indicator" ;
VAL_ 34 L_ATCU_DrMultiAutoBlwDis 0 "MultiAutoBlr Display Off" 1 "Multi Auto Blower Low" 2 "Multi Auto Blower Mid" 3 "Multi Auto Blower High" ;
VAL_ 34 L_ATCU_PassMultiAutoBlwDis 0 "MultiAutoBlr Display Off" 1 "Multi Auto Blower Low" 2 "Multi Auto Blower Mid" 3 "Multi Auto Blower High" ;
VAL_ 34 L_ATCU_AcDis 0 "A/C Off" 1 "A/C ON" 2 "Not used" 3 "Error Indicator" ;
VAL_ 34 L_ATCU_IntakeDis 0 "Default(Fresh off & Rec off)" 1 "REC (Fresh off)" 2 "FRE (REC off)" 3 "Error Indicator" ;
VAL_ 34 L_ATCU_SyncDis 0 "SYNC Off" 1 "SYNC On" 2 "Not used" 3 "Error Indicator" ;
VAL_ 34 L_ATCU_FrDefDis 0 "Front Def Off" 1 "Front Def On" 2 "Not used" 3 "Error Indicator" ;
VAL_ 34 L_ATCU_PassTempCDis 0 "Blank Display (Default)" 1 "'LO' Display" 2 "15.0¡É~32.0¡É" 3 "15.0¡É~32.0¡É" 4 "15.0¡É~32.0¡É" 5 "15.0¡É~32.0¡É" 6 "15.0¡É~32.0¡É" 7 "15.0¡É~32.0¡É" 8 "15.0¡É~32.0¡É" 9 "15.0¡É~32.0¡É" 10 "15.0¡É~32.0¡É" 11 "15.0¡É~32.0¡É" 12 "15.0¡É~32.0¡É" 13 "15.0¡É~32.0¡É" 14 "15.0¡É~32.0¡É" 15 "15.0¡É~32.0¡É" 16 "15.0¡É~32.0¡É" 17 "15.0¡É~32.0¡É" 18 "15.0¡É~32.0¡É" 19 "15.0¡É~32.0¡É" 20 "15.0¡É~32.0¡É" 21 "15.0¡É~32.0¡É" 22 "15.0¡É~32.0¡É" 23 "15.0¡É~32.0¡É" 24 "15.0¡É~32.0¡É" 25 "15.0¡É~32.0¡É" 26 "15.0¡É~32.0¡É" 27 "15.0¡É~32.0¡É" 28 "15.0¡É~32.0¡É" 29 "15.0¡É~32.0¡É" 30 "15.0¡É~32.0¡É" 31 "15.0¡É~32.0¡É" 32 "15.0¡É~32.0¡É" 33 "15.0¡É~32.0¡É" 34 "15.0¡É~32.0¡É" 35 "15.0¡É~32.0¡É" 36 "15.0¡É~32.0¡É" 37 "0x25~0xFD:RESERVED" 253 "0x25~0xFD:RESERVED" 254 "'HI' Display" 255 "Error Indicator" ;
VAL_ 35 L_ATCU_DrOnlyDis 0 "Initial (Dual Temp Display)" 1 "Driver Only Status (Only Display Driver Temp)" 2 "Not used" 3 "Error Indicator" ;
VAL_ 35 L_ATCU_SmrtVntDis 0 "Off" 1 "Smart Ventilation" 2 "Smart CO2" 3 "Error Indicator" ;
VAL_ 35 L_ATCU_FrWndShldHtInd 0 "Off" 1 "On" 2 "RESERVED" ;
VAL_ 35 L_ATCU_IncarMtrOnReq 0 "OFF" 1 "ON" ;
VAL_ 35 L_ATCU_LanguageInfo 0 "Off" 1 "Korea" 2 "English(US)" 3 "English(UK)" 4 "Simplified chinese" 5 "Traditional chinese" 6 "French(EU)" 7 "Spanish(EU)" 8 "Arabic" 9 "Czech" 10 "Danish" 11 "German" 12 "Italian" 13 "Dutch" 14 "Polish" 15 "Portuguese" 16 "Russain" 17 "Slovak" 18 "Swedish" 19 "Turkish" 20 "French(US)" 21 "Spanish(US)" 22 "English(India)" 23 "Norwegian" 24 "Finnish" 25 "Indonesian" 26 "Brazilian Portuguese" 27 "Malay" 28 "Hungarian" 29 "English (Australia)" 30 "Japanese" 31 "Hindi" 32 "Hebrew" 33 "Greek" 34 "Ukrainian" 35 "Slovenian" 36 "Bulgarian" 37 "Croatian" 38 "Romanian" 39 "Bengali" 40 "Marathi" 41 "Telugu" 42 "Tamil" 43 "Gujarati" 44 "Kannada" 45 "Odia" 46 "Malayalam" 47 "Punjabi" 48 "Thai" 49 "Tagalog" 50 "Vietnamese" 51 "0x33~0xFE:RESERVED" 254 "0x33~0xFE:RESERVED" 255 "Invalid" ;
VAL_ 35 L_ATCU_RrDefInd 0 "OFF" 1 "ON" ;
VAL_ 35 L_ATCU_AfterBlowDisplay 0 "Default" 1 "AfterBlower Waiting" 2 "AfterBlower Operating(Symbol Off)" 3 "AfterBlower Operating(Symbol On)" ;
VAL_ 35 L_ATCU_SchdldVentDisplay 0 "Default" 1 "SchdldVent Waiting" 2 "SchdldVent Operating(Symbol Off)" 3 "SchdldVent Operating(Symbol On)" ;
VAL_ 35 L_ATCU_FLStHeatSwHInd 0 "OFF" 1 "ON" ;
VAL_ 35 L_ATCU_FLStHeatSwMInd 0 "OFF" 1 "ON" ;
VAL_ 35 L_ATCU_ADSBlinkDis 0 "AutoDefogBlink Non Request" 1 "AutoDefogBlink Request" 2 "Not used" 3 "Error Indicator" ;
VAL_ 35 L_ATCU_FLStHeatSwLInd 0 "OFF" 1 "ON" ;
VAL_ 35 L_ATCU_FLStVntSwHInd 0 "OFF" 1 "ON" ;
VAL_ 35 L_ATCU_FLStVntSwMInd 0 "OFF" 1 "ON" ;
VAL_ 35 L_ATCU_FLStVntSwLInd 0 "OFF" 1 "ON" ;
VAL_ 35 L_ATCU_FRStHeatSwHInd 0 "OFF" 1 "ON" ;
VAL_ 35 L_ATCU_FRStHeatSwMInd 0 "OFF" 1 "ON" ;
VAL_ 35 L_ATCU_FRStHeatSwLInd 0 "OFF" 1 "ON" ;
VAL_ 35 L_ATCU_FRStVntSwHInd 0 "OFF" 1 "ON" ;
VAL_ 35 L_ATCU_FRStVntSwMInd 0 "OFF" 1 "ON" ;
VAL_ 35 L_ATCU_FRStVntSwLInd 0 "OFF" 1 "ON" ;
VAL_ 35 L_ATCU_StrWhlHeatInd 0 "OFF" 1 "Step1" 2 "Step2" 3 "RESERVED" ;
VAL_ 35 L_ATCU_RhstaLvlSta 0 "RESERVED" 1 "Step1" 2 "Step2" 3 "Step 3" 4 "Step 4" 5 "Step5" 6 "Step 6" 7 "Step 7" 8 "Step8" 9 "Step 9" 10 "Step 10" 11 "Step11" 12 "Step 12" 13 "Step 13" 14 "Step14" 15 "Step 15" 16 "Step 16" 17 "Step17" 18 "Step 18" 19 "Step 19" 20 "Step 20 (Reset Value)" 21 "Step 21(Detent)" ;
VAL_ 35 L_ATCU_IntTailOnOff 0 "OFF" 1 "ON" ;
VAL_ 35 L_ATCU_AutoLightSta 0 "Off (not Night)" 1 "Night" ;
VAL_ 35 L_ATCU_FrBckLightSta 0 "OFF" 1 "ON" ;
VAL_ 35 L_ATCU_DisplayTheme 0 "Default" 1 "White Theme" 2 "Black Theme" 3 "Invalid" ;
VAL_ 35 L_ATCU_GUIBlankDis 0 "Default" 1 "GUI Blank Display" ;
VAL_ 35 L_ATCU_HptIntnstySet 0 "Default" 1 "Haptic OFF" 2 "Haptic Intensity Level 1" 3 "Haptic Intensity Level 2" 4 "Haptic Intensity Level 3" 5 "Haptic Intensity Level 4" 6 "Haptic Intensity Level 5" 7 "RESERVED" 8 "RESERVED" 9 "RESERVED" 10 "RESERVED" 11 "RESERVED" 12 "RESERVED" 13 "RESERVED" 14 "RESERVED" 15 "Invalid" ;
VAL_ 35 L_ATCU_TlltLmpDis 0 "ON Lamp off OFF Lamp off" 1 "ON Lamp off OFF Lamp on" 2 "ON Lamp on Off Lamp off" 3 "ON Lamp on OFF Lamp on" 4 "RESERVED" 5 "RESERVED" 6 "RESERVED" 7 "Error Indicator" ;
VAL_ 35 L_ATCU_AvTailOnOff 0 "OFF" 1 "ON" ;
VAL_ 35 L_ATCU_SchdldClimateDisplay 0 "Reservation Not Set" 1 "Reservation Set" 2 "Not used" 3 "Error Indicator" ;
VAL_ 35 L_ATCU_AirClnDis 0 "AirClean Off" 1 "AirClean On" 2 "Not used" 3 "Error Indicator" ;
VAL_ 35 L_ATCU_CO2WrngDis 0 "Co2 Warning Off" 1 "Co2 Warning On" 2 "Not used" 3 "Error Indicator" ;
VAL_ 273 L_ATCU_FHPTCOpPrmssnSta 0 "Not Permiited" 1 "Permitted" ;
VAL_ 273 L_ATCU_FHPTCPassTrgtDty 0 "0x0x0~0xC8:Duty" 200 "0x0x0~0xC8:Duty" 201 "RESERVED" 202 "RESERVED" 203 "RESERVED" 204 "RESERVED" 205 "RESERVED" 206 "RESERVED" 207 "RESERVED" 208 "RESERVED" 209 "RESERVED" 210 "RESERVED" 211 "RESERVED" 212 "RESERVED" 213 "RESERVED" 214 "RESERVED" 215 "RESERVED" 216 "RESERVED" 217 "RESERVED" 218 "RESERVED" 219 "RESERVED" 220 "RESERVED" 221 "RESERVED" 222 "RESERVED" 223 "RESERVED" 224 "RESERVED" 225 "RESERVED" 226 "RESERVED" 227 "RESERVED" 228 "RESERVED" 229 "RESERVED" 230 "RESERVED" 231 "RESERVED" 232 "RESERVED" 233 "RESERVED" 234 "RESERVED" 235 "RESERVED" 236 "RESERVED" 237 "RESERVED" 238 "RESERVED" 239 "RESERVED" 240 "RESERVED" 241 "RESERVED" 242 "RESERVED" 243 "RESERVED" 244 "RESERVED" 245 "RESERVED" 246 "RESERVED" 247 "RESERVED" 248 "RESERVED" 249 "RESERVED" 250 "RESERVED" 251 "RESERVED" 252 "RESERVED" 253 "RESERVED" 254 "RESERVED" 255 "ERROR" ;
VAL_ 273 L_ATCU_FHPTCDischrgReq 0 "Non-Request" 1 "Request" ;
VAL_ 273 L_ATCU_FltMsgTmOutFHPTC1 0 "Normal" 1 "Message Timeout" ;
VAL_ 273 L_ATCU_FltMsgTmOutFHPTC2 0 "Normal" 1 "Message Timeout" ;
VAL_ 273 L_ATCU_FltMsgTmOutFHPTC3 0 "Normal" 1 "Message Timeout" ;
VAL_ 273 L_ATCU_FltMsgTmOutFHPTC4 0 "Normal" 1 "Message Timeout" ;
VAL_ 273 L_ATCU_FrBlwLvl 0 "OFF" 1 "0 level" 2 "1 level" 3 "2 level" 4 "3 level" 5 "4 level" 6 "5 level" 7 "6 level" 8 "7 evel" 9 "8 level" 10 "RESERVED" 11 "RESERVED" 12 "RESERVED" 13 "RESERVED" 14 "RESERVED" 15 "Error Indicator" ;
VAL_ 273 L_ATCU_FrBlwLvlSigVaildSta 0 "Invaild (Blower Level Info Not supported)" 1 "Vaild (Blower Level Info Supported) (Initial Value:0H)" ;
VAL_ 273 L_ATCU_DrvrSdTyp 0 "LHD" 1 "RHD" ;
VAL_ 273 L_ATCU_FrBlwFltSta 0 "Normal" 1 "Blower Fault" ;
VAL_ 273 L_ATCU_PassBlwLvl 0 "OFF(Default)" 1 "0 Level" 2 "1 Level" 3 "2 Level" 4 "3 Level" 5 "4 Level" 6 "5 Level" 7 "6 Level" 8 "7 Level" 9 "8 Level" 10 "RESERVED" 11 "RESERVED" 12 "RESERVED" 13 "RESERVED" 14 "RESERVED" 15 "Error Indicator" ;
VAL_ 273 L_ATCU_FHPTCDrTrgtDty 0 "0x0x0~0xC8:Duty" 200 "0x0x0~0xC8:Duty" 201 "RESERVED" 202 "RESERVED" 203 "RESERVED" 204 "RESERVED" 205 "RESERVED" 206 "RESERVED" 207 "RESERVED" 208 "RESERVED" 209 "RESERVED" 210 "RESERVED" 211 "RESERVED" 212 "RESERVED" 213 "RESERVED" 214 "RESERVED" 215 "RESERVED" 216 "RESERVED" 217 "RESERVED" 218 "RESERVED" 219 "RESERVED" 220 "RESERVED" 221 "RESERVED" 222 "RESERVED" 223 "RESERVED" 224 "RESERVED" 225 "RESERVED" 226 "RESERVED" 227 "RESERVED" 228 "RESERVED" 229 "RESERVED" 230 "RESERVED" 231 "RESERVED" 232 "RESERVED" 233 "RESERVED" 234 "RESERVED" 235 "RESERVED" 236 "RESERVED" 237 "RESERVED" 238 "RESERVED" 239 "RESERVED" 240 "RESERVED" 241 "RESERVED" 242 "RESERVED" 243 "RESERVED" 244 "RESERVED" 245 "RESERVED" 246 "RESERVED" 247 "RESERVED" 248 "RESERVED" 249 "RESERVED" 250 "RESERVED" 251 "RESERVED" 252 "RESERVED" 253 "RESERVED" 254 "RESERVED" 255 "ERROR" ;
VAL_ 274 L_ATCU_RHPTCOpPrmssnSta 0 "Operation is not allowed" 1 "Operation is allowed" ;
VAL_ 274 L_ATCU_RHPTCZone2TrgtDty 0 "0x0x0~0xC8:Duty" 200 "0x0x0~0xC8:Duty" 201 "RESERVED" 202 "RESERVED" 203 "RESERVED" 204 "RESERVED" 205 "RESERVED" 206 "RESERVED" 207 "RESERVED" 208 "RESERVED" 209 "RESERVED" 210 "RESERVED" 211 "RESERVED" 212 "RESERVED" 213 "RESERVED" 214 "RESERVED" 215 "RESERVED" 216 "RESERVED" 217 "RESERVED" 218 "RESERVED" 219 "RESERVED" 220 "RESERVED" 221 "RESERVED" 222 "RESERVED" 223 "RESERVED" 224 "RESERVED" 225 "RESERVED" 226 "RESERVED" 227 "RESERVED" 228 "RESERVED" 229 "RESERVED" 230 "RESERVED" 231 "RESERVED" 232 "RESERVED" 233 "RESERVED" 234 "RESERVED" 235 "RESERVED" 236 "RESERVED" 237 "RESERVED" 238 "RESERVED" 239 "RESERVED" 240 "RESERVED" 241 "RESERVED" 242 "RESERVED" 243 "RESERVED" 244 "RESERVED" 245 "RESERVED" 246 "RESERVED" 247 "RESERVED" 248 "RESERVED" 249 "RESERVED" 250 "RESERVED" 251 "RESERVED" 252 "RESERVED" 253 "RESERVED" 254 "RESERVED" 255 "ERROR" ;
VAL_ 274 L_ATCU_RHPTCDischrgReq 0 "Non-Request" 1 "Request" ;
VAL_ 274 L_ATCU_FltMsgTmOutRHPTC1 0 "Normal" 1 "Message Timeout" ;
VAL_ 274 L_ATCU_FltMsgTmOutRHPTC2 0 "Normal" 1 "Message Timeout" ;
VAL_ 274 L_ATCU_FltMsgTmOutRHPTC3 0 "Normal" 1 "Message Timeout" ;
VAL_ 274 L_ATCU_FltMsgTmOutRHPTC4 0 "Normal" 1 "Message Timeout" ;
VAL_ 274 L_ATCU_RrBlwLvl 0 "OFF" 1 "0 level" 2 "1 level" 3 "2 level" 4 "3 level" 5 "4 level" 6 "5 level" 7 "6 level" 8 "7 evel" 9 "8 level" 10 "RESERVED" 11 "RESERVED" 12 "RESERVED" 13 "RESERVED" 14 "RESERVED" 15 "Error Indicator" ;
VAL_ 274 L_ATCU_RrBlwLvlSigVaildSta 0 "Invaild (Blower Level Info Not supported)" 1 "Vaild (Blower Level Info Supported) (Initial Value:0H)" ;
VAL_ 274 L_ATCU_RHPTCZone1TrgtDty 0 "0x0x0~0xC8:Duty" 200 "0x0x0~0xC8:Duty" 201 "RESERVED" 202 "RESERVED" 203 "RESERVED" 204 "RESERVED" 205 "RESERVED" 206 "RESERVED" 207 "RESERVED" 208 "RESERVED" 209 "RESERVED" 210 "RESERVED" 211 "RESERVED" 212 "RESERVED" 213 "RESERVED" 214 "RESERVED" 215 "RESERVED" 216 "RESERVED" 217 "RESERVED" 218 "RESERVED" 219 "RESERVED" 220 "RESERVED" 221 "RESERVED" 222 "RESERVED" 223 "RESERVED" 224 "RESERVED" 225 "RESERVED" 226 "RESERVED" 227 "RESERVED" 228 "RESERVED" 229 "RESERVED" 230 "RESERVED" 231 "RESERVED" 232 "RESERVED" 233 "RESERVED" 234 "RESERVED" 235 "RESERVED" 236 "RESERVED" 237 "RESERVED" 238 "RESERVED" 239 "RESERVED" 240 "RESERVED" 241 "RESERVED" 242 "RESERVED" 243 "RESERVED" 244 "RESERVED" 245 "RESERVED" 246 "RESERVED" 247 "RESERVED" 248 "RESERVED" 249 "RESERVED" 250 "RESERVED" 251 "RESERVED" 252 "RESERVED" 253 "RESERVED" 254 "RESERVED" 255 "ERROR" ;
VAL_ 274 L_ATCU_RrBlwFltSta 0 "Normal" 1 "Blower Fault" ;
VAL_ 277 L_ATCU_FHPTC2ndDrTrgtDty 0 "0x0x0~0xC8:Duty" 200 "0x0x0~0xC8:Duty" 201 "RESERVED" 202 "RESERVED" 203 "RESERVED" 204 "RESERVED" 205 "RESERVED" 206 "RESERVED" 207 "RESERVED" 208 "RESERVED" 209 "RESERVED" 210 "RESERVED" 211 "RESERVED" 212 "RESERVED" 213 "RESERVED" 214 "RESERVED" 215 "RESERVED" 216 "RESERVED" 217 "RESERVED" 218 "RESERVED" 219 "RESERVED" 220 "RESERVED" 221 "RESERVED" 222 "RESERVED" 223 "RESERVED" 224 "RESERVED" 225 "RESERVED" 226 "RESERVED" 227 "RESERVED" 228 "RESERVED" 229 "RESERVED" 230 "RESERVED" 231 "RESERVED" 232 "RESERVED" 233 "RESERVED" 234 "RESERVED" 235 "RESERVED" 236 "RESERVED" 237 "RESERVED" 238 "RESERVED" 239 "RESERVED" 240 "RESERVED" 241 "RESERVED" 242 "RESERVED" 243 "RESERVED" 244 "RESERVED" 245 "RESERVED" 246 "RESERVED" 247 "RESERVED" 248 "RESERVED" 249 "RESERVED" 250 "RESERVED" 251 "RESERVED" 252 "RESERVED" 253 "RESERVED" 254 "RESERVED" 255 "ERROR" ;
VAL_ 277 L_ATCU_FltMsgTmOutFHPTC5 0 "Normal" 1 "Message Timeout" ;
VAL_ 277 L_ATCU_FltMsgTmOutFHPTC6 0 "Normal" 1 "Message Timeout" ;
VAL_ 277 L_ATCU_FltMsgTmOutFHPTC7 0 "Normal" 1 "Message Timeout" ;
VAL_ 277 L_ATCU_FltMsgTmOutFHPTC8 0 "Normal" 1 "Message Timeout" ;
VAL_ 277 L_ATCU_2ndDrBlwLvl 0 "OFF" 1 "0 level" 2 "1 level" 3 "2 level" 4 "3 level" 5 "4 level" 6 "5 level" 7 "6 level" 8 "7 evel" 9 "8 level" 10 "RESERVED" 11 "RESERVED" 12 "RESERVED" 13 "RESERVED" 14 "RESERVED" 15 "Error Indicator" ;
VAL_ 277 L_ATCU_2ndPsBlwLvl 0 "OFF" 1 "0 level" 2 "1 level" 3 "2 level" 4 "3 level" 5 "4 level" 6 "5 level" 7 "6 level" 8 "7 evel" 9 "8 level" 10 "RESERVED" 11 "RESERVED" 12 "RESERVED" 13 "RESERVED" 14 "RESERVED" 15 "Error Indicator" ;
VAL_ 277 L_ATCU_2ndBlwLvlSigVaildSta 0 "Invaild (Blower Level Info Not supported)" 1 "Vaild (Blower Level Info Supported) (Initial Value:0H)" ;
VAL_ 277 L_ATCU_2ndBlwFltSta 0 "Normal" 1 "Blower Fault" ;
VAL_ 277 L_ATCU_FHPTC2ndPsTrgtDty 0 "0x0x0~0xC8:Duty" 200 "0x0x0~0xC8:Duty" 201 "RESERVED" 202 "RESERVED" 203 "RESERVED" 204 "RESERVED" 205 "RESERVED" 206 "RESERVED" 207 "RESERVED" 208 "RESERVED" 209 "RESERVED" 210 "RESERVED" 211 "RESERVED" 212 "RESERVED" 213 "RESERVED" 214 "RESERVED" 215 "RESERVED" 216 "RESERVED" 217 "RESERVED" 218 "RESERVED" 219 "RESERVED" 220 "RESERVED" 221 "RESERVED" 222 "RESERVED" 223 "RESERVED" 224 "RESERVED" 225 "RESERVED" 226 "RESERVED" 227 "RESERVED" 228 "RESERVED" 229 "RESERVED" 230 "RESERVED" 231 "RESERVED" 232 "RESERVED" 233 "RESERVED" 234 "RESERVED" 235 "RESERVED" 236 "RESERVED" 237 "RESERVED" 238 "RESERVED" 239 "RESERVED" 240 "RESERVED" 241 "RESERVED" 242 "RESERVED" 243 "RESERVED" 244 "RESERVED" 245 "RESERVED" 246 "RESERVED" 247 "RESERVED" 248 "RESERVED" 249 "RESERVED" 250 "RESERVED" 251 "RESERVED" 252 "RESERVED" 253 "RESERVED" 254 "RESERVED" 255 "ERROR" ;
VAL_ 281 L_ATCU_HU_FrDrEVntSidePt_X 0 "Default" 1 "0x001~0x780:PHY=HEX*1 + 0" 1920 "0x001~0x780:PHY=HEX*1 + 0" 1921 "0x781~0x7FE:RESERVED" 2046 "0x781~0x7FE:RESERVED" 2047 "Invalid" ;
VAL_ 281 L_ATCU_HU_FrDrEVntSidePt_Y 0 "Default" 1 "0x001~0x780:PHY=HEX*1 + 0" 1920 "0x001~0x780:PHY=HEX*1 + 0" 1921 "0x781~0x7FE:RESERVED" 2046 "0x781~0x7FE:RESERVED" 2047 "Invalid" ;
VAL_ 281 L_ATCU_HU_FrDrEVntCtrPt_X 0 "Default" 1 "0x001~0x780:PHY=HEX*1 + 0" 1920 "0x001~0x780:PHY=HEX*1 + 0" 1921 "0x781~0x7FE:RESERVED" 2046 "0x781~0x7FE:RESERVED" 2047 "Invalid" ;
VAL_ 281 L_ATCU_HU_FrDrEVntCtrPt_Y 0 "Default" 1 "0x001~0x780:PHY=HEX*1 + 0" 1920 "0x001~0x780:PHY=HEX*1 + 0" 1921 "0x781~0x7FE:RESERVED" 2046 "0x781~0x7FE:RESERVED" 2047 "Invalid" ;
VAL_ 305 L_ATCU_HU_FrPsEVntSidePt_X 0 "Default" 1 "0x001~0x780:PHY=HEX*1 + 0" 1920 "0x001~0x780:PHY=HEX*1 + 0" 1921 "0x781~0x7FE:RESERVED" 2046 "0x781~0x7FE:RESERVED" 2047 "Invalid" ;
VAL_ 305 L_ATCU_HU_FrPsEVntSidePt_Y 0 "Default" 1 "0x001~0x780:PHY=HEX*1 + 0" 1920 "0x001~0x780:PHY=HEX*1 + 0" 1921 "0x781~0x7FE:RESERVED" 2046 "0x781~0x7FE:RESERVED" 2047 "Invalid" ;
VAL_ 305 L_ATCU_HU_FrPsEVntCtrPt_X 0 "Default" 1 "0x001~0x780:PHY=HEX*1 + 0" 1920 "0x001~0x780:PHY=HEX*1 + 0" 1921 "0x781~0x7FE:RESERVED" 2046 "0x781~0x7FE:RESERVED" 2047 "Invalid" ;
VAL_ 305 L_ATCU_HU_FrPsEVntCtrPt_Y 0 "Default" 1 "0x001~0x780:PHY=HEX*1 + 0" 1920 "0x001~0x780:PHY=HEX*1 + 0" 1921 "0x781~0x7FE:RESERVED" 2046 "0x781~0x7FE:RESERVED" 2047 "Invalid" ;
VAL_ 306 L_ATCU_HU_RrDrEVntConsPt_X 0 "Default" 1 "0x001~0x780:PHY=HEX*1 + 0" 1920 "0x001~0x780:PHY=HEX*1 + 0" 1921 "0x781~0x7FE:RESERVED" 2046 "0x781~0x7FE:RESERVED" 2047 "Invalid" ;
VAL_ 306 L_ATCU_HU_RrDrEVntConsPt_Y 0 "Default" 1 "0x001~0x780:PHY=HEX*1 + 0" 1920 "0x001~0x780:PHY=HEX*1 + 0" 1921 "0x781~0x7FE:RESERVED" 2046 "0x781~0x7FE:RESERVED" 2047 "Invalid" ;
VAL_ 306 L_ATCU_HU_RrPsEVntConsPt_X 0 "Default" 1 "0x001~0x780:PHY=HEX*1 + 0" 1920 "0x001~0x780:PHY=HEX*1 + 0" 1921 "0x781~0x7FE:RESERVED" 2046 "0x781~0x7FE:RESERVED" 2047 "Invalid" ;
VAL_ 306 L_ATCU_HU_RrPsEVntConsPt_Y 0 "Default" 1 "0x001~0x780:PHY=HEX*1 + 0" 1920 "0x001~0x780:PHY=HEX*1 + 0" 1921 "0x781~0x7FE:RESERVED" 2046 "0x781~0x7FE:RESERVED" 2047 "Invalid" ;
VAL_ 306 L_ATCU_HU_RrDrEVntConsOpnCls 0 "Default" 1 "OPEN" 2 "CLOSE" 3 "Invalid" ;
VAL_ 306 L_ATCU_HU_RrPsEVntConsOpnCls 0 "Default" 1 "OPEN" 2 "CLOSE" 3 "Invalid" ;
VAL_ 306 L_ATCU_HU_RrDrEVntModeSet 0 "Default" 1 "FOCUS Mode" 2 "SPREAD Mode" 3 "CYCLE Mode" 4 "Manual Mode" 5 "OFF" 6 "RESERVED" 7 "RESERVED" 8 "RESERVED" 9 "RESERVED" 10 "RESERVED" 11 "RESERVED" 12 "RESERVED" 13 "RESERVED" 14 "RESERVED" 15 "Invalid" ;
VAL_ 306 L_ATCU_HU_RrPsEVntModeSet 0 "Default" 1 "FOCUS Mode" 2 "SPREAD Mode" 3 "CYCLE Mode" 4 "Manual Mode" 5 "OFF" 6 "RESERVED" 7 "RESERVED" 8 "RESERVED" 9 "RESERVED" 10 "RESERVED" 11 "RESERVED" 12 "RESERVED" 13 "RESERVED" 14 "RESERVED" 15 "Invalid" ;
VAL_ 304 L_ATCU_CTS_RrDrEVntConsBdryUp_X 0 "Default" 1 "0x01~0xC0:PHY=HEX*10 + 0" 192 "0x01~0xC0:PHY=HEX*10 + 0" 193 "RESERVED" 194 "RESERVED" 195 "RESERVED" 196 "RESERVED" 197 "RESERVED" 198 "RESERVED" 199 "RESERVED" 200 "RESERVED" 201 "RESERVED" 202 "RESERVED" 203 "RESERVED" 204 "RESERVED" 205 "RESERVED" 206 "RESERVED" 207 "RESERVED" 208 "RESERVED" 209 "RESERVED" 210 "RESERVED" 211 "RESERVED" 212 "RESERVED" 213 "RESERVED" 214 "RESERVED" 215 "RESERVED" 216 "RESERVED" 217 "RESERVED" 218 "RESERVED" 219 "RESERVED" 220 "RESERVED" 221 "RESERVED" 222 "RESERVED" 223 "RESERVED" 224 "RESERVED" 225 "RESERVED" 226 "RESERVED" 227 "RESERVED" 228 "RESERVED" 229 "RESERVED" 230 "RESERVED" 231 "RESERVED" 232 "RESERVED" 233 "RESERVED" 234 "RESERVED" 235 "RESERVED" 236 "RESERVED" 237 "RESERVED" 238 "RESERVED" 239 "RESERVED" 240 "RESERVED" 241 "RESERVED" 242 "RESERVED" 243 "RESERVED" 244 "RESERVED" 245 "RESERVED" 246 "RESERVED" 247 "RESERVED" 248 "RESERVED" 249 "RESERVED" 250 "RESERVED" 251 "RESERVED" 252 "RESERVED" 253 "RESERVED" 254 "RESERVED" 255 "Invalid" ;
VAL_ 304 L_ATCU_CTS_RrDrEVntConsBdryLo_X 0 "Default" 1 "0x01~0xC0:PHY=HEX*10 + 0" 192 "0x01~0xC0:PHY=HEX*10 + 0" 193 "RESERVED" 194 "RESERVED" 195 "RESERVED" 196 "RESERVED" 197 "RESERVED" 198 "RESERVED" 199 "RESERVED" 200 "RESERVED" 201 "RESERVED" 202 "RESERVED" 203 "RESERVED" 204 "RESERVED" 205 "RESERVED" 206 "RESERVED" 207 "RESERVED" 208 "RESERVED" 209 "RESERVED" 210 "RESERVED" 211 "RESERVED" 212 "RESERVED" 213 "RESERVED" 214 "RESERVED" 215 "RESERVED" 216 "RESERVED" 217 "RESERVED" 218 "RESERVED" 219 "RESERVED" 220 "RESERVED" 221 "RESERVED" 222 "RESERVED" 223 "RESERVED" 224 "RESERVED" 225 "RESERVED" 226 "RESERVED" 227 "RESERVED" 228 "RESERVED" 229 "RESERVED" 230 "RESERVED" 231 "RESERVED" 232 "RESERVED" 233 "RESERVED" 234 "RESERVED" 235 "RESERVED" 236 "RESERVED" 237 "RESERVED" 238 "RESERVED" 239 "RESERVED" 240 "RESERVED" 241 "RESERVED" 242 "RESERVED" 243 "RESERVED" 244 "RESERVED" 245 "RESERVED" 246 "RESERVED" 247 "RESERVED" 248 "RESERVED" 249 "RESERVED" 250 "RESERVED" 251 "RESERVED" 252 "RESERVED" 253 "RESERVED" 254 "RESERVED" 255 "Invalid" ;
VAL_ 304 L_ATCU_CTS_RrDrEVntConsBdryLo_Y 0 "Default" 1 "0x01~0xC0:PHY=HEX*10 + 0" 192 "0x01~0xC0:PHY=HEX*10 + 0" 193 "RESERVED" 194 "RESERVED" 195 "RESERVED" 196 "RESERVED" 197 "RESERVED" 198 "RESERVED" 199 "RESERVED" 200 "RESERVED" 201 "RESERVED" 202 "RESERVED" 203 "RESERVED" 204 "RESERVED" 205 "RESERVED" 206 "RESERVED" 207 "RESERVED" 208 "RESERVED" 209 "RESERVED" 210 "RESERVED" 211 "RESERVED" 212 "RESERVED" 213 "RESERVED" 214 "RESERVED" 215 "RESERVED" 216 "RESERVED" 217 "RESERVED" 218 "RESERVED" 219 "RESERVED" 220 "RESERVED" 221 "RESERVED" 222 "RESERVED" 223 "RESERVED" 224 "RESERVED" 225 "RESERVED" 226 "RESERVED" 227 "RESERVED" 228 "RESERVED" 229 "RESERVED" 230 "RESERVED" 231 "RESERVED" 232 "RESERVED" 233 "RESERVED" 234 "RESERVED" 235 "RESERVED" 236 "RESERVED" 237 "RESERVED" 238 "RESERVED" 239 "RESERVED" 240 "RESERVED" 241 "RESERVED" 242 "RESERVED" 243 "RESERVED" 244 "RESERVED" 245 "RESERVED" 246 "RESERVED" 247 "RESERVED" 248 "RESERVED" 249 "RESERVED" 250 "RESERVED" 251 "RESERVED" 252 "RESERVED" 253 "RESERVED" 254 "RESERVED" 255 "Invalid" ;
VAL_ 304 L_ATCU_CTS_RrPsEVntConsBdryUp_X 0 "Default" 1 "0x01~0xC0:PHY=HEX*10 + 0" 192 "0x01~0xC0:PHY=HEX*10 + 0" 193 "RESERVED" 194 "RESERVED" 195 "RESERVED" 196 "RESERVED" 197 "RESERVED" 198 "RESERVED" 199 "RESERVED" 200 "RESERVED" 201 "RESERVED" 202 "RESERVED" 203 "RESERVED" 204 "RESERVED" 205 "RESERVED" 206 "RESERVED" 207 "RESERVED" 208 "RESERVED" 209 "RESERVED" 210 "RESERVED" 211 "RESERVED" 212 "RESERVED" 213 "RESERVED" 214 "RESERVED" 215 "RESERVED" 216 "RESERVED" 217 "RESERVED" 218 "RESERVED" 219 "RESERVED" 220 "RESERVED" 221 "RESERVED" 222 "RESERVED" 223 "RESERVED" 224 "RESERVED" 225 "RESERVED" 226 "RESERVED" 227 "RESERVED" 228 "RESERVED" 229 "RESERVED" 230 "RESERVED" 231 "RESERVED" 232 "RESERVED" 233 "RESERVED" 234 "RESERVED" 235 "RESERVED" 236 "RESERVED" 237 "RESERVED" 238 "RESERVED" 239 "RESERVED" 240 "RESERVED" 241 "RESERVED" 242 "RESERVED" 243 "RESERVED" 244 "RESERVED" 245 "RESERVED" 246 "RESERVED" 247 "RESERVED" 248 "RESERVED" 249 "RESERVED" 250 "RESERVED" 251 "RESERVED" 252 "RESERVED" 253 "RESERVED" 254 "RESERVED" 255 "Invalid" ;
VAL_ 304 L_ATCU_CTS_RrPsEVntConsBdryUp_Y 0 "Default" 1 "0x01~0xC0:PHY=HEX*10 + 0" 192 "0x01~0xC0:PHY=HEX*10 + 0" 193 "RESERVED" 194 "RESERVED" 195 "RESERVED" 196 "RESERVED" 197 "RESERVED" 198 "RESERVED" 199 "RESERVED" 200 "RESERVED" 201 "RESERVED" 202 "RESERVED" 203 "RESERVED" 204 "RESERVED" 205 "RESERVED" 206 "RESERVED" 207 "RESERVED" 208 "RESERVED" 209 "RESERVED" 210 "RESERVED" 211 "RESERVED" 212 "RESERVED" 213 "RESERVED" 214 "RESERVED" 215 "RESERVED" 216 "RESERVED" 217 "RESERVED" 218 "RESERVED" 219 "RESERVED" 220 "RESERVED" 221 "RESERVED" 222 "RESERVED" 223 "RESERVED" 224 "RESERVED" 225 "RESERVED" 226 "RESERVED" 227 "RESERVED" 228 "RESERVED" 229 "RESERVED" 230 "RESERVED" 231 "RESERVED" 232 "RESERVED" 233 "RESERVED" 234 "RESERVED" 235 "RESERVED" 236 "RESERVED" 237 "RESERVED" 238 "RESERVED" 239 "RESERVED" 240 "RESERVED" 241 "RESERVED" 242 "RESERVED" 243 "RESERVED" 244 "RESERVED" 245 "RESERVED" 246 "RESERVED" 247 "RESERVED" 248 "RESERVED" 249 "RESERVED" 250 "RESERVED" 251 "RESERVED" 252 "RESERVED" 253 "RESERVED" 254 "RESERVED" 255 "Invalid" ;
VAL_ 304 L_ATCU_CTS_RrPsEVntConsBdryLo_X 0 "Default" 1 "0x01~0xC0:PHY=HEX*10 + 0" 192 "0x01~0xC0:PHY=HEX*10 + 0" 193 "RESERVED" 194 "RESERVED" 195 "RESERVED" 196 "RESERVED" 197 "RESERVED" 198 "RESERVED" 199 "RESERVED" 200 "RESERVED" 201 "RESERVED" 202 "RESERVED" 203 "RESERVED" 204 "RESERVED" 205 "RESERVED" 206 "RESERVED" 207 "RESERVED" 208 "RESERVED" 209 "RESERVED" 210 "RESERVED" 211 "RESERVED" 212 "RESERVED" 213 "RESERVED" 214 "RESERVED" 215 "RESERVED" 216 "RESERVED" 217 "RESERVED" 218 "RESERVED" 219 "RESERVED" 220 "RESERVED" 221 "RESERVED" 222 "RESERVED" 223 "RESERVED" 224 "RESERVED" 225 "RESERVED" 226 "RESERVED" 227 "RESERVED" 228 "RESERVED" 229 "RESERVED" 230 "RESERVED" 231 "RESERVED" 232 "RESERVED" 233 "RESERVED" 234 "RESERVED" 235 "RESERVED" 236 "RESERVED" 237 "RESERVED" 238 "RESERVED" 239 "RESERVED" 240 "RESERVED" 241 "RESERVED" 242 "RESERVED" 243 "RESERVED" 244 "RESERVED" 245 "RESERVED" 246 "RESERVED" 247 "RESERVED" 248 "RESERVED" 249 "RESERVED" 250 "RESERVED" 251 "RESERVED" 252 "RESERVED" 253 "RESERVED" 254 "RESERVED" 255 "Invalid" ;
VAL_ 304 L_ATCU_CTS_RrPsEVntConsBdryLo_Y 0 "Default" 1 "0x01~0xC0:PHY=HEX*10 + 0" 192 "0x01~0xC0:PHY=HEX*10 + 0" 193 "RESERVED" 194 "RESERVED" 195 "RESERVED" 196 "RESERVED" 197 "RESERVED" 198 "RESERVED" 199 "RESERVED" 200 "RESERVED" 201 "RESERVED" 202 "RESERVED" 203 "RESERVED" 204 "RESERVED" 205 "RESERVED" 206 "RESERVED" 207 "RESERVED" 208 "RESERVED" 209 "RESERVED" 210 "RESERVED" 211 "RESERVED" 212 "RESERVED" 213 "RESERVED" 214 "RESERVED" 215 "RESERVED" 216 "RESERVED" 217 "RESERVED" 218 "RESERVED" 219 "RESERVED" 220 "RESERVED" 221 "RESERVED" 222 "RESERVED" 223 "RESERVED" 224 "RESERVED" 225 "RESERVED" 226 "RESERVED" 227 "RESERVED" 228 "RESERVED" 229 "RESERVED" 230 "RESERVED" 231 "RESERVED" 232 "RESERVED" 233 "RESERVED" 234 "RESERVED" 235 "RESERVED" 236 "RESERVED" 237 "RESERVED" 238 "RESERVED" 239 "RESERVED" 240 "RESERVED" 241 "RESERVED" 242 "RESERVED" 243 "RESERVED" 244 "RESERVED" 245 "RESERVED" 246 "RESERVED" 247 "RESERVED" 248 "RESERVED" 249 "RESERVED" 250 "RESERVED" 251 "RESERVED" 252 "RESERVED" 253 "RESERVED" 254 "RESERVED" 255 "Invalid" ;
VAL_ 304 L_ATCU_CTS_RrDrEVntConsBdryUp_Y 0 "Default" 1 "0x01~0xC0:PHY=HEX*10 + 0" 192 "0x01~0xC0:PHY=HEX*10 + 0" 193 "RESERVED" 194 "RESERVED" 195 "RESERVED" 196 "RESERVED" 197 "RESERVED" 198 "RESERVED" 199 "RESERVED" 200 "RESERVED" 201 "RESERVED" 202 "RESERVED" 203 "RESERVED" 204 "RESERVED" 205 "RESERVED" 206 "RESERVED" 207 "RESERVED" 208 "RESERVED" 209 "RESERVED" 210 "RESERVED" 211 "RESERVED" 212 "RESERVED" 213 "RESERVED" 214 "RESERVED" 215 "RESERVED" 216 "RESERVED" 217 "RESERVED" 218 "RESERVED" 219 "RESERVED" 220 "RESERVED" 221 "RESERVED" 222 "RESERVED" 223 "RESERVED" 224 "RESERVED" 225 "RESERVED" 226 "RESERVED" 227 "RESERVED" 228 "RESERVED" 229 "RESERVED" 230 "RESERVED" 231 "RESERVED" 232 "RESERVED" 233 "RESERVED" 234 "RESERVED" 235 "RESERVED" 236 "RESERVED" 237 "RESERVED" 238 "RESERVED" 239 "RESERVED" 240 "RESERVED" 241 "RESERVED" 242 "RESERVED" 243 "RESERVED" 244 "RESERVED" 245 "RESERVED" 246 "RESERVED" 247 "RESERVED" 248 "RESERVED" 249 "RESERVED" 250 "RESERVED" 251 "RESERVED" 252 "RESERVED" 253 "RESERVED" 254 "RESERVED" 255 "Invalid" ;
VAL_ 1025 L_EVNT_HU_FrDrEVntSidePtDisp_X 0 "Default" 1 "0x001~0x780:PHY=HEX*1 + 0" 1920 "0x001~0x780:PHY=HEX*1 + 0" 1921 "0x781~0x7FE:RESERVED" 2046 "0x781~0x7FE:RESERVED" 2047 "Invalid" ;
VAL_ 1025 L_EVNT_HU_FrDrEVntSidePtDisp_Y 0 "Default" 1 "0x001~0x780:PHY=HEX*1 + 0" 1920 "0x001~0x780:PHY=HEX*1 + 0" 1921 "0x781~0x7FE:RESERVED" 2046 "0x781~0x7FE:RESERVED" 2047 "Invalid" ;
VAL_ 1025 L_EVNT_HU_FrDrEVntCtrPtDisp_X 0 "Default" 1 "0x001~0x780:PHY=HEX*1 + 0" 1920 "0x001~0x780:PHY=HEX*1 + 0" 1921 "0x781~0x7FE:RESERVED" 2046 "0x781~0x7FE:RESERVED" 2047 "Invalid" ;
VAL_ 1025 L_EVNT_HU_FrDrEVntCtrPtDisp_Y 0 "Default" 1 "0x001~0x780:PHY=HEX*1 + 0" 1920 "0x001~0x780:PHY=HEX*1 + 0" 1921 "0x781~0x7FE:RESERVED" 2046 "0x781~0x7FE:RESERVED" 2047 "Invalid" ;
VAL_ 1026 L_EVNT_HU_FrPsEVntSidePtDisp_X 0 "Default" 1 "0x001~0x780:PHY=HEX*1 + 0" 1920 "0x001~0x780:PHY=HEX*1 + 0" 1921 "0x781~0x7FE:RESERVED" 2046 "0x781~0x7FE:RESERVED" 2047 "Invalid" ;
VAL_ 1026 L_EVNT_HU_FrPsEVntSidePtDisp_Y 0 "Default" 1 "0x001~0x780:PHY=HEX*1 + 0" 1920 "0x001~0x780:PHY=HEX*1 + 0" 1921 "0x781~0x7FE:RESERVED" 2046 "0x781~0x7FE:RESERVED" 2047 "Invalid" ;
VAL_ 1026 L_EVNT_HU_FrPsEVntCtrPtDisp_X 0 "Default" 1 "0x001~0x780:PHY=HEX*1 + 0" 1920 "0x001~0x780:PHY=HEX*1 + 0" 1921 "0x781~0x7FE:RESERVED" 2046 "0x781~0x7FE:RESERVED" 2047 "Invalid" ;
VAL_ 1026 L_EVNT_HU_FrPsEVntCtrPtDisp_Y 0 "Default" 1 "0x001~0x780:PHY=HEX*1 + 0" 1920 "0x001~0x780:PHY=HEX*1 + 0" 1921 "0x781~0x7FE:RESERVED" 2046 "0x781~0x7FE:RESERVED" 2047 "Invalid" ;
VAL_ 1027 L_EVNT_HU_RrDrEVntConsPtDisp_X 0 "Default" 1 "0x001~0x780:PHY=HEX*1 + 0" 1920 "0x001~0x780:PHY=HEX*1 + 0" 1921 "0x781~0x7FE:RESERVED" 2046 "0x781~0x7FE:RESERVED" 2047 "Invalid" ;
VAL_ 1027 L_EVNT_HU_RrDrEVntConsPtDisp_Y 0 "Default" 1 "0x001~0x780:PHY=HEX*1 + 0" 1920 "0x001~0x780:PHY=HEX*1 + 0" 1921 "0x781~0x7FE:RESERVED" 2046 "0x781~0x7FE:RESERVED" 2047 "Invalid" ;
VAL_ 1027 L_EVNT_HU_RrPsEVntConsPtDisp_X 0 "Default" 1 "0x001~0x780:PHY=HEX*1 + 0" 1920 "0x001~0x780:PHY=HEX*1 + 0" 1921 "0x781~0x7FE:RESERVED" 2046 "0x781~0x7FE:RESERVED" 2047 "Invalid" ;
VAL_ 1027 L_EVNT_HU_RrPsEVntConsPtDisp_Y 0 "Default" 1 "0x001~0x780:PHY=HEX*1 + 0" 1920 "0x001~0x780:PHY=HEX*1 + 0" 1921 "0x781~0x7FE:RESERVED" 2046 "0x781~0x7FE:RESERVED" 2047 "Invalid" ;
VAL_ 1027 L_EVNT_FrDrEVntSideFlt 0 "Default" 1 "No Error" 2 "Error" 3 "Error Indicator" ;
VAL_ 1027 L_EVNT_FrDrEVntCtrFlt 0 "Default" 1 "No Error" 2 "Error" 3 "Error Indicator" ;
VAL_ 1027 L_EVNT_FrPsEVntSideFlt 0 "Default" 1 "No Error" 2 "Error" 3 "Error Indicator" ;
VAL_ 1027 L_EVNT_FrPsEVntCtrFlt 0 "Default" 1 "No Error" 2 "Error" 3 "Error Indicator" ;
VAL_ 1027 L_EVNT_RrDrEVntConsFlt 0 "Default" 1 "No Error" 2 "Error" 3 "Error Indicator" ;
VAL_ 1027 L_EVNT_RrPsEVntConsFlt 0 "Default" 1 "No Error" 2 "Error" 3 "Error Indicator" ;
VAL_ 1028 L_EVNT_FrDrEVntModeSet_Disp 0 "Default" 1 "FOCUS Mode" 2 "SPREAD Mode" 3 "CYCLE Mode" 4 "Manual Mode" 5 "OFF" 6 "RESERVED" 7 "RESERVED" 8 "RESERVED" 9 "RESERVED" 10 "RESERVED" 11 "RESERVED" 12 "RESERVED" 13 "RESERVED" 14 "RESERVED" 15 "Invalid" ;
VAL_ 1028 L_EVNT_RrPsEVntModeSet_Disp 0 "Default" 1 "FOCUS Mode" 2 "SPREAD Mode" 3 "CYCLE Mode" 4 "Manual Mode" 5 "OFF" 6 "RESERVED" 7 "RESERVED" 8 "RESERVED" 9 "RESERVED" 10 "RESERVED" 11 "RESERVED" 12 "RESERVED" 13 "RESERVED" 14 "RESERVED" 15 "Invalid" ;
VAL_ 1028 L_EVNT_FrDrEVntSideOpnClsDisp 0 "Default" 1 "OPEN" 2 "CLOSE" 3 "Invalid" ;
VAL_ 1028 L_EVNT_FrDrEVntCtrOpnClsDisp 0 "Default" 1 "OPEN" 2 "CLOSE" 3 "Invalid" ;
VAL_ 1028 L_EVNT_FrPsEVntSideOpnClsDisp 0 "Default" 1 "OPEN" 2 "CLOSE" 3 "Invalid" ;
VAL_ 1028 L_EVNT_FrPsEVntCtrOpnClsDisp 0 "Default" 1 "OPEN" 2 "CLOSE" 3 "Invalid" ;
VAL_ 1028 L_EVNT_RrDrEVntConsOpnClsDisp 0 "Default" 1 "OPEN" 2 "CLOSE" 3 "Invalid" ;
VAL_ 1028 L_EVNT_RrPsEVntConsOpnClsDisp 0 "Default" 1 "OPEN" 2 "CLOSE" 3 "Invalid" ;
VAL_ 1028 L_EVNT_EVntTouchInform_HU 0 "Default" 1 "APPLY" 2 "NOT APPLY" 3 "Invalid" ;
VAL_ 1028 L_EVNT_EVntTouchInform_CTS 0 "Default" 1 "APPLY" 2 "NOT APPLY" 3 "Invalid" ;
VAL_ 1028 L_EVNT_FrPsEVntModeSet_Disp 0 "Default" 1 "FOCUS Mode" 2 "SPREAD Mode" 3 "CYCLE Mode" 4 "Manual Mode" 5 "OFF" 6 "RESERVED" 7 "RESERVED" 8 "RESERVED" 9 "RESERVED" 10 "RESERVED" 11 "RESERVED" 12 "RESERVED" 13 "RESERVED" 14 "RESERVED" 15 "Invalid" ;
VAL_ 1028 L_EVNT_RrDrEVntModeSet_Disp 0 "Default" 1 "FOCUS Mode" 2 "SPREAD Mode" 3 "CYCLE Mode" 4 "Manual Mode" 5 "OFF" 6 "RESERVED" 7 "RESERVED" 8 "RESERVED" 9 "RESERVED" 10 "RESERVED" 11 "RESERVED" 12 "RESERVED" 13 "RESERVED" 14 "RESERVED" 15 "Invalid" ;
VAL_ 1029 L_EVNT_CTS_FrDrEVntSidePtDisp_X 0 "Default" 1 "0x001~0x780:PHY=HEX*1 + 0" 1920 "0x001~0x780:PHY=HEX*1 + 0" 1921 "0x781~0x7FE:RESERVED" 2046 "0x781~0x7FE:RESERVED" 2047 "Invalid" ;
VAL_ 1029 L_EVNT_CTS_FrDrEVntSidePtDisp_Y 0 "Default" 1 "0x001~0x780:PHY=HEX*1 + 0" 1920 "0x001~0x780:PHY=HEX*1 + 0" 1921 "0x781~0x7FE:RESERVED" 2046 "0x781~0x7FE:RESERVED" 2047 "Invalid" ;
VAL_ 1029 L_EVNT_CTS_FrDrEVntCtrPtDisp_X 0 "Default" 1 "0x001~0x780:PHY=HEX*1 + 0" 1920 "0x001~0x780:PHY=HEX*1 + 0" 1921 "0x781~0x7FE:RESERVED" 2046 "0x781~0x7FE:RESERVED" 2047 "Invalid" ;
VAL_ 1029 L_EVNT_CTS_FrDrEVntCtrPtDisp_Y 0 "Default" 1 "0x001~0x780:PHY=HEX*1 + 0" 1920 "0x001~0x780:PHY=HEX*1 + 0" 1921 "0x781~0x7FE:RESERVED" 2046 "0x781~0x7FE:RESERVED" 2047 "Invalid" ;
VAL_ 1030 L_EVNT_CTS_FrPsEVntSidePtDisp_X 0 "Default" 1 "0x001~0x780:PHY=HEX*1 + 0" 1920 "0x001~0x780:PHY=HEX*1 + 0" 1921 "0x781~0x7FE:RESERVED" 2046 "0x781~0x7FE:RESERVED" 2047 "Invalid" ;
VAL_ 1030 L_EVNT_CTS_FrPsEVntSidePtDisp_Y 0 "Default" 1 "0x001~0x780:PHY=HEX*1 + 0" 1920 "0x001~0x780:PHY=HEX*1 + 0" 1921 "0x781~0x7FE:RESERVED" 2046 "0x781~0x7FE:RESERVED" 2047 "Invalid" ;
VAL_ 1030 L_EVNT_CTS_FrPsEVntCtrPtDisp_X 0 "Default" 1 "0x001~0x780:PHY=HEX*1 + 0" 1920 "0x001~0x780:PHY=HEX*1 + 0" 1921 "0x781~0x7FE:RESERVED" 2046 "0x781~0x7FE:RESERVED" 2047 "Invalid" ;
VAL_ 1030 L_EVNT_CTS_FrPsEVntCtrPtDisp_Y 0 "Default" 1 "0x001~0x780:PHY=HEX*1 + 0" 1920 "0x001~0x780:PHY=HEX*1 + 0" 1921 "0x781~0x7FE:RESERVED" 2046 "0x781~0x7FE:RESERVED" 2047 "Invalid" ;
VAL_ 1031 L_EVNT_CTS_RrDrEVntConsPtDisp_X 0 "Default" 1 "0x001~0x780:PHY=HEX*1 + 0" 1920 "0x001~0x780:PHY=HEX*1 + 0" 1921 "0x781~0x7FE:RESERVED" 2046 "0x781~0x7FE:RESERVED" 2047 "Invalid" ;
VAL_ 1031 L_EVNT_CTS_RrDrEVntConsPtDisp_Y 0 "Default" 1 "0x001~0x780:PHY=HEX*1 + 0" 1920 "0x001~0x780:PHY=HEX*1 + 0" 1921 "0x781~0x7FE:RESERVED" 2046 "0x781~0x7FE:RESERVED" 2047 "Invalid" ;
VAL_ 1031 L_EVNT_CTS_RrPsEVntConsPtDisp_X 0 "Default" 1 "0x001~0x780:PHY=HEX*1 + 0" 1920 "0x001~0x780:PHY=HEX*1 + 0" 1921 "0x781~0x7FE:RESERVED" 2046 "0x781~0x7FE:RESERVED" 2047 "Invalid" ;
VAL_ 1031 L_EVNT_CTS_RrPsEVntConsPtDisp_Y 0 "Default" 1 "0x001~0x780:PHY=HEX*1 + 0" 1920 "0x001~0x780:PHY=HEX*1 + 0" 1921 "0x781~0x7FE:RESERVED" 2046 "0x781~0x7FE:RESERVED" 2047 "Invalid" ;
VAL_ 1032 L_EVNT_ATCUComFlt 0 "Default" 1 "No Error" 2 "Error" 3 "Error Indicator" ;
VAL_ 1032 L_EVNT_DrvCntrHorComFlt 0 "Default" 1 "No Error" 2 "Error" 3 "Error Indicator" ;
VAL_ 1032 L_EVNT_AstSdVertComFlt 0 "Default" 1 "No Error" 2 "Error" 3 "Error Indicator" ;
VAL_ 1032 L_EVNT_AstSdHorComFlt 0 "Default" 1 "No Error" 2 "Error" 3 "Error Indicator" ;
VAL_ 1032 L_EVNT_AstCntrVertComFlt 0 "Default" 1 "No Error" 2 "Error" 3 "Error Indicator" ;
VAL_ 1032 L_EVNT_AstCntrHorComFlt 0 "Default" 1 "No Error" 2 "Error" 3 "Error Indicator" ;
VAL_ 1032 L_EVNT_EVNTFlt 0 "Default" 1 "No Error" 2 "Error" 3 "Error Indicator" ;
VAL_ 1032 L_EVNT_RrDrvCnslVertComFlt 0 "Default" 1 "No Error" 2 "Error" 3 "Error Indicator" ;
VAL_ 1032 L_EVNT_RrDrvCnslHorComFlt 0 "Default" 1 "No Error" 2 "Error" 3 "Error Indicator" ;
VAL_ 1032 L_EVNT_RrAstCnslVertComFlt 0 "Default" 1 "No Error" 2 "Error" 3 "Error Indicator" ;
VAL_ 1032 L_EVNT_RrAstCnslHorComFlt 0 "Default" 1 "No Error" 2 "Error" 3 "Error Indicator" ;
VAL_ 1032 L_EVNT_DrvSdVertIntFlt 0 "Default" 1 "No Error" 2 "Error" 3 "Error Indicator" ;
VAL_ 1032 L_EVNT_DrvSdHorIntFlt 0 "Default" 1 "No Error" 2 "Error" 3 "Error Indicator" ;
VAL_ 1032 L_EVNT_DrvCntrVertIntFlt 0 "Default" 1 "No Error" 2 "Error" 3 "Error Indicator" ;
VAL_ 1032 L_EVNT_DrvCntrHorIntFlt 0 "Default" 1 "No Error" 2 "Error" 3 "Error Indicator" ;
VAL_ 1032 L_EVNT_AstSdVertIntFlt 0 "Default" 1 "No Error" 2 "Error" 3 "Error Indicator" ;
VAL_ 1032 L_EVNT_AstSdHorIntFlt 0 "Default" 1 "No Error" 2 "Error" 3 "Error Indicator" ;
VAL_ 1032 L_EVNT_DrvSdVertComFlt 0 "Default" 1 "No Error" 2 "Error" 3 "Error Indicator" ;
VAL_ 1032 L_EVNT_AstCntrVertIntFlt 0 "Default" 1 "No Error" 2 "Error" 3 "Error Indicator" ;
VAL_ 1032 L_EVNT_AstCntrHorIntFlt 0 "Default" 1 "No Error" 2 "Error" 3 "Error Indicator" ;
VAL_ 1032 L_EVNT_RrDrvCnslVertIntFlt 0 "Default" 1 "No Error" 2 "Error" 3 "Error Indicator" ;
VAL_ 1032 L_EVNT_RrDrvCnslHorIntFlt 0 "Default" 1 "No Error" 2 "Error" 3 "Error Indicator" ;
VAL_ 1032 L_EVNT_RrAstCnslVertIntFlt 0 "Default" 1 "No Error" 2 "Error" 3 "Error Indicator" ;
VAL_ 1032 L_EVNT_RrAstCnslHorIntFlt 0 "Default" 1 "No Error" 2 "Error" 3 "Error Indicator" ;
VAL_ 1032 L_EVNT_DrvSdVertExtFlt 0 "Default" 1 "No Error" 2 "Error" 3 "Error Indicator" ;
VAL_ 1032 L_EVNT_DrvSdHorExtFlt 0 "Default" 1 "No Error" 2 "Error" 3 "Error Indicator" ;
VAL_ 1032 L_EVNT_DrvCntrVertExtFlt 0 "Default" 1 "No Error" 2 "Error" 3 "Error Indicator" ;
VAL_ 1032 L_EVNT_DrvCntrHorExtFlt 0 "Default" 1 "No Error" 2 "Error" 3 "Error Indicator" ;
VAL_ 1032 L_EVNT_DrvSdHorComFlt 0 "Default" 1 "No Error" 2 "Error" 3 "Error Indicator" ;
VAL_ 1032 L_EVNT_AstSdVertExtFlt 0 "Default" 1 "No Error" 2 "Error" 3 "Error Indicator" ;
VAL_ 1032 L_EVNT_AstSdHorExtFlt 0 "Default" 1 "No Error" 2 "Error" 3 "Error Indicator" ;
VAL_ 1032 L_EVNT_DrvCntrVertComFlt 0 "Default" 1 "No Error" 2 "Error" 3 "Error Indicator" ;
VAL_ 1033 L_EVNT_AstCntrVertExtFlt 0 "Default" 1 "No Error" 2 "Error" 3 "Error Indicator" ;
VAL_ 1033 L_EVNT_RrAstCnslHorExtFlt 0 "Default" 1 "No Error" 2 "Error" 3 "Error Indicator" ;
VAL_ 1033 L_EVNT_AstCntrHorExtFlt 0 "Default" 1 "No Error" 2 "Error" 3 "Error Indicator" ;
VAL_ 1033 L_EVNT_RrDrvCnslVertExtFlt 0 "Default" 1 "No Error" 2 "Error" 3 "Error Indicator" ;
VAL_ 1033 L_EVNT_RrDrvCnslHorExtFlt 0 "Default" 1 "No Error" 2 "Error" 3 "Error Indicator" ;
VAL_ 1033 L_EVNT_ResetOpSta 0 "Normal" 1 "Reset Complete" 2 "Reset Fail" 3 "RESERVED" ;
VAL_ 1033 L_EVNT_RrAstCnslVertExtFlt 0 "Default" 1 "No Error" 2 "Error" 3 "Error Indicator" ;
